VERSION ""

NS_ :

BS_:

BU_: TCM iBooster HCU CIM SCM Right_Hand_Control Left_Hand_Control GPS VCM IC_2 XM GMRS Radio_CANtool Diagnostic_Tool_Digital_Wrench Information_System_Controller_1 STEERING_CONTROLLER VEHICLE_SECURITY RADIO_Hub ABS Battery_Management_Cntrl_2 Battery_Management_Cntrl_1 Auxiliary_Power_Unit_2 Auxiliary_Power_Unit_1 Electric_Propulsion_Cntrl_Unit_4 Electric_Propulsion_Cntrl_Unit_3 Electric_Propulsion_Cntrl_Unit_2 Electric_Propulsion_Cntrl_Unit_1 ECM IC

BO_ 2566910976 FlagItems_2_0: 8 ECM
 SG_ FI2_ThrttlBdyInitLrnValSave : 52|2@1+ (1,0) [0|3] "" Vector__XXX
 SG_ FI2_ThrttlBdyInitLearnSuccess : 54|2@1+ (1,0) [0|3] "" Vector__XXX
 SG_ FI2_ThrottleLimpHomeOpCondition : 46|2@1+ (1,0) [0|3] "" Vector__XXX
 SG_ FI2_SystemOnInput : 42|2@1+ (1,0) [0|3] "" Vector__XXX
 SG_ FI2_SftyFuelCutoffCndn : 56|2@1+ (1,0) [0|3] "" Vector__XXX
 SG_ FI2_RvrsblInjCutoffCndn : 58|2@1+ (1,0) [0|3] "" Vector__XXX
 SG_ FI2_PTOEngagementStatus : 38|2@1+ (1,0) [0|3] "" Vector__XXX
 SG_ FI2_ParkBrakeSwitchIn : 36|2@1+ (1,0) [0|3] "" Vector__XXX
 SG_ FI2_NeutralSwitchIn : 44|2@1+ (1,0) [0|3] "" Vector__XXX
 SG_ FI2_IrrvrsblInjCutoffCndn : 60|2@1+ (1,0) [0|3] "" Vector__XXX
 SG_ FI2_ETCFncnMonitor : 62|2@1+ (1,0) [0|3] "" Vector__XXX
 SG_ FI2_ADCOutput : 0|2@1+ (1,0) [0|3] "" Vector__XXX
 SG_ FI2_RearDiffLockOutput : 2|2@1+ (1,0) [0|3] "" Vector__XXX
 SG_ FI2_AWDOutput : 4|2@1+ (1,0) [0|3] "" Vector__XXX
 SG_ FI2_BrakeSwitchInput : 8|2@1+ (1,0) [0|3] "" Vector__XXX
 SG_ FI2_ADCSwitchInput : 10|2@1+ (1,0) [0|3] "" Vector__XXX
 SG_ FI2_TurfModeInput : 12|2@1+ (1,0) [0|3] "" Vector__XXX
 SG_ FI2_AWDSwitchInput : 14|2@1+ (1,0) [0|3] "" Vector__XXX
 SG_ FI2_ReverseSwitchInput : 16|2@1+ (1,0) [0|3] "" Vector__XXX
 SG_ FI2_ReverseLimitSwitchInput : 18|2@1+ (1,0) [0|3] "" Vector__XXX
 SG_ FI2_ForwardLimitSwitchInput : 20|2@1+ (1,0) [0|3] "" Vector__XXX
 SG_ FI2_EngineDirection : 22|2@1+ (1,0) [0|3] "" Vector__XXX
 SG_ FI2_RevSpeedLimitOverrideInput : 24|2@1+ (1,0) [0|3] "" Vector__XXX
 SG_ FI2_ReverseOverspeedSignal : 26|2@1+ (1,0) [0|3] "" Vector__XXX
 SG_ FI2_RightTurnSignalInput : 32|2@1+ (1,0) [0|3] "" Vector__XXX
 SG_ FI2_LeftTurnSignalInput : 34|2@1+ (1,0) [0|3] "" Vector__XXX
 SG_ FI2_KickstandSwitchInput : 40|2@1+ (1,0) [0|3] "" Vector__XXX
 SG_ FI2_ReflashEnableInputSignal : 48|2@1+ (1,0) [0|3] "" Vector__XXX
 SG_ FI2_TPSLearnInputSignal : 50|2@1+ (1,0) [0|3] "" Vector__XXX
 SG_ FI2_LowRangeSwitchInput : 30|2@1+ (1,0) [0|3] "" Vector__XXX
 SG_ FI2_ReverseMotorDriveInput : 28|2@1+ (1,0) [0|3] "" Vector__XXX

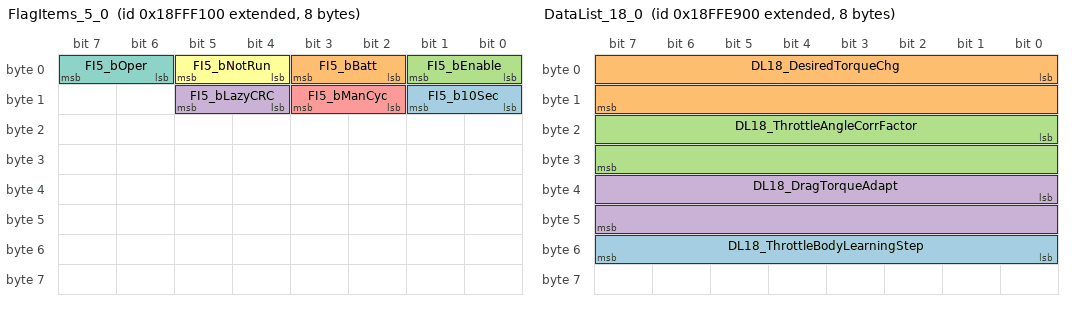
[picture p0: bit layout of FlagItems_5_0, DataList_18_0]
BO_ 2566910208 FlagItems_5_0: 8 ECM
 SG_ FI5_b10Sec : 8|2@1+ (1,0) [0|3] "Binary" Vector__XXX
 SG_ FI5_bBatt : 2|2@1+ (1,0) [0|3] "Binary" Vector__XXX
 SG_ FI5_bEnable : 0|2@1+ (1,0) [0|3] "Binary" Vector__XXX
 SG_ FI5_bLazyCRC : 12|2@1+ (1,0) [0|3] "Binary" Vector__XXX
 SG_ FI5_bManCyc : 10|2@1+ (1,0) [0|3] "Binary" Vector__XXX
 SG_ FI5_bNotRun : 4|2@1+ (1,0) [0|3] "Binary" Vector__XXX
 SG_ FI5_bOper : 6|2@1+ (1,0) [0|3] "Binary" Vector__XXX

BO_ 2566908160 DataList_18_0: 8 ECM
 SG_ DL18_ThrottleBodyLearningStep : 48|8@1+ (1,0) [0|11] "Steps" Vector__XXX
 SG_ DL18_DesiredTorqueChg : 0|16@1+ (0.0030518,-100) [-100|99.999713] "%" Vector__XXX
 SG_ DL18_ThrottleAngleCorrFactor : 16|16@1+ (6.1036E-005,0) [0|3.99999426] "" Vector__XXX
 SG_ DL18_DragTorqueAdapt : 32|16@1+ (0.0030518,-100) [-100|99.999713] "%" Vector__XXX

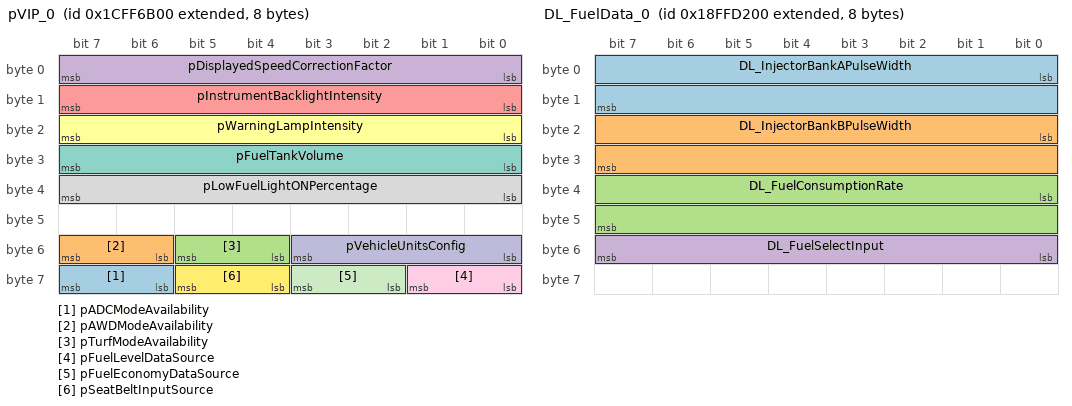
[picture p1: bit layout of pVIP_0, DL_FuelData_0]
BO_ 2633984768 pVIP_0: 8 ECM
 SG_ pADCModeAvailability : 62|2@1+ (1,0) [0|3] "" Vector__XXX
 SG_ pAWDModeAvailability : 54|2@1+ (1,0) [0|3] "" Vector__XXX
 SG_ pTurfModeAvailability : 52|2@1+ (1,0) [0|3] "" Vector__XXX
 SG_ pDisplayedSpeedCorrectionFactor : 0|8@1+ (0.8,-100) [-100|100] "%" Vector__XXX
 SG_ pInstrumentBacklightIntensity : 8|8@1+ (0.4,0) [0|100] "%" Vector__XXX
 SG_ pWarningLampIntensity : 16|8@1+ (0.4,0) [0|100] "%" Vector__XXX
 SG_ pFuelTankVolume : 24|8@1+ (0.5,0) [0|125] "Liters" Vector__XXX
 SG_ pLowFuelLightONPercentage : 32|8@1+ (0.4,0) [0|100] "Percent" Vector__XXX
 SG_ pFuelLevelDataSource : 56|2@1+ (1,0) [0|3] "" Vector__XXX
 SG_ pVehicleUnitsConfig : 48|4@1+ (1,0) [0|15] "" Vector__XXX
 SG_ pFuelEconomyDataSource : 58|2@1+ (1,0) [0|3] "" Vector__XXX
 SG_ pSeatBeltInputSource : 60|2@1+ (1,0) [0|3] "" Vector__XXX

BO_ 2566902272 DL_FuelData_0: 8 ECM
 SG_ DL_InjectorBankAPulseWidth : 0|16@1+ (0.007813,0) [0|511.99] "ms" Vector__XXX
 SG_ DL_InjectorBankBPulseWidth : 16|16@1+ (0.007813,0) [0|511.99] "ms" Vector__XXX
 SG_ DL_FuelConsumptionRate : 32|16@1+ (0.0039,0) [0|255.5865] "GPH" Vector__XXX
 SG_ DL_FuelSelectInput : 48|8@1+ (0.01953,0) [0|4.98015] "V" Vector__XXX

BO_ 2566910720 FlagItems_3_0: 8 ECM
 SG_ FI3_OilPressSwIn : 62|2@1+ (1,0) [0|3] "" Vector__XXX
 SG_ FI3_BrkSw2In : 60|2@1+ (1,0) [0|3] "" Vector__XXX
 SG_ FI3_CruiseCtrlResumeOut : 54|2@1+ (1,0) [0|3] "" Vector__XXX
 SG_ FI3_CruiseCtrlResumeIn : 56|2@1+ (1,0) [0|3] "" Vector__XXX
 SG_ FI3_CruiseCtrlCancelIn : 58|2@1+ (1,0) [0|3] "" Vector__XXX
 SG_ FI3_TetherSwStatus : 38|2@1+ (1,0) [0|3] "" Vector__XXX
 SG_ FI3_DriveMode1Input : 0|2@1+ (1,0) [0|3] "" Vector__XXX
 SG_ FI3_DriveMode2Input : 2|2@1+ (1,0) [0|3] "" Vector__XXX
 SG_ FI3_DriveMode3Input : 4|2@1+ (1,0) [0|3] "" Vector__XXX
 SG_ FI3_DriverMode4Input : 6|2@1+ (1,0) [0|3] "" Vector__XXX
 SG_ FI3_DriverMode1Output : 8|2@1+ (1,0) [0|3] "" Vector__XXX
 SG_ FI3_DriverMode2Output : 10|2@1+ (1,0) [0|3] "" Vector__XXX
 SG_ FI3_DriverMode3Output : 12|2@1+ (1,0) [0|3] "" Vector__XXX
 SG_ FI3_DriverMode4Ouput : 14|2@1+ (1,0) [0|3] "" Vector__XXX
 SG_ FI3_PTOModeInput : 16|2@1+ (1,0) [0|3] "" Vector__XXX
 SG_ FI3_PTOModeOutput : 18|2@1+ (1,0) [0|3] "" Vector__XXX
 SG_ FI3_DriversNetEngagement : 20|2@1+ (1,0) [0|3] "" Vector__XXX
 SG_ FI3_DriversSeatbeltEngagement : 22|2@1+ (1,0) [0|3] "" Vector__XXX
 SG_ FI3_TiltLockInput : 24|2@1+ (1,0) [0|3] "" Vector__XXX
 SG_ FI3_WorkGroupLockInput : 26|2@1+ (1,0) [0|3] "" Vector__XXX
 SG_ FI3_OperatorPresenceInput : 28|2@1+ (1,0) [0|3] "" Vector__XXX
 SG_ FI3_WorkGroupLockOutput : 34|2@1+ (1,0) [0|3] "" Vector__XXX
 SG_ FI3_OperatorPresenceOutput : 36|2@1+ (1,0) [0|3] "" Vector__XXX
 SG_ FI3_FootOnCruiseInput : 40|2@1+ (1,0) [0|3] "" Vector__XXX
 SG_ FI3_CruiseInput : 42|2@1+ (1,0) [0|3] "" Vector__XXX
 SG_ FI3_TredalInput : 44|2@1+ (1,0) [0|3] "" Vector__XXX
 SG_ FI3_CruiseSpeedInput : 46|2@1+ (1,0) [0|3] "" Vector__XXX
 SG_ FI3_FootOnCruiseOutput : 48|2@1+ (1,0) [0|3] "" Vector__XXX
 SG_ FI3_CruiseOutput : 50|2@1+ (1,0) [0|3] "" Vector__XXX
 SG_ FI3_CruiseControltoSetSpeed : 52|2@1+ (1,0) [0|0] "" Vector__XXX
 SG_ FI3_WorkModeInput : 30|2@1+ (1,0) [0|3] "" Vector__XXX
 SG_ FI3_TiltLockOutput : 32|2@1+ (1,0) [0|3] "" Vector__XXX

BO_ 2566910464 FlagItems_4_0: 8 ECM
 SG_ FI4_SeatbeltSw : 60|2@1+ (1,0) [0|3] "" Vector__XXX
 SG_ FI4_pSideStandSw : 52|2@1+ (1,0) [0|3] "" Vector__XXX
 SG_ FI4_DrvlnMomentaryRight : 58|2@1+ (1,0) [0|3] "" Vector__XXX
 SG_ FI4_DrvlnMomentaryLeft : 56|2@1+ (1,0) [0|3] "" Vector__XXX
 SG_ FI4_BrakeLightOutput : 30|2@1+ (1,0) [0|3] "" Vector__XXX
 SG_ FI4_FogLightInput : 4|2@1+ (1,0) [0|3] "" Vector__XXX
 SG_ FI4_HazardLightOutput : 26|2@1+ (1,0) [0|3] "" Vector__XXX
 SG_ FI4_HazardSWInput : 0|2@1+ (1,0) [0|3] "" Vector__XXX
 SG_ FI4_HeatGripDecSW : 46|2@1+ (1,0) [0|3] "" Vector__XXX
 SG_ FI4_HeatGripIncSW : 44|2@1+ (1,0) [0|3] "" Vector__XXX
 SG_ FI4_HighBeamOutput : 8|2@1+ (1,0) [0|3] "" Vector__XXX
 SG_ FI4_HornInput : 6|2@1+ (1,0) [0|3] "" Vector__XXX
 SG_ FI4_HornOutput : 24|2@1+ (1,0) [0|3] "" Vector__XXX
 SG_ FI4_LeftFogLightOutput : 12|2@1+ (1,0) [0|3] "" Vector__XXX
 SG_ FI4_LFTurnSignalOutput : 32|2@1+ (1,0) [0|3] "" Vector__XXX
 SG_ FI4_LockInput : 18|2@1+ (1,0) [0|3] "" Vector__XXX
 SG_ FI4_LowBeamOutput : 10|2@1+ (1,0) [0|3] "" Vector__XXX
 SG_ FI4_LowHighBeamInput : 2|2@1+ (1,0) [0|3] "" Vector__XXX
 SG_ FI4_LRTurnSignalOutput : 36|2@1+ (1,0) [0|3] "" Vector__XXX
 SG_ FI4_pOperatorButton1 : 48|2@1+ (1,0) [0|3] "" Vector__XXX
 SG_ FI4_RFTurnSignalOutput : 34|2@1+ (1,0) [0|3] "" Vector__XXX
 SG_ FI4_RightFogLightOutput : 14|2@1+ (1,0) [0|3] "" Vector__XXX
 SG_ FI4_RRTurnSignalOutput : 38|2@1+ (1,0) [0|3] "" Vector__XXX
 SG_ FI4_SecondaryAirValveCmd : 42|2@1+ (1,0) [0|3] "" Vector__XXX
 SG_ FI4_SecondaryAirValveOut : 40|2@1+ (1,0) [0|3] "" Vector__XXX
 SG_ FI4_TailLightOutput : 28|2@1+ (1,0) [0|3] "" Vector__XXX
 SG_ FI4_UnlockInput : 16|2@1+ (1,0) [0|3] "" Vector__XXX
 SG_ FI4_WindshieldSWDownInput : 22|2@1+ (1,0) [0|3] "" Vector__XXX
 SG_ FI4_WindshieldSWUpInput : 20|2@1+ (1,0) [0|3] "" Vector__XXX
 SG_ FI4_pOperatorButton2 : 50|2@1+ (1,0) [0|3] "" Vector__XXX

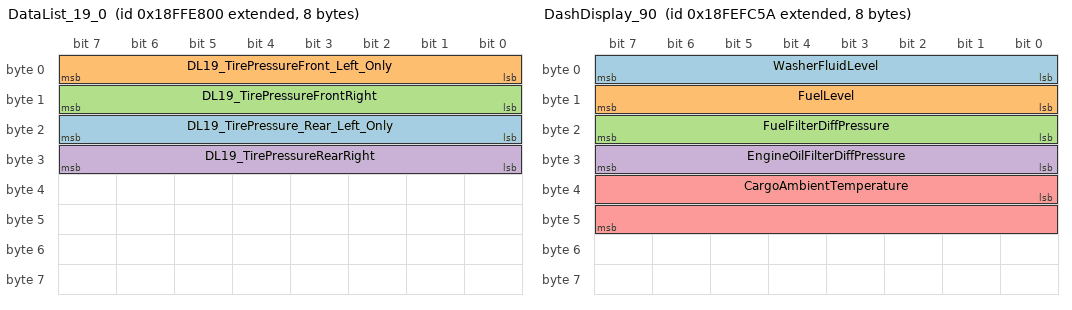
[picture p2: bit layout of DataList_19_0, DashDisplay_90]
BO_ 2566907904 DataList_19_0: 8 ECM
 SG_ DL19_TirePressure_Rear_Left_Only : 16|8@1+ (4,0) [0|1020] "kPa" Vector__XXX
 SG_ DL19_TirePressureFront_Left_Only : 0|8@1+ (4,0) [0|1020] "kPa" Vector__XXX
 SG_ DL19_TirePressureFrontRight : 8|8@1+ (4,0) [0|1020] "kPa" Vector__XXX
 SG_ DL19_TirePressureRearRight : 24|8@1+ (4,0) [0|1020] "kPa" Vector__XXX

BO_ 2566907648 DataList_20_0: 8 ECM
 SG_ DL20_KeyFobBatteryVoltage : 0|8@1+ (0.1,0) [0|25.5] "Volts" Vector__XXX
 SG_ DL20_LeanAngle : 8|8@1+ (1,-125) [-125|130] "Degrees" Vector__XXX

BO_ 2566847578 DashDisplay_90: 8 HCU
 SG_ WasherFluidLevel : 0|8@1+ (0.4,0) [0|100] "%" Vector__XXX
 SG_ FuelLevel : 8|8@1+ (0.4,0) [0|100] "%" Vector__XXX
 SG_ FuelFilterDiffPressure : 16|8@1+ (2,0) [0|500] "kPa" Vector__XXX
 SG_ EngineOilFilterDiffPressure : 24|8@1+ (0.5,0) [0|125] "kPa" Vector__XXX
 SG_ CargoAmbientTemperature : 32|16@1+ (0.03125,-273) [-273|1735] "°C" Vector__XXX

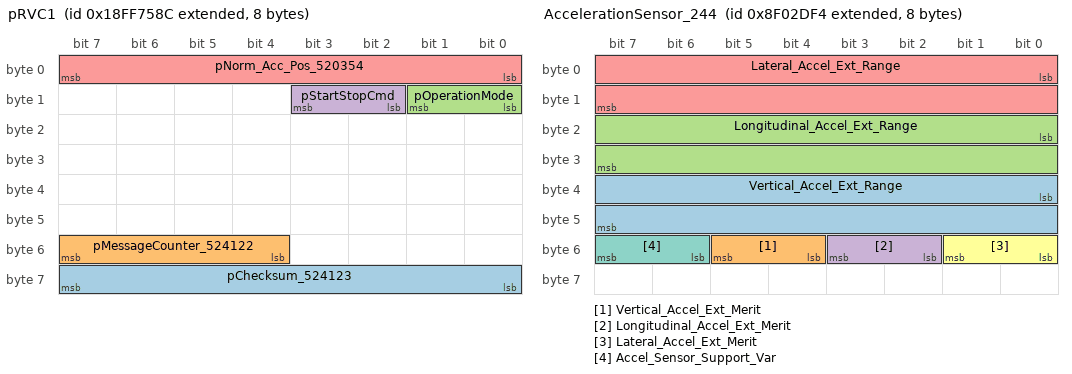
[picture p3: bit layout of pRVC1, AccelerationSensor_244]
BO_ 2566878604 pRVC1: 8 CIM
 SG_ pChecksum_524123 : 56|8@1+ (1,0) [0|255] "" Vector__XXX
 SG_ pMessageCounter_524122 : 52|4@1+ (1,0) [0|15] "" Vector__XXX
 SG_ pOperationMode : 8|2@1+ (1,0) [0|0] "" Vector__XXX
 SG_ pStartStopCmd : 10|2@1+ (1,0) [0|3] "" Vector__XXX
 SG_ pNorm_Acc_Pos_520354 : 0|8@1+ (0.4,0) [0|102] "Percent" Vector__XXX

BO_ 2566878464 pEngineControlRequests: 8 ECM
 SG_ pStartStopCmd : 10|2@1+ (1,0) [0|3] "" Vector__XXX
 SG_ pPedalPositionCommand : 0|8@1+ (0.4,0) [0|102] "%" Vector__XXX
 SG_ pOperationMode : 8|2@1+ (1,0) [0|0] "" Vector__XXX

BO_ 2566876928 pEngineRequests1: 8 ECM
 SG_ pSecondaryAirValveControl : 0|2@1+ (1,0) [0|3] "" Vector__XXX

BO_ 2566853886 pWattMessage: 8 HCU
 SG_ pRangeToEmptyEV : 16|16@1+ (0.1,0) [0|6425.5] "km" Vector__XXX
 SG_ pEfficiencyEV : 0|16@1+ (0.1,0) [0|6425.5] "Wh/km" Vector__XXX

BO_ 2566876416 pDriveModeETC: 8 ECM
 SG_ pDriveModeCommanded : 16|8@1+ (1,0) [0|255] "" Vector__XXX
 SG_ pFootOnCruiseControlEnabled : 8|2@1+ (1,0) [0|3] "" Vector__XXX
 SG_ pDriveModeRequested : 0|8@1+ (1,0) [0|255] "" Vector__XXX

BO_ 2566825472 IntakeManifoldInformation1: 8 ECM
 SG_ EngineTurbo1BoostPressure : 0|16@1+ (0.125,0) [0|8031.875] "kPa" Vector__XXX

BO_ 2566804212 VehicleElectricalPower3_244: 8 Battery_Management_Cntrl_2
 SG_ NetBattCurrentHiRange : 16|16@1+ (0.05,0) [0|3276.75] "A" Vector__XXX

BO_ 2566804211 VehicleElectricalPower3_243: 8 Battery_Management_Cntrl_1
 SG_ NetBattCurrentHiRange : 16|16@1+ (0.05,0) [0|3276.75] "A" Vector__XXX

BO_ 2297441780 AccelerationSensor_244: 8 Battery_Management_Cntrl_2
 SG_ Vertical_Accel_Ext_Range : 32|16@1+ (0.01,-320) [-320|322.55] "m/s2" Vector__XXX
 SG_ Vertical_Accel_Ext_Merit : 52|2@1+ (1,0) [0|3] "" Vector__XXX
 SG_ Longitudinal_Accel_Ext_Range : 16|16@1+ (0.01,-320) [-320|322.55] "m/s2" Vector__XXX
 SG_ Longitudinal_Accel_Ext_Merit : 50|2@1+ (1,0) [0|3] "" Vector__XXX
 SG_ Lateral_Accel_Ext_Range : 0|16@1+ (0.01,-320) [-320|322.55] "m/s2" Vector__XXX
 SG_ Lateral_Accel_Ext_Merit : 48|2@1+ (1,0) [0|3] "" Vector__XXX
 SG_ Accel_Sensor_Support_Var : 54|2@1+ (1,0) [0|3] "" Vector__XXX

BO_ 2566846452 WATT_Veh_Electrical_Pwr_244: 8 Battery_Management_Cntrl_2
 SG_ Net_Battery_Current : 0|8@1+ (1,-125) [-125|125] "A" Vector__XXX
 SG_ BatteryPotential : 16|16@1+ (0.05,0) [0|3212.75] "V" Vector__XXX

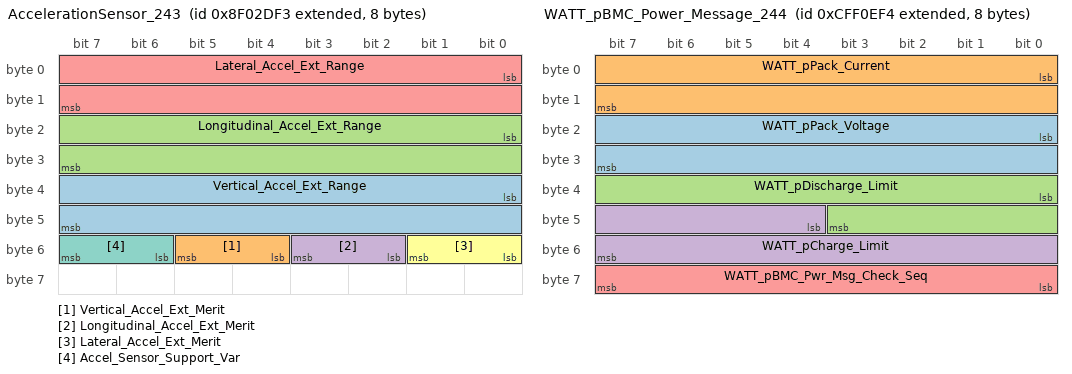
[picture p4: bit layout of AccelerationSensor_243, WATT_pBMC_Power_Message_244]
BO_ 2297441779 AccelerationSensor_243: 8 Battery_Management_Cntrl_1
 SG_ Vertical_Accel_Ext_Range : 32|16@1+ (0.01,-320) [-320|322.55] "m/s2" Vector__XXX
 SG_ Vertical_Accel_Ext_Merit : 52|2@1+ (1,0) [0|3] "" Vector__XXX
 SG_ Longitudinal_Accel_Ext_Range : 16|16@1+ (0.01,-320) [-320|322.55] "m/s2" Vector__XXX
 SG_ Longitudinal_Accel_Ext_Merit : 50|2@1+ (1,0) [0|3] "" Vector__XXX
 SG_ Lateral_Accel_Ext_Range : 0|16@1+ (0.01,-320) [-320|322.55] "m/s2" Vector__XXX
 SG_ Lateral_Accel_Ext_Merit : 48|2@1+ (1,0) [0|3] "" Vector__XXX
 SG_ Accel_Sensor_Support_Var : 54|2@1+ (1,0) [0|3] "" Vector__XXX

BO_ 2566846451 WATT_Veh_Electrical_Pwr_243: 8 Battery_Management_Cntrl_1
 SG_ Net_Battery_Current : 0|8@1+ (1,-125) [-125|125] "A" Vector__XXX
 SG_ BatteryPotential : 16|16@1+ (0.05,0) [0|3212.75] "V" Vector__XXX

BO_ 2365525748 WATT_pBMC_Power_Message_244: 8 Battery_Management_Cntrl_2
 SG_ WATT_pPack_Voltage : 16|16@1+ (0.05,0) [0|3212.75] "V" Vector__XXX
 SG_ WATT_pPack_Current : 0|16@1+ (0.05,-1600) [-1600|1612.75] "A" Vector__XXX
 SG_ WATT_pDischarge_Limit : 32|12@1+ (0.5,0) [0|2007.5] "A" Vector__XXX
 SG_ WATT_pCharge_Limit : 44|12@1+ (0.5,0) [0|2007.5] "A" Vector__XXX
 SG_ WATT_pBMC_Pwr_Msg_Check_Seq : 56|8@1+ (1,0) [0|255] "" Vector__XXX

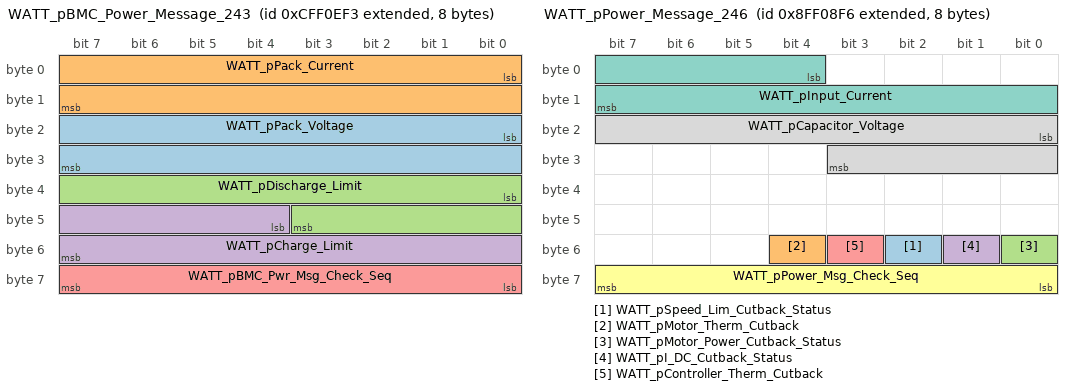
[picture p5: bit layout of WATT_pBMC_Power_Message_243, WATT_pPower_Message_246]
BO_ 2365525747 WATT_pBMC_Power_Message_243: 8 Battery_Management_Cntrl_1
 SG_ WATT_pPack_Voltage : 16|16@1+ (0.05,0) [0|3212.75] "V" Vector__XXX
 SG_ WATT_pPack_Current : 0|16@1+ (0.05,-1600) [-1600|1612.75] "A" Vector__XXX
 SG_ WATT_pDischarge_Limit : 32|12@1+ (0.5,0) [0|2007.5] "A" Vector__XXX
 SG_ WATT_pCharge_Limit : 44|12@1+ (0.5,0) [0|2007.5] "A" Vector__XXX
 SG_ WATT_pBMC_Pwr_Msg_Check_Seq : 56|8@1+ (1,0) [0|255] "" Vector__XXX

BO_ 2298415350 WATT_pPower_Message_246: 8 Auxiliary_Power_Unit_2
 SG_ WATT_pSpeed_Lim_Cutback_Status : 50|1@1+ (1,0) [0|1] "" Vector__XXX
 SG_ WATT_pMotor_Therm_Cutback : 52|1@1+ (1,0) [0|1] "" Vector__XXX
 SG_ WATT_pMotor_Power_Cutback_Status : 48|1@1+ (1,0) [0|1] "" Vector__XXX
 SG_ WATT_pI_DC_Cutback_Status : 49|1@1+ (1,0) [0|1] "" Vector__XXX
 SG_ WATT_pController_Therm_Cutback : 51|1@1+ (1,0) [0|1] "" Vector__XXX
 SG_ WATT_pPower_Msg_Check_Seq : 56|8@1+ (1,0) [0|255] "" Vector__XXX
 SG_ WATT_pInput_Current : 4|12@1+ (1,0) [0|4095] "" Vector__XXX
 SG_ WATT_pCapacitor_Voltage : 16|12@1+ (1,0) [0|4095] "" Vector__XXX

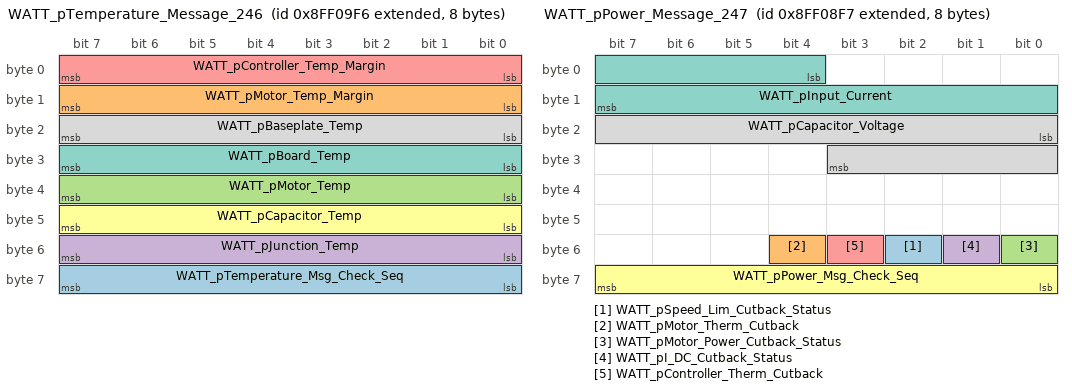
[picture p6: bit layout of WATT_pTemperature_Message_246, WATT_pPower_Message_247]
BO_ 2298415606 WATT_pTemperature_Message_246: 8 Auxiliary_Power_Unit_2
 SG_ WATT_pTemperature_Msg_Check_Seq : 56|8@1+ (1,0) [0|255] "" Vector__XXX
 SG_ WATT_pMotor_Temp_Margin : 8|8@1+ (1,0) [0|250] "C" Vector__XXX
 SG_ WATT_pMotor_Temp : 32|8@1+ (1,-40) [-40|210] "C" Vector__XXX
 SG_ WATT_pJunction_Temp : 48|8@1+ (1,-40) [-40|210] "C" Vector__XXX
 SG_ WATT_pController_Temp_Margin : 0|8@1+ (1,0) [0|250] "C" Vector__XXX
 SG_ WATT_pCapacitor_Temp : 40|8@1+ (1,-40) [-40|210] "C" Vector__XXX
 SG_ WATT_pBoard_Temp : 24|8@1+ (1,-40) [-40|210] "C" Vector__XXX
 SG_ WATT_pBaseplate_Temp : 16|8@1+ (1,-40) [-40|210] "C" Vector__XXX

BO_ 2298415351 WATT_pPower_Message_247: 8 Auxiliary_Power_Unit_1
 SG_ WATT_pSpeed_Lim_Cutback_Status : 50|1@1+ (1,0) [0|1] "" Vector__XXX
 SG_ WATT_pMotor_Therm_Cutback : 52|1@1+ (1,0) [0|1] "" Vector__XXX
 SG_ WATT_pMotor_Power_Cutback_Status : 48|1@1+ (1,0) [0|1] "" Vector__XXX
 SG_ WATT_pI_DC_Cutback_Status : 49|1@1+ (1,0) [0|1] "" Vector__XXX
 SG_ WATT_pController_Therm_Cutback : 51|1@1+ (1,0) [0|1] "" Vector__XXX
 SG_ WATT_pPower_Msg_Check_Seq : 56|8@1+ (1,0) [0|255] "" Vector__XXX
 SG_ WATT_pInput_Current : 4|12@1+ (1,0) [0|4095] "" Vector__XXX
 SG_ WATT_pCapacitor_Voltage : 16|12@1+ (1,0) [0|4095] "" Vector__XXX

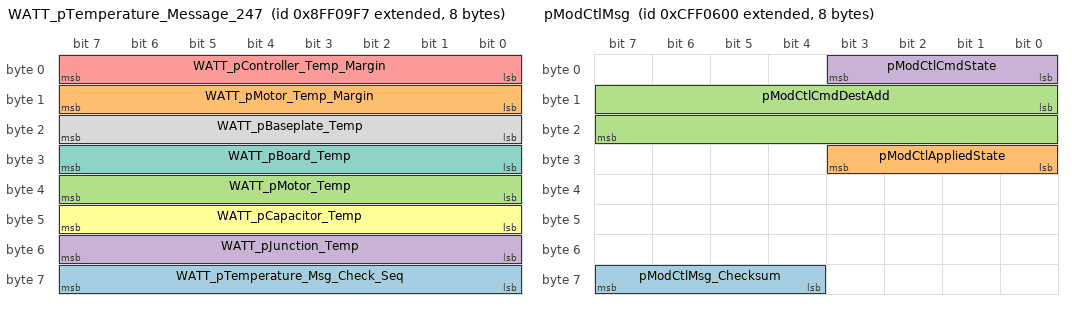
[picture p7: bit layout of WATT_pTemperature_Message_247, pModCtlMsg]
BO_ 2298415607 WATT_pTemperature_Message_247: 8 Auxiliary_Power_Unit_1
 SG_ WATT_pTemperature_Msg_Check_Seq : 56|8@1+ (1,0) [0|255] "" Vector__XXX
 SG_ WATT_pMotor_Temp_Margin : 8|8@1+ (1,0) [0|250] "C" Vector__XXX
 SG_ WATT_pMotor_Temp : 32|8@1+ (1,-40) [-40|210] "C" Vector__XXX
 SG_ WATT_pJunction_Temp : 48|8@1+ (1,-40) [-40|210] "C" Vector__XXX
 SG_ WATT_pController_Temp_Margin : 0|8@1+ (1,0) [0|250] "C" Vector__XXX
 SG_ WATT_pCapacitor_Temp : 40|8@1+ (1,-40) [-40|210] "C" Vector__XXX
 SG_ WATT_pBoard_Temp : 24|8@1+ (1,-40) [-40|210] "C" Vector__XXX
 SG_ WATT_pBaseplate_Temp : 16|8@1+ (1,-40) [-40|210] "C" Vector__XXX

BO_ 2365523456 pModCtlMsg: 8 ECM
 SG_ pModCtlMsg_Checksum : 60|4@1+ (1,0) [0|0] "" Vector__XXX
 SG_ pModCtlAppliedState : 24|4@1+ (1,0) [0|0] "" Vector__XXX
 SG_ pModCtlCmdDestAdd : 8|16@1+ (1,0) [0|65535] "Address" Vector__XXX
 SG_ pModCtlCmdState : 0|4@1+ (1,0) [0|15] "" Vector__XXX

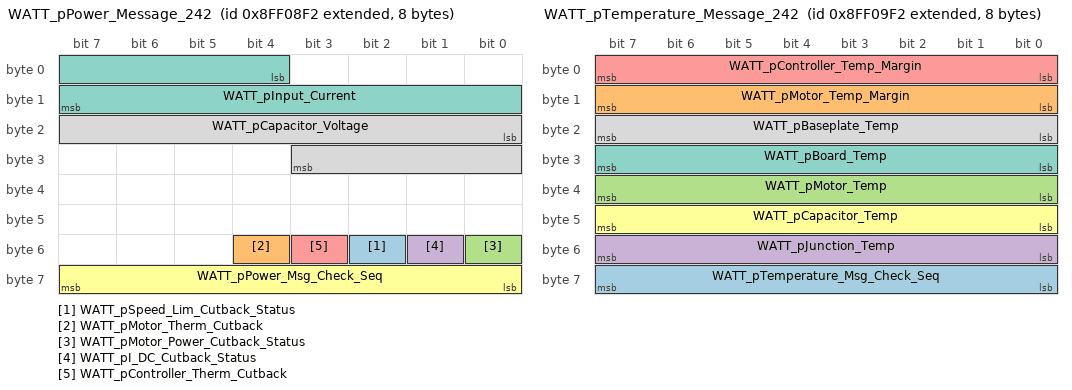
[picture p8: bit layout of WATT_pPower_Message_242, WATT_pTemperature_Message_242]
BO_ 2298415346 WATT_pPower_Message_242: 8 Electric_Propulsion_Cntrl_Unit_4
 SG_ WATT_pSpeed_Lim_Cutback_Status : 50|1@1+ (1,0) [0|1] "" Vector__XXX
 SG_ WATT_pMotor_Therm_Cutback : 52|1@1+ (1,0) [0|1] "" Vector__XXX
 SG_ WATT_pMotor_Power_Cutback_Status : 48|1@1+ (1,0) [0|1] "" Vector__XXX
 SG_ WATT_pI_DC_Cutback_Status : 49|1@1+ (1,0) [0|1] "" Vector__XXX
 SG_ WATT_pController_Therm_Cutback : 51|1@1+ (1,0) [0|1] "" Vector__XXX
 SG_ WATT_pPower_Msg_Check_Seq : 56|8@1+ (1,0) [0|255] "" Vector__XXX
 SG_ WATT_pInput_Current : 4|12@1+ (1,0) [0|4095] "" Vector__XXX
 SG_ WATT_pCapacitor_Voltage : 16|12@1+ (1,0) [0|4095] "" Vector__XXX

BO_ 2298415602 WATT_pTemperature_Message_242: 8 Electric_Propulsion_Cntrl_Unit_4
 SG_ WATT_pTemperature_Msg_Check_Seq : 56|8@1+ (1,0) [0|255] "" Vector__XXX
 SG_ WATT_pMotor_Temp_Margin : 8|8@1+ (1,0) [0|250] "C" Vector__XXX
 SG_ WATT_pMotor_Temp : 32|8@1+ (1,-40) [-40|210] "C" Vector__XXX
 SG_ WATT_pJunction_Temp : 48|8@1+ (1,-40) [-40|210] "C" Vector__XXX
 SG_ WATT_pController_Temp_Margin : 0|8@1+ (1,0) [0|250] "C" Vector__XXX
 SG_ WATT_pCapacitor_Temp : 40|8@1+ (1,-40) [-40|210] "C" Vector__XXX
 SG_ WATT_pBoard_Temp : 24|8@1+ (1,-40) [-40|210] "C" Vector__XXX
 SG_ WATT_pBaseplate_Temp : 16|8@1+ (1,-40) [-40|210] "C" Vector__XXX

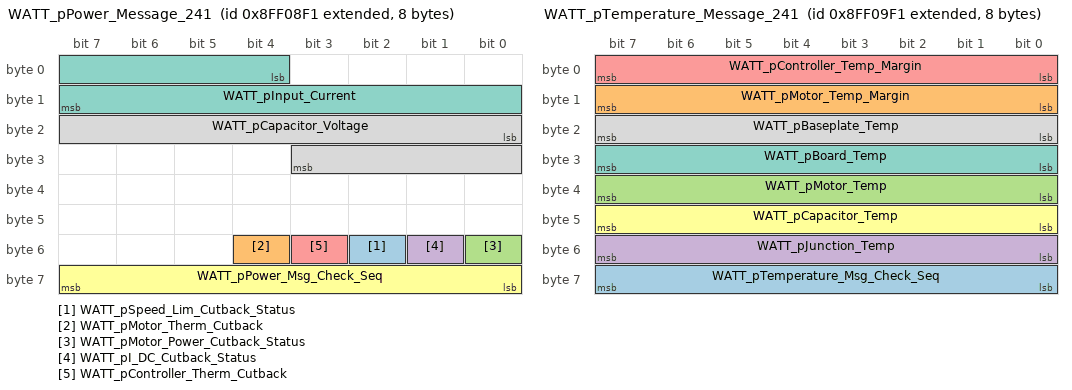
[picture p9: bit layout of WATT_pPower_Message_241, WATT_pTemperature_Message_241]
BO_ 2298415345 WATT_pPower_Message_241: 8 Electric_Propulsion_Cntrl_Unit_3
 SG_ WATT_pSpeed_Lim_Cutback_Status : 50|1@1+ (1,0) [0|1] "" Vector__XXX
 SG_ WATT_pMotor_Therm_Cutback : 52|1@1+ (1,0) [0|1] "" Vector__XXX
 SG_ WATT_pMotor_Power_Cutback_Status : 48|1@1+ (1,0) [0|1] "" Vector__XXX
 SG_ WATT_pI_DC_Cutback_Status : 49|1@1+ (1,0) [0|1] "" Vector__XXX
 SG_ WATT_pController_Therm_Cutback : 51|1@1+ (1,0) [0|1] "" Vector__XXX
 SG_ WATT_pPower_Msg_Check_Seq : 56|8@1+ (1,0) [0|255] "" Vector__XXX
 SG_ WATT_pInput_Current : 4|12@1+ (1,0) [0|4095] "" Vector__XXX
 SG_ WATT_pCapacitor_Voltage : 16|12@1+ (1,0) [0|4095] "" Vector__XXX

BO_ 2298415601 WATT_pTemperature_Message_241: 8 Electric_Propulsion_Cntrl_Unit_3
 SG_ WATT_pTemperature_Msg_Check_Seq : 56|8@1+ (1,0) [0|255] "" Vector__XXX
 SG_ WATT_pMotor_Temp_Margin : 8|8@1+ (1,0) [0|250] "C" Vector__XXX
 SG_ WATT_pMotor_Temp : 32|8@1+ (1,-40) [-40|210] "C" Vector__XXX
 SG_ WATT_pJunction_Temp : 48|8@1+ (1,-40) [-40|210] "C" Vector__XXX
 SG_ WATT_pController_Temp_Margin : 0|8@1+ (1,0) [0|250] "C" Vector__XXX
 SG_ WATT_pCapacitor_Temp : 40|8@1+ (1,-40) [-40|210] "C" Vector__XXX
 SG_ WATT_pBoard_Temp : 24|8@1+ (1,-40) [-40|210] "C" Vector__XXX
 SG_ WATT_pBaseplate_Temp : 16|8@1+ (1,-40) [-40|210] "C" Vector__XXX

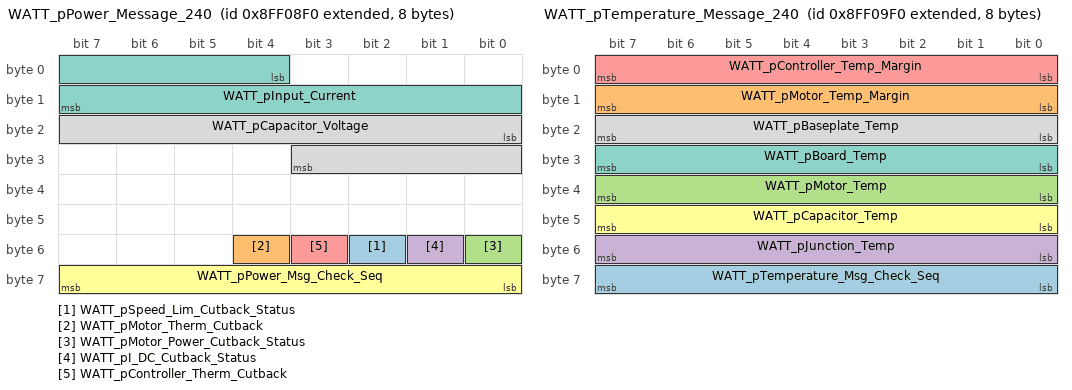
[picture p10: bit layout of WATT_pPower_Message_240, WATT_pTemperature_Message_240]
BO_ 2298415344 WATT_pPower_Message_240: 8 Electric_Propulsion_Cntrl_Unit_2
 SG_ WATT_pSpeed_Lim_Cutback_Status : 50|1@1+ (1,0) [0|1] "" Vector__XXX
 SG_ WATT_pMotor_Therm_Cutback : 52|1@1+ (1,0) [0|1] "" Vector__XXX
 SG_ WATT_pMotor_Power_Cutback_Status : 48|1@1+ (1,0) [0|1] "" Vector__XXX
 SG_ WATT_pI_DC_Cutback_Status : 49|1@1+ (1,0) [0|1] "" Vector__XXX
 SG_ WATT_pController_Therm_Cutback : 51|1@1+ (1,0) [0|1] "" Vector__XXX
 SG_ WATT_pPower_Msg_Check_Seq : 56|8@1+ (1,0) [0|255] "" Vector__XXX
 SG_ WATT_pInput_Current : 4|12@1+ (1,0) [0|4095] "" Vector__XXX
 SG_ WATT_pCapacitor_Voltage : 16|12@1+ (1,0) [0|4095] "" Vector__XXX

BO_ 2298415600 WATT_pTemperature_Message_240: 8 Electric_Propulsion_Cntrl_Unit_2
 SG_ WATT_pTemperature_Msg_Check_Seq : 56|8@1+ (1,0) [0|255] "" Vector__XXX
 SG_ WATT_pMotor_Temp_Margin : 8|8@1+ (1,0) [0|250] "C" Vector__XXX
 SG_ WATT_pMotor_Temp : 32|8@1+ (1,-40) [-40|210] "C" Vector__XXX
 SG_ WATT_pJunction_Temp : 48|8@1+ (1,-40) [-40|210] "C" Vector__XXX
 SG_ WATT_pController_Temp_Margin : 0|8@1+ (1,0) [0|250] "C" Vector__XXX
 SG_ WATT_pCapacitor_Temp : 40|8@1+ (1,-40) [-40|210] "C" Vector__XXX
 SG_ WATT_pBoard_Temp : 24|8@1+ (1,-40) [-40|210] "C" Vector__XXX
 SG_ WATT_pBaseplate_Temp : 16|8@1+ (1,-40) [-40|210] "C" Vector__XXX

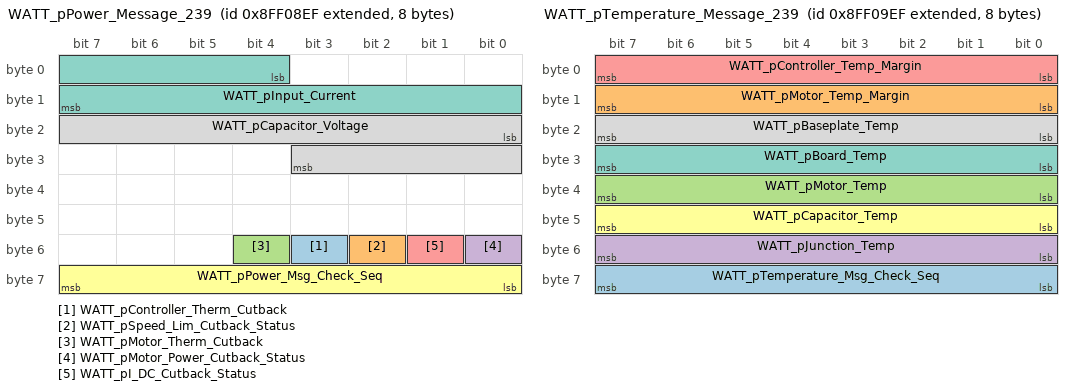
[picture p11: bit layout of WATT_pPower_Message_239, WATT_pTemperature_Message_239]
BO_ 2298415343 WATT_pPower_Message_239: 8 Electric_Propulsion_Cntrl_Unit_1
 SG_ WATT_pController_Therm_Cutback : 51|1@1+ (1,0) [0|1] "" Vector__XXX
 SG_ WATT_pSpeed_Lim_Cutback_Status : 50|1@1+ (1,0) [0|1] "" Vector__XXX
 SG_ WATT_pMotor_Therm_Cutback : 52|1@1+ (1,0) [0|1] "" Vector__XXX
 SG_ WATT_pMotor_Power_Cutback_Status : 48|1@1+ (1,0) [0|1] "" Vector__XXX
 SG_ WATT_pI_DC_Cutback_Status : 49|1@1+ (1,0) [0|1] "" Vector__XXX
 SG_ WATT_pPower_Msg_Check_Seq : 56|8@1+ (1,0) [0|255] "" Vector__XXX
 SG_ WATT_pInput_Current : 4|12@1+ (1,0) [0|4095] "" Vector__XXX
 SG_ WATT_pCapacitor_Voltage : 16|12@1+ (1,0) [0|4095] "" Vector__XXX

BO_ 2298415599 WATT_pTemperature_Message_239: 8 Electric_Propulsion_Cntrl_Unit_1
 SG_ WATT_pTemperature_Msg_Check_Seq : 56|8@1+ (1,0) [0|255] "" Vector__XXX
 SG_ WATT_pMotor_Temp_Margin : 8|8@1+ (1,0) [0|250] "C" Vector__XXX
 SG_ WATT_pMotor_Temp : 32|8@1+ (1,-40) [-40|210] "C" Vector__XXX
 SG_ WATT_pJunction_Temp : 48|8@1+ (1,-40) [-40|210] "C" Vector__XXX
 SG_ WATT_pController_Temp_Margin : 0|8@1+ (1,0) [0|250] "C" Vector__XXX
 SG_ WATT_pCapacitor_Temp : 40|8@1+ (1,-40) [-40|210] "C" Vector__XXX
 SG_ WATT_pBoard_Temp : 24|8@1+ (1,-40) [-40|210] "C" Vector__XXX
 SG_ WATT_pBaseplate_Temp : 16|8@1+ (1,-40) [-40|210] "C" Vector__XXX

BO_ 2566845696 AmbientConditions_0: 8 ECM
 SG_ DL_BarometricPressure : 0|16@1+ (0.007813,0) [0|511.99] "kPa"  IC
 SG_ CabInteriorTemperature : 8|16@1+ (0.03125,-273) [-273|1735] "°C"  IC
 SG_ AmbientAirTemperature : 24|16@1+ (0.03125,-273) [-273|1735] "°C"  IC
 SG_ EngineAirInletTemperature : 40|8@1+ (1,-40) [-40|210] "°C"  IC
 SG_ RoadSurfaceTemperature : 48|16@1+ (0.03125,-273) [-273|1734.96875] "°C"  IC

BO_ 2566844672 CruiseControlVehSpeed_0: 8 ECM
 SG_ TwoSpeedAxleSwitch : 0|2@1+ (1,0) [0|3] ""  IC
 SG_ ParkingBrakeSwitch : 2|2@1+ (1,0) [0|3] ""  IC
 SG_ Wheel_BasedVehicleSpeed : 8|16@1+ (0.00390625,0) [0|251] "km/h"  IC
 SG_ CruiseCtrlActive : 24|2@1+ (1,0) [0|3] ""  IC
 SG_ CruiseCtrlEnableSwitch : 26|2@1+ (1,0) [0|3] ""  IC
 SG_ BrakeSwitch : 28|2@1+ (1,0) [0|3] ""  IC
 SG_ ClutchSwitch : 30|2@1+ (1,0) [0|3] ""  IC
 SG_ CruiseCtrlSetSwitch : 32|2@1+ (1,0) [0|3] ""  IC
 SG_ CruiseCtrlCoastSwitch : 34|2@1+ (1,0) [0|3] ""  IC
 SG_ CruiseCtrlResumeSwitch : 36|2@1+ (1,0) [0|3] ""  IC
 SG_ CruiseCtrlAccelerateSwitch : 38|2@1+ (1,0) [0|3] ""  IC
 SG_ CruiseCtrlSetSpeed : 40|8@1+ (1,0) [0|250] "km/h"  IC
 SG_ pOdometerDriveBit : 6|2@1+ (1,0) [0|3] ""  IC
 SG_ CruiseCtrlPauseSw : 4|2@1+ (1,0) [0|3] ""  IC
 SG_ pCCMessageCounter : 52|4@1+ (1,0) [0|15] ""  IC
 SG_ pCCChecksum : 56|8@1+ (1,0) [0|255] ""  IC
 SG_ pCruiseEnableStatus : 48|4@1+ (1,0) [0|15] ""  IC

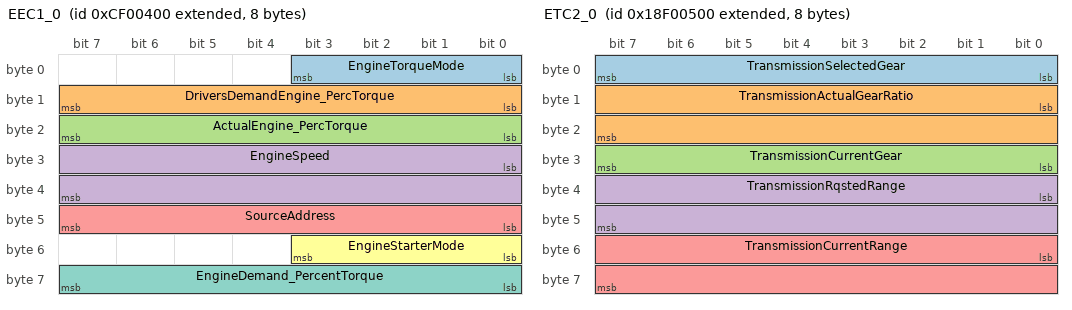
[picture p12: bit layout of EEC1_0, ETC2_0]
BO_ 2364539904 EEC1_0: 8 ECM
 SG_ EngineTorqueMode : 0|4@1+ (1,0) [0|13] ""  IC
 SG_ DriversDemandEngine_PercTorque : 8|8@1+ (1,-125) [-125|125] "%"  IC
 SG_ ActualEngine_PercTorque : 16|8@1+ (1,-125) [-125|125] "%"  IC
 SG_ EngineSpeed : 24|16@1+ (0.125,0) [0|8031.88] "rpm"  IC
 SG_ SourceAddress : 40|8@1+ (1,0) [0|253] ""  IC
 SG_ EngineStarterMode : 48|4@1+ (1,0) [0|15] ""  IC
 SG_ EngineDemand_PercentTorque : 56|8@1+ (1,-125) [-125|130] "%"  IC

BO_ 2565866752 ETC2_0: 8 ECM
 SG_ TransmissionSelectedGear : 0|8@1+ (1,-125) [-125|125] ""  IC
 SG_ TransmissionActualGearRatio : 8|16@1+ (0.001,0) [0|64.255] ""  IC
 SG_ TransmissionCurrentGear : 24|8@1+ (1,-125) [-125|125] ""  IC
 SG_ TransmissionRqstedRange : 32|16@1+ (1,0) [0|65535] ""  IC
 SG_ TransmissionCurrentRange : 48|16@1+ (1,0) [0|65535] ""  IC

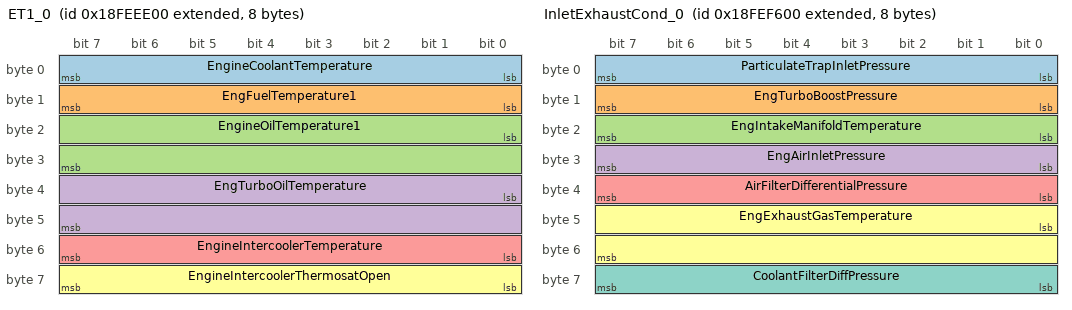
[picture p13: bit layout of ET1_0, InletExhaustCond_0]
BO_ 2566843904 ET1_0: 8 ECM
 SG_ EngineCoolantTemperature : 0|8@1+ (1,-40) [-40|210] "°C"  IC
 SG_ EngFuelTemperature1 : 8|8@1+ (1,-40) [-40|210] "°C"  IC
 SG_ EngineOilTemperature1 : 16|16@1+ (0.03125,-273) [-273|1734.96875] "°C"  IC
 SG_ EngTurboOilTemperature : 32|16@1+ (0.03125,-273) [-273|1734.96875] "°C"  IC
 SG_ EngineIntercoolerTemperature : 48|8@1+ (1,-40) [-40|210] "°C"  IC
 SG_ EngineIntercoolerThermosatOpen : 56|8@1+ (0.4,0) [0|100] "%"  IC

BO_ 2566844928 FuelEconomy_0: 8 ECM
 SG_ EngineFuelRate : 0|16@1+ (0.05,0) [0|3212.75] "L/h"  IC
 SG_ InstantaneousFuelEconomy : 16|16@1+ (0.00195312,0) [0|125.5] "km"  IC
 SG_ AverageFuelEconomy : 32|16@1+ (0.00195312,0) [0|125.5] "km"  IC
 SG_ EngineThrottlePosition : 48|8@1+ (0.4,0) [0|100] "%"  IC

BO_ 2566845952 InletExhaustCond_0: 8 ECM
 SG_ ParticulateTrapInletPressure : 0|8@1+ (0.5,0) [0|125] "kPa"  IC
 SG_ EngTurboBoostPressure : 8|8@1+ (2,0) [0|500] "kPa"  IC
 SG_ EngIntakeManifoldTemperature : 16|8@1+ (1,-40) [-40|210] "°C"  IC
 SG_ EngAirInletPressure : 24|8@1+ (2,0) [0|500] "kPa"  IC
 SG_ AirFilterDifferentialPressure : 32|8@1+ (0.05,0) [0|12.5] "kPa"  IC
 SG_ EngExhaustGasTemperature : 40|16@1+ (0.03125,-273) [-273|1734.96875] "°C"  IC
 SG_ CoolantFilterDiffPressure : 56|8@1+ (0.5,0) [0|125] "kPa"  IC

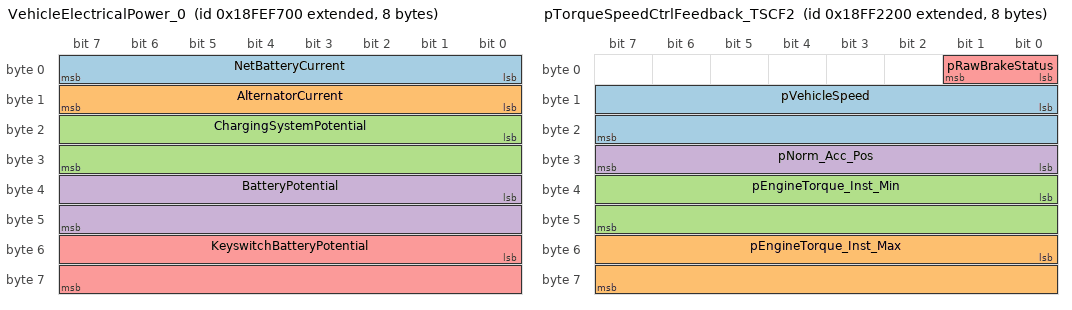
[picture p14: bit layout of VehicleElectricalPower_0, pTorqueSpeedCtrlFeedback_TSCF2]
BO_ 2566846208 VehicleElectricalPower_0: 8 ECM
 SG_ NetBatteryCurrent : 0|8@1+ (1,-125) [-125|125] "A"  IC
 SG_ AlternatorCurrent : 8|8@1+ (1,0) [0|250] "A"  IC
 SG_ ChargingSystemPotential : 16|16@1+ (0.05,0) [0|3212.75] "V"  IC
 SG_ BatteryPotential : 32|16@1+ (0.05,0) [0|3212.75] "V"  IC
 SG_ KeyswitchBatteryPotential : 48|16@1+ (0.05,0) [0|3212.75] "V"  IC

BO_ 2566844806 CruiseControlVehSpeed: 8 Right_Hand_Control
 SG_ pCruiseCntrlCounter : 50|4@1+ (1,0) [0|15] "" Vector__XXX
 SG_ TwoSpeedAxleSwitch : 0|2@1+ (1,0) [0|3] "" Vector__XXX
 SG_ ParkingBrakeSwitch : 2|2@1+ (1,0) [0|3] "" Vector__XXX
 SG_ Wheel_BasedVehicleSpeed : 8|16@1+ (0.00390625,0) [0|251] "km/h" Vector__XXX
 SG_ CruiseCtrlActive : 24|2@1+ (1,0) [0|3] "" Vector__XXX
 SG_ CruiseCtrlEnableSwitch : 26|2@1+ (1,0) [0|3] "" Vector__XXX
 SG_ BrakeSwitch : 28|2@1+ (1,0) [0|3] "" Vector__XXX
 SG_ ClutchSwitch : 30|2@1+ (1,0) [0|3] "" Vector__XXX
 SG_ CruiseCtrlSetSwitch : 32|2@1+ (1,0) [0|3] "" Vector__XXX
 SG_ CruiseCtrlCoastSwitch : 34|2@1+ (1,0) [0|3] "" Vector__XXX
 SG_ CruiseCtrlResumeSwitch : 36|2@1+ (1,0) [0|3] "" Vector__XXX
 SG_ CruiseCtrlAccelerateSwitch : 38|2@1+ (1,0) [0|3] "" Vector__XXX
 SG_ CruiseCtrlSetSpeed : 40|8@1+ (1,0) [0|250] "km/h" Vector__XXX
 SG_ pOdometerDriveBit : 6|2@1+ (1,0) [0|3] "" Vector__XXX
 SG_ CruiseCtrlPauseSw : 4|2@1+ (1,0) [0|3] "" Vector__XXX
 SG_ pCCChecksum : 56|8@1+ (1,0) [0|255] "" Vector__XXX
 SG_ pCruiseEnableStatus : 48|4@1+ (1,0) [0|15] "" Vector__XXX

BO_ 2565537345 RequestPGN: 3 Information_System_Controller_1
 SG_ RqstedPGN : 0|24@1+ (1,0) [0|16777200] "" Vector__XXX

BO_ 2566857216 pTorqueSpeedCtrlFeedback_TSCF2: 8 ECM
 SG_ pVehicleSpeed : 8|16@1+ (0.00390625,0) [0|250.996] "km/h" Vector__XXX
 SG_ pEngineTorque_Inst_Max : 48|16@1- (0.03125,0) [-400|1607.96875] "Nm" Vector__XXX
 SG_ pEngineTorque_Inst_Min : 32|16@1- (0.03125,0) [-400|1607.96875] "Nm" Vector__XXX
 SG_ pNorm_Acc_Pos : 24|8@1+ (0.4,0) [0|100] "Percent" Vector__XXX
 SG_ pRawBrakeStatus : 0|2@1+ (1,0) [0|3] "state" Vector__XXX

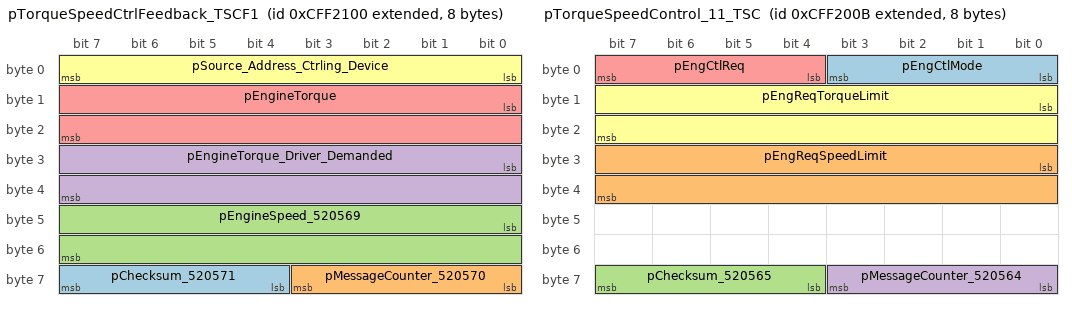
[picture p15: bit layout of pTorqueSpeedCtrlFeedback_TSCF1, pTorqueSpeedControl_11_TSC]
BO_ 2365530368 pTorqueSpeedCtrlFeedback_TSCF1: 8 ECM
 SG_ pChecksum_520571 : 60|4@1+ (1,0) [0|15] "" Vector__XXX
 SG_ pMessageCounter_520570 : 56|4@1+ (1,0) [0|15] "" Vector__XXX
 SG_ pEngineSpeed_520569 : 40|16@1+ (1,0) [0|64255] "rpm" Vector__XXX
 SG_ pEngineTorque_Driver_Demanded : 24|16@1- (0.03125,0) [-400|1607.96875] "Nm" Vector__XXX
 SG_ pEngineTorque : 8|16@1- (0.03125,0) [-400|1607.96875] "Nm" Vector__XXX
 SG_ pSource_Address_Ctrling_Device : 0|8@1+ (1,0) [0|255] "Source Address" Vector__XXX

BO_ 2365530123 pTorqueSpeedControl_11_TSC: 8 ABS
 SG_ pEngCtlMode : 0|4@1+ (1,0) [0|15] "" Vector__XXX
 SG_ pEngReqSpeedLimit : 24|16@1+ (1,0) [0|64255] "rpm" Vector__XXX
 SG_ pChecksum_520565 : 60|4@1+ (1,0) [0|15] "" Vector__XXX
 SG_ pMessageCounter_520564 : 56|4@1+ (1,0) [0|15] "" Vector__XXX
 SG_ pEngCtlReq : 4|4@1+ (1,0) [0|15] "" Vector__XXX
 SG_ pEngReqTorqueLimit : 8|16@1- (0.03125,0) [-400|1607.96875] "Nm" Vector__XXX

BO_ 2566834822 DM1: 22 Right_Hand_Control
 SG_ DTC5 : 144|32@1+ (1,0) [0|4294967295] "" Vector__XXX
 SG_ DTC4 : 112|32@1+ (1,0) [0|4294967295] "" Vector__XXX
 SG_ DTC3 : 80|32@1+ (1,0) [0|4294967295] "" Vector__XXX
 SG_ DTC2 : 48|32@1+ (1,0) [0|4294967295] "" Vector__XXX
 SG_ DTC1 : 16|32@1+ (1,0) [0|4294967295] "" Vector__XXX
 SG_ DM_FlashRedStopLamp : 12|2@1+ (1,0) [0|3] "" Vector__XXX
 SG_ DM_FlashProtectLamp : 8|2@1+ (1,0) [0|3] "" Vector__XXX
 SG_ DM_FlashMalfuncIndicatorLamp : 14|2@1+ (1,0) [0|3] "" Vector__XXX
 SG_ DM_FlashAmberWarningLamp : 10|2@1+ (1,0) [0|3] "" Vector__XXX
 SG_ DM_ProtectLampStatus : 0|2@1+ (1,0) [0|3] "" Vector__XXX
 SG_ DM_RedStopLampState : 4|2@1+ (1,0) [0|3] "" Vector__XXX
 SG_ DM_AmberWrningLmpStatus : 2|2@1+ (1,0) [0|3] "" Vector__XXX
 SG_ DM_MalfuncnIndicatorLampStatus : 6|2@1+ (1,0) [0|3] "" Vector__XXX

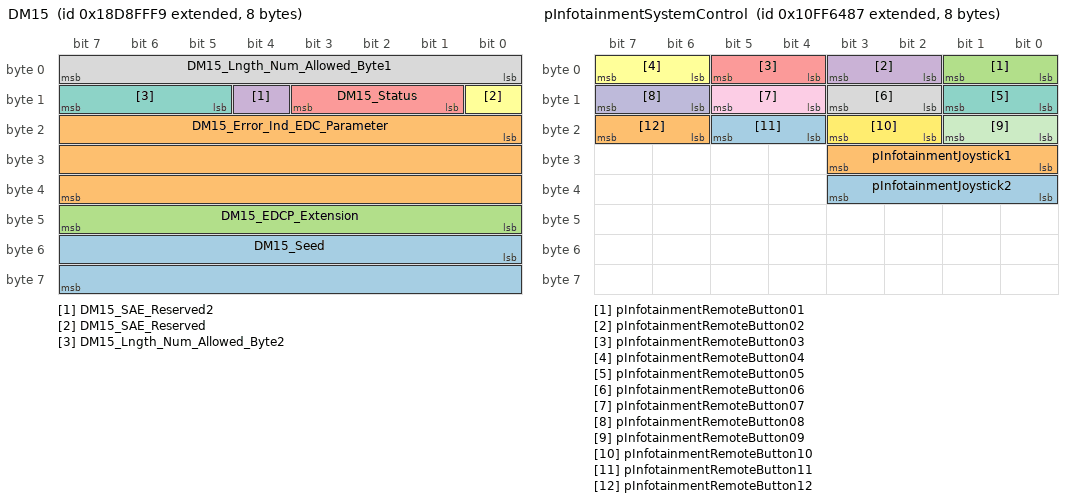
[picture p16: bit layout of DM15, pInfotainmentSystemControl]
BO_ 2564358137 DM15: 8 Diagnostic_Tool_Digital_Wrench
 SG_ DM15_Seed : 48|16@1+ (1,0) [0|65535] "" Vector__XXX
 SG_ DM15_Error_Ind_EDC_Parameter : 16|24@1+ (1,0) [0|16777215] "" Vector__XXX
 SG_ DM15_EDCP_Extension : 40|8@1+ (1,0) [0|255] "" Vector__XXX
 SG_ DM15_SAE_Reserved2 : 12|1@1+ (1,0) [1|1] "" Vector__XXX
 SG_ DM15_Status : 9|3@1+ (1,0) [0|7] "" Vector__XXX
 SG_ DM15_SAE_Reserved : 8|1@1+ (1,0) [1|1] "" Vector__XXX
 SG_ DM15_Lngth_Num_Allowed_Byte2 : 13|3@1+ (1,0) [0|7] "" Vector__XXX
 SG_ DM15_Lngth_Num_Allowed_Byte1 : 0|8@1+ (1,0) [0|255] "" Vector__XXX

BO_ 2432656519 pInfotainmentSystemControl: 8 Left_Hand_Control
 SG_ pInfotainmentJoystick2 : 32|4@1+ (1,0) [0|15] "" Vector__XXX
 SG_ pInfotainmentJoystick1 : 24|4@1+ (1,0) [0|15] "" Vector__XXX
 SG_ pInfotainmentRemoteButton01 : 0|2@1+ (1,0) [0|3] "" Vector__XXX
 SG_ pInfotainmentRemoteButton02 : 2|2@1+ (1,0) [0|3] "" Vector__XXX
 SG_ pInfotainmentRemoteButton03 : 4|2@1+ (1,0) [0|3] "" Vector__XXX
 SG_ pInfotainmentRemoteButton04 : 6|2@1+ (1,0) [0|3] "" Vector__XXX
 SG_ pInfotainmentRemoteButton05 : 8|2@1+ (1,0) [0|3] "" Vector__XXX
 SG_ pInfotainmentRemoteButton06 : 10|2@1+ (1,0) [0|3] "" Vector__XXX
 SG_ pInfotainmentRemoteButton07 : 12|2@1+ (1,0) [0|3] "" Vector__XXX
 SG_ pInfotainmentRemoteButton08 : 14|2@1+ (1,0) [0|3] "" Vector__XXX
 SG_ pInfotainmentRemoteButton09 : 16|2@1+ (1,0) [0|3] "" Vector__XXX
 SG_ pInfotainmentRemoteButton10 : 18|2@1+ (1,0) [0|3] "" Vector__XXX
 SG_ pInfotainmentRemoteButton11 : 20|2@1+ (1,0) [0|3] "" Vector__XXX
 SG_ pInfotainmentRemoteButton12 : 22|2@1+ (1,0) [0|3] "" Vector__XXX

BO_ 2432656775 pOperatorSwitchStatus_135: 8 Left_Hand_Control
 SG_ pOperatorButton29 : 58|2@1+ (1,0) [0|3] "" Vector__XXX
 SG_ pOperatorButton1 : 0|2@1+ (1,0) [0|3] "" Vector__XXX
 SG_ pOperatorButton2 : 2|2@1+ (1,0) [0|3] "" Vector__XXX
 SG_ pOperatorButton3 : 4|2@1+ (1,0) [0|3] "" Vector__XXX
 SG_ pOperatorButton4 : 6|2@1+ (1,0) [0|3] "" Vector__XXX
 SG_ pOperatorButton5 : 8|2@1+ (1,0) [0|3] "" Vector__XXX
 SG_ pOperatorButton6 : 10|2@1+ (1,0) [0|3] "" Vector__XXX
 SG_ pOperatorButton7 : 12|2@1+ (1,0) [0|3] "" Vector__XXX
 SG_ pOperatorButton8 : 14|2@1+ (1,0) [0|3] "" Vector__XXX
 SG_ pOperatorButton9 : 16|2@1+ (1,0) [0|3] "" Vector__XXX
 SG_ pOperatorButton10 : 18|2@1+ (1,0) [0|3] "" Vector__XXX
 SG_ pOperatorButton11 : 20|2@1+ (1,0) [0|3] "" Vector__XXX
 SG_ pOperatorButton12 : 22|2@1+ (1,0) [0|3] "" Vector__XXX
 SG_ pOperatorButton13 : 24|2@1+ (1,0) [0|3] "" Vector__XXX
 SG_ pOperatorButton14 : 26|2@1+ (1,0) [0|3] "" Vector__XXX
 SG_ pOperatorButton15 : 28|2@1+ (1,0) [0|3] "" Vector__XXX
 SG_ pOperatorButton16 : 30|2@1+ (1,0) [0|3] "" Vector__XXX
 SG_ pOperatorButton17 : 32|2@1+ (1,0) [0|3] "" Vector__XXX
 SG_ pOperatorButton18 : 34|2@1+ (1,0) [0|3] "" Vector__XXX
 SG_ pOperatorButton19 : 36|2@1+ (1,0) [0|3] "" Vector__XXX
 SG_ pOperatorButton20 : 38|2@1+ (1,0) [0|3] "" Vector__XXX
 SG_ pOperatorButton21 : 40|2@1+ (1,0) [0|3] "" Vector__XXX
 SG_ pOperatorButton22 : 42|2@1+ (1,0) [0|3] "" Vector__XXX
 SG_ pOperatorButton23 : 44|2@1+ (1,0) [0|3] "" Vector__XXX
 SG_ pOperatorButton24 : 46|2@1+ (1,0) [0|3] "" Vector__XXX
 SG_ pOperatorButton25 : 48|2@1+ (1,0) [0|3] "" Vector__XXX
 SG_ pOperatorButton26 : 50|2@1+ (1,0) [0|3] "" Vector__XXX
 SG_ pOperatorButton27 : 52|2@1+ (1,0) [0|3] "" Vector__XXX
 SG_ pOperatorButton28 : 54|2@1+ (1,0) [0|3] "" Vector__XXX
 SG_ pSideStandStatus : 56|2@1+ (1,0) [0|3] "" Vector__XXX

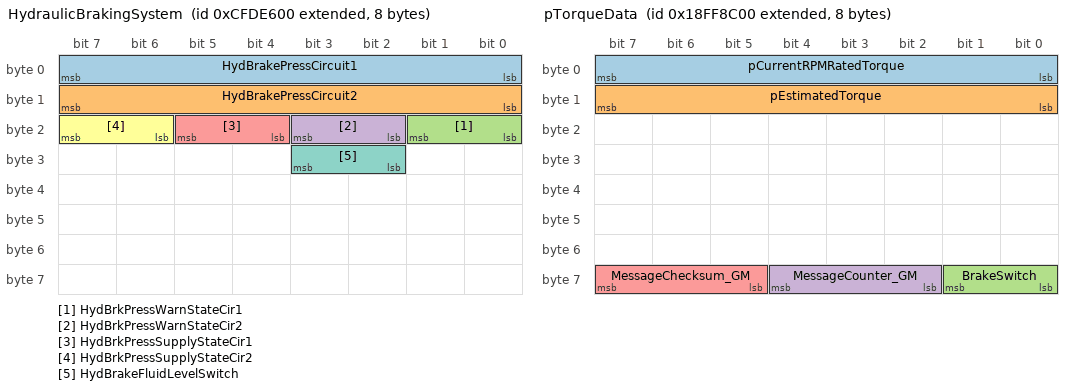
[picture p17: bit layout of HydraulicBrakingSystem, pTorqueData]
BO_ 2365449728 HydraulicBrakingSystem: 8 ECM
 SG_ HydBrakePressCircuit1 : 0|8@1+ (100,0) [0|25000] "kPa" Vector__XXX
 SG_ HydBrakePressCircuit2 : 8|8@1+ (100,0) [0|25000] "kPa" Vector__XXX
 SG_ HydBrkPressWarnStateCir1 : 16|2@1+ (1,0) [0|3] "" Vector__XXX
 SG_ HydBrkPressWarnStateCir2 : 18|2@1+ (1,0) [0|3] "" Vector__XXX
 SG_ HydBrkPressSupplyStateCir1 : 20|2@1+ (1,0) [0|3] "" Vector__XXX
 SG_ HydBrkPressSupplyStateCir2 : 22|2@1+ (1,0) [0|3] "" Vector__XXX
 SG_ HydBrakeFluidLevelSwitch : 26|2@1+ (1,0) [0|3] "" Vector__XXX

BO_ 2566884352 pTorqueData: 8 ECM
 SG_ pCurrentRPMRatedTorque : 0|8@1+ (0.03125,-1024) [-1024|1024] "Nm" Vector__XXX
 SG_ pEstimatedTorque : 8|8@1+ (0.03125,-1024) [-1024|1024] "Nm" Vector__XXX
 SG_ BrakeSwitch : 56|2@1+ (1,0) [0|3] "" Vector__XXX
 SG_ MessageCounter_GM : 58|3@1+ (1,0) [0|7] "" Vector__XXX
 SG_ MessageChecksum_GM : 61|3@1+ (1,0) [0|7] "" Vector__XXX

BO_ 2566842396 VehicleDirectionSpeed: 8 GPS
 SG_ CompassBearing : 0|16@1+ (0.0078125,0) [0|501.99] "Degree" Vector__XXX

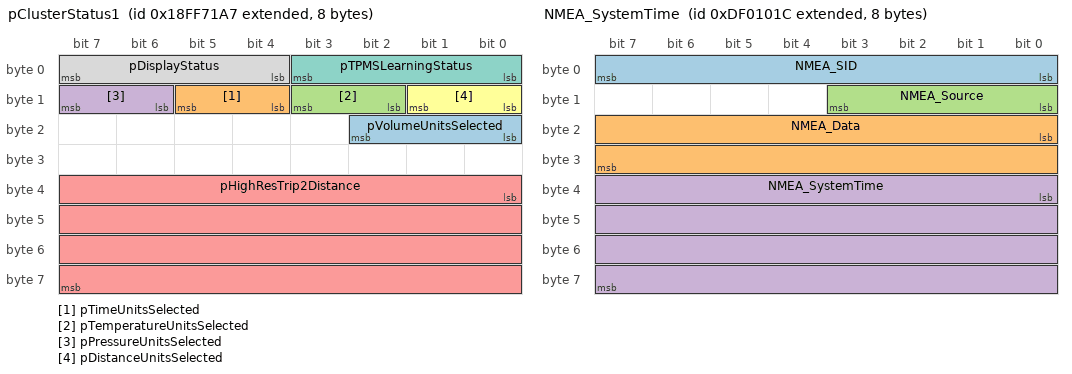
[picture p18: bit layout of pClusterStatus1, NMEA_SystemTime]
BO_ 2566877607 pClusterStatus1: 8 IC_2
 SG_ pVolumeUnitsSelected : 16|3@1+ (1,0) [0|7] "" Vector__XXX
 SG_ pTimeUnitsSelected : 12|2@1+ (1,0) [0|3] "" Vector__XXX
 SG_ pTemperatureUnitsSelected : 10|2@1+ (1,0) [0|3] "" Vector__XXX
 SG_ pPressureUnitsSelected : 14|2@1+ (1,0) [0|3] "" Vector__XXX
 SG_ pHighResTrip2Distance : 32|32@1+ (0.005,0) [0|21055406] "km" Vector__XXX
 SG_ pDistanceUnitsSelected : 8|2@1+ (1,0) [0|3] "" Vector__XXX
 SG_ pTPMSLearningStatus : 0|4@1+ (1,0) [0|15] "" Vector__XXX
 SG_ pDisplayStatus : 4|4@1+ (1,0) [0|15] "" Vector__XXX

BO_ 2381320220 NMEA_SystemTime: 8 GPS
 SG_ NMEA_SID : 0|8@1+ (1,0) [0|255] "Int" Vector__XXX
 SG_ NMEA_Data : 16|16@1+ (1,0) [0|65535] "Days" Vector__XXX
 SG_ NMEA_Source : 8|4@1+ (1,0) [0|15] "" Vector__XXX
 SG_ NMEA_SystemTime : 32|32@1+ (0.0001,0) [0|429496.7295] "Seconds" Vector__XXX

BO_ 2314731804 NMEA_PositionRapidUpdate: 8 GPS
 SG_ NMEA_Latitude : 0|32@1- (1E-007,0) [-214.7483648|214.7483647] "Deg" Vector__XXX
 SG_ NMEA_Longitude : 32|32@1- (1E-007,0) [-214.7483648|214.7483647] "Deg" Vector__XXX

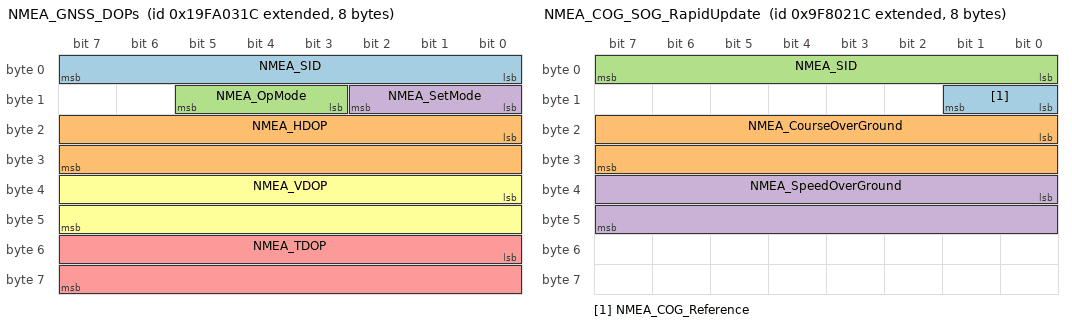
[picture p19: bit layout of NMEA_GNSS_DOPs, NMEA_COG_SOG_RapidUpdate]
BO_ 2583298844 NMEA_GNSS_DOPs: 8 GPS
 SG_ NMEA_SID : 0|8@1+ (1,0) [0|255] "Int" Vector__XXX
 SG_ NMEA_HDOP : 16|16@1+ (0.01,0) [0|655.35] "" Vector__XXX
 SG_ NMEA_OpMode : 11|3@1+ (1,0) [0|7] "" Vector__XXX
 SG_ NMEA_SetMode : 8|3@1+ (1,0) [0|7] "" Vector__XXX
 SG_ NMEA_TDOP : 48|16@1+ (0.01,0) [0|655.35] "" Vector__XXX
 SG_ NMEA_VDOP : 32|16@1+ (0.01,0) [0|655.35] "" Vector__XXX

BO_ 2314732060 NMEA_COG_SOG_RapidUpdate: 8 GPS
 SG_ NMEA_COG_Reference : 8|2@1+ (1,0) [0|3] "" Vector__XXX
 SG_ NMEA_CourseOverGround : 16|16@1+ (0.0001,0) [0|6.5535] "Rad" Vector__XXX
 SG_ NMEA_SID : 0|8@1+ (1,0) [0|255] "Int" Vector__XXX
 SG_ NMEA_SpeedOverGround : 32|16@1+ (0.01,0) [0|655.35] "m/s" Vector__XXX

CM_ SG_ 2566910976 FI2_ReverseMotorDriveInput "Status of the reverse motor switch input; input is high (open circuit) when the selector lever is in the reverse position and low (closed to ground) when the lever is in the forward position.";
CM_ BO_ 2566908160 "ECU Data List 18";
CM_ SG_ 2566908160 DL18_DesiredTorqueChg "The position of the valve used to regulatethe supply of a fluid, usually air or fuel/air mixture, to an engine.";
CM_ SG_ 2566908160 DL18_ThrottleAngleCorrFactor "The position of the valve used to regulatethe supply of a fluid, usually air or fuel/air mixture, to an engine.";
CM_ SG_ 2566908160 DL18_DragTorqueAdapt "The position of the valve used to regulatethe supply of a fluid, usually air or fuel/air mixture, to an engine.";
CM_ BO_ 2633984768 "Requested message which contains calibratible parameters specific to a vehicle.";
CM_ SG_ 2633984768 pADCModeAvailability "Used to let devices know if the vehicle is equipped with ADC";
CM_ SG_ 2633984768 pAWDModeAvailability "Used to let devices know if the vehicle is equipped with AWD";
CM_ SG_ 2633984768 pTurfModeAvailability "Used to let devices know if the vehicle is equipped with Turf Mode";
CM_ SG_ 2633984768 pDisplayedSpeedCorrectionFactor "Amount of adjustment to be applied by the speedometer to actual vehicle speed transmitted on the bus when displaying vehicle speed to the operator in order to correct for system variation.";
CM_ SG_ 2633984768 pInstrumentBacklightIntensity "Intensity (brightness) of instrumentation backlighting, 0% is no backlight and 100% is the maximum brightness the gauge is capable of.";
CM_ SG_ 2633984768 pWarningLampIntensity "Intensity (brightness) of warning lamp(s) which have the ability to be adjusted, 0% is warning lamp disabled and 100% is the maximum brightness the  warning lamp(s) are capable of.";
CM_ SG_ 2633984768 pFuelTankVolume "Total volume of fuel tank installed in vehicle";
CM_ SG_ 2633984768 pLowFuelLightONPercentage "Fuel percentage at which to turn the Low Fuel Light ON";
CM_ SG_ 2633984768 pFuelLevelDataSource "Fuel consumption data determination. Determines where the fuel sender resistive input is read";
CM_ SG_ 2633984768 pVehicleUnitsConfig "US12: MPH, Fahrenheit, US Gallon, 12-Hour Clock, PSI
INT12: km/h, Celsius, Liter, 12-hour Clock, kPa
UK12: MPH, Celsius, Imperial Gallon, 12-Hour Clock, PSI
*24-24-Hour Clock";
CM_ SG_ 2633984768 pFuelEconomyDataSource "Fuel Economy data determination. Determines where fuel economy (Range, Instantaneous and Average fuel economy) is calculated";
CM_ SG_ 2633984768 pSeatBeltInputSource "Determines what component reads the seat belt switch input.";
CM_ SG_ 2566847578 WasherFluidLevel "Not approved for use at Polaris at this time.";
CM_ SG_ 2566847578 FuelLevel "Ratio of volume of fuel to the total volume of fuel storage container.";
CM_ SG_ 2566847578 FuelFilterDiffPressure "Not approved for use at Polaris at this time.";
CM_ SG_ 2566847578 EngineOilFilterDiffPressure "Not approved for use at Polaris at this time.";
CM_ SG_ 2566847578 CargoAmbientTemperature "Not approved for use at Polaris at this time.";
CM_ SG_ 2566878604 pChecksum_524123 "Used to verify the signal path from the transmitting device to the receiving device. The message checksum is calculated using the first 7 data bytes, the message counter and the bytes of the message identifier.";
CM_ SG_ 2566878604 pMessageCounter_524122 "The message counter is used to detect situations where the transmitting ECU malfunction repeats the same frame all the time";
CM_ SG_ 2566878604 pOperationMode "Status of Manned or Remote Vehicle Operation Mode";
CM_ SG_ 2566878604 pStartStopCmd "Commanded Status of the Start Button";
CM_ SG_ 2566878604 pNorm_Acc_Pos_520354 "Indication of the current accelerator pedal position normalized to 0 to 100 %.  Commanded accelerator position as a percent of maximum accelerator position. ";
CM_ SG_ 2566878464 pStartStopCmd "Commanded Status of the Start Button";
CM_ SG_ 2566878464 pPedalPositionCommand "Pedal Position Requested in Percent of Pedal Travel Available";
CM_ SG_ 2566878464 pOperationMode "Status of Manned or Remote Vehicle Operation Mode";
CM_ BO_ 2566876928 "Information Requested from Engine";
CM_ SG_ 2566876928 pSecondaryAirValveControl "Secondary Air Valve Control Request Status";
CM_ BO_ 2566853886 "Contains information used on the Watt platform for electrical characteristics of the vehicle.";
CM_ SG_ 2566853886 pRangeToEmptyEV "Calculated range on remaining electrical power";
CM_ SG_ 2566853886 pEfficiencyEV "Calculated efficiency of an electric powertrain vehicle.";
CM_ BO_ 2566876416 "Drive Mode Information";
CM_ SG_ 2566876416 pDriveModeCommanded "ASCII Representation of Drive Mode Commanded.";
CM_ SG_ 2566876416 pFootOnCruiseControlEnabled "Indicates whether or not the Foot on Cruise has been enabled.";
CM_ SG_ 2566876416 pDriveModeRequested "ASCII Representation of Drive Mode Requested.";
CM_ BO_ 2566825472 "Intake Manifold Information";
CM_ SG_ 2566825472 EngineTurbo1BoostPressure "Gage pressure of air measured downstream of the compressor discharge side of the turbocharger.";
CM_ BO_ 2566804212 "This contains high resolution/range parameters reported from the alternator or power generation components.";
CM_ SG_ 2566804212 NetBattCurrentHiRange "Net flow of electrical current into/out-of the battery or batteries.";
CM_ BO_ 2566804211 "This contains high resolution/range parameters reported from the alternator or power generation components.";
CM_ SG_ 2566804211 NetBattCurrentHiRange "Net flow of electrical current into/out-of the battery or batteries.";
CM_ BO_ 2297441780 "The acceleration sensor message shall provide a measurement of the vehicle’s acceleration in the lateral, longitudinal, and vertical axes.";
CM_ BO_ 2566846452 "Vehicle Electrical Power Information";
CM_ SG_ 2566846452 Net_Battery_Current "Net flow of electrical current into/out of the battery or batteries";
CM_ SG_ 2566846452 BatteryPotential "This parameter measures the first souce of battery potential as measured at the input of the ECM/actuator etc. coming from one or more batteries, irrespective of the distance between the component
and the battery.";
CM_ BO_ 2297441779 "The acceleration sensor message shall provide a measurement of the vehicle’s acceleration in the lateral, longitudinal, and vertical axes.";
CM_ BO_ 2566846451 "Vehicle Electrical Power Information";
CM_ SG_ 2566846451 Net_Battery_Current "Net flow of electrical current into/out of the battery or batteries";
CM_ SG_ 2566846451 BatteryPotential "This parameter measures the first souce of battery potential as measured at the input of the ECM/actuator etc. coming from one or more batteries, irrespective of the distance between the component
and the battery.";
CM_ BO_ 2365525748 "BMC Power Information";
CM_ SG_ 2365525748 WATT_pPack_Voltage "The voltage of the battery pack monitored by the Battery Management Controller (BMC).";
CM_ SG_ 2365525748 WATT_pPack_Current "The current of the battery pack monitored by the Battery Management Controller (BMC).";
CM_ SG_ 2365525748 WATT_pDischarge_Limit "The discharge limit of the battery pack monitored by the Battery Management Controller (BMC).";
CM_ SG_ 2365525748 WATT_pCharge_Limit "The Charge limit of the battery pack monitored by the Battery Management Controller (BMC).";
CM_ SG_ 2365525748 WATT_pBMC_Pwr_Msg_Check_Seq "Checksum ensures data is valid before use.";
CM_ BO_ 2365525747 "BMC Power Information";
CM_ SG_ 2365525747 WATT_pPack_Voltage "The voltage of the battery pack monitored by the Battery Management Controller (BMC).";
CM_ SG_ 2365525747 WATT_pPack_Current "The current of the battery pack monitored by the Battery Management Controller (BMC).";
CM_ SG_ 2365525747 WATT_pDischarge_Limit "The discharge limit of the battery pack monitored by the Battery Management Controller (BMC).";
CM_ SG_ 2365525747 WATT_pCharge_Limit "The Charge limit of the battery pack monitored by the Battery Management Controller (BMC).";
CM_ SG_ 2365525747 WATT_pBMC_Pwr_Msg_Check_Seq "Checksum ensures data is valid before use.";
CM_ BO_ 2298415350 "Power Information for the Vehicle Motor";
CM_ SG_ 2298415350 WATT_pSpeed_Lim_Cutback_Status "Status bit indicating the ramp down of motor control output and subsequent vehicle performance due to the motor speed exceeding the limits set for the motor.";
CM_ SG_ 2298415350 WATT_pMotor_Therm_Cutback "Status bit indicating the ramp down of motor control output and subsequent vehicle performance due to the temperature of the motor exceeding a predefined value.";
CM_ SG_ 2298415350 WATT_pMotor_Power_Cutback_Status "Status bit indicating the ramp down of motor control output and subsequent vehicle performance due to low power availability.";
CM_ SG_ 2298415350 WATT_pI_DC_Cutback_Status "Status bit indicating the ramp down of motor control output and subsequent vehicle performance due to low Input Current.";
CM_ SG_ 2298415350 WATT_pController_Therm_Cutback "Status bit indicating the ramp down of motor control output and subsequent vehicle performance due to the temperature of the motor controller exceeding a predefined value.";
CM_ SG_ 2298415350 WATT_pPower_Msg_Check_Seq "Checksum ensures data is valid before use.";
CM_ SG_ 2298415350 WATT_pInput_Current "Input DC Current of the Electric Propulsion Control Unit or Auxiliary Power Control Unit from which the message is sent.";
CM_ SG_ 2298415350 WATT_pCapacitor_Voltage "Capacitor Voltage of the Electric Propulsion Control Unit or Auxiliary Power Control Unit from which the message is sent.";
CM_ BO_ 2298415606 "Temperature Information of Electrical System Components";
CM_ SG_ 2298415606 WATT_pTemperature_Msg_Check_Seq "Checksum ensures data is valid before use.";
CM_ SG_ 2298415606 WATT_pMotor_Temp_Margin "The smallest difference between an internal motor component and its thermal limit for the Electric Propulsion Control Unit or Auxiliary Power Control Unit from which the message is sent";
CM_ SG_ 2298415606 WATT_pMotor_Temp "Actual motor temperature of the Electric Propulsion Unit or Auxiliary Power Unit from which the message is sent";
CM_ SG_ 2298415606 WATT_pJunction_Temp "Actual junction temperature of the Electric Propulsion Control Unit or Auxiliary Power Unit from which the message is sent";
CM_ SG_ 2298415606 WATT_pController_Temp_Margin "The smallest difference between an internal component and its thermal limit for the Electric Propulsion Control Unit or Auxiliary Power Control Unit from which the message is sent";
CM_ SG_ 2298415606 WATT_pCapacitor_Temp "Actual capacitor temperature of the Electric Propulsion Control Unit or Auxiliary Power Unit from which the message is sent";
CM_ SG_ 2298415606 WATT_pBoard_Temp "Board temperature of the Electric Propulsion Control Unit or Auxiliary Power Unit from which the message is sent";
CM_ SG_ 2298415606 WATT_pBaseplate_Temp "Actual baseplate temperature of the Electric Propulsion Control Unit or Auxiliary Power Unit from which the message is sent";
CM_ BO_ 2298415351 "Power Information for the Vehicle Motor";
CM_ SG_ 2298415351 WATT_pSpeed_Lim_Cutback_Status "Status bit indicating the ramp down of motor control output and subsequent vehicle performance due to the motor speed exceeding the limits set for the motor.";
CM_ SG_ 2298415351 WATT_pMotor_Therm_Cutback "Status bit indicating the ramp down of motor control output and subsequent vehicle performance due to the temperature of the motor exceeding a predefined value.";
CM_ SG_ 2298415351 WATT_pMotor_Power_Cutback_Status "Status bit indicating the ramp down of motor control output and subsequent vehicle performance due to low power availability.";
CM_ SG_ 2298415351 WATT_pI_DC_Cutback_Status "Status bit indicating the ramp down of motor control output and subsequent vehicle performance due to low Input Current.";
CM_ SG_ 2298415351 WATT_pController_Therm_Cutback "Status bit indicating the ramp down of motor control output and subsequent vehicle performance due to the temperature of the motor controller exceeding a predefined value.";
CM_ SG_ 2298415351 WATT_pPower_Msg_Check_Seq "Checksum ensures data is valid before use.";
CM_ SG_ 2298415351 WATT_pInput_Current "Input DC Current of the Electric Propulsion Control Unit or Auxiliary Power Control Unit from which the message is sent.";
CM_ SG_ 2298415351 WATT_pCapacitor_Voltage "Capacitor Voltage of the Electric Propulsion Control Unit or Auxiliary Power Control Unit from which the message is sent.";
CM_ BO_ 2298415607 "Temperature Information of Electrical System Components";
CM_ SG_ 2298415607 WATT_pTemperature_Msg_Check_Seq "Checksum ensures data is valid before use.";
CM_ SG_ 2298415607 WATT_pMotor_Temp_Margin "The smallest difference between an internal motor component and its thermal limit for the Electric Propulsion Control Unit or Auxiliary Power Control Unit from which the message is sent";
CM_ SG_ 2298415607 WATT_pMotor_Temp "Actual motor temperature of the Electric Propulsion Unit or Auxiliary Power Unit from which the message is sent";
CM_ SG_ 2298415607 WATT_pJunction_Temp "Actual junction temperature of the Electric Propulsion Control Unit or Auxiliary Power Unit from which the message is sent";
CM_ SG_ 2298415607 WATT_pController_Temp_Margin "The smallest difference between an internal component and its thermal limit for the Electric Propulsion Control Unit or Auxiliary Power Control Unit from which the message is sent";
CM_ SG_ 2298415607 WATT_pCapacitor_Temp "Actual capacitor temperature of the Electric Propulsion Control Unit or Auxiliary Power Unit from which the message is sent";
CM_ SG_ 2298415607 WATT_pBoard_Temp "Board temperature of the Electric Propulsion Control Unit or Auxiliary Power Unit from which the message is sent";
CM_ SG_ 2298415607 WATT_pBaseplate_Temp "Actual baseplate temperature of the Electric Propulsion Control Unit or Auxiliary Power Unit from which the message is sent";
CM_ SG_ 2365523456 pModCtlCmdState "The commanded control mode that the EPS unit will operate in";
CM_ BO_ 2298415346 "Power Information for the Vehicle Motor";
CM_ SG_ 2298415346 WATT_pSpeed_Lim_Cutback_Status "Status bit indicating the ramp down of motor control output and subsequent vehicle performance due to the motor speed exceeding the limits set for the motor.";
CM_ SG_ 2298415346 WATT_pMotor_Therm_Cutback "Status bit indicating the ramp down of motor control output and subsequent vehicle performance due to the temperature of the motor exceeding a predefined value.";
CM_ SG_ 2298415346 WATT_pMotor_Power_Cutback_Status "Status bit indicating the ramp down of motor control output and subsequent vehicle performance due to low power availability.";
CM_ SG_ 2298415346 WATT_pI_DC_Cutback_Status "Status bit indicating the ramp down of motor control output and subsequent vehicle performance due to low Input Current.";
CM_ SG_ 2298415346 WATT_pController_Therm_Cutback "Status bit indicating the ramp down of motor control output and subsequent vehicle performance due to the temperature of the motor controller exceeding a predefined value.";
CM_ SG_ 2298415346 WATT_pPower_Msg_Check_Seq "Checksum ensures data is valid before use.";
CM_ SG_ 2298415346 WATT_pInput_Current "Input DC Current of the Electric Propulsion Control Unit or Auxiliary Power Control Unit from which the message is sent.";
CM_ SG_ 2298415346 WATT_pCapacitor_Voltage "Capacitor Voltage of the Electric Propulsion Control Unit or Auxiliary Power Control Unit from which the message is sent.";
CM_ BO_ 2298415602 "Temperature Information of Electrical System Components";
CM_ SG_ 2298415602 WATT_pTemperature_Msg_Check_Seq "Checksum ensures data is valid before use.";
CM_ SG_ 2298415602 WATT_pMotor_Temp_Margin "The smallest difference between an internal motor component and its thermal limit for the Electric Propulsion Control Unit or Auxiliary Power Control Unit from which the message is sent";
CM_ SG_ 2298415602 WATT_pMotor_Temp "Actual motor temperature of the Electric Propulsion Unit or Auxiliary Power Unit from which the message is sent";
CM_ SG_ 2298415602 WATT_pJunction_Temp "Actual junction temperature of the Electric Propulsion Control Unit or Auxiliary Power Unit from which the message is sent";
CM_ SG_ 2298415602 WATT_pController_Temp_Margin "The smallest difference between an internal component and its thermal limit for the Electric Propulsion Control Unit or Auxiliary Power Control Unit from which the message is sent";
CM_ SG_ 2298415602 WATT_pCapacitor_Temp "Actual capacitor temperature of the Electric Propulsion Control Unit or Auxiliary Power Unit from which the message is sent";
CM_ SG_ 2298415602 WATT_pBoard_Temp "Board temperature of the Electric Propulsion Control Unit or Auxiliary Power Unit from which the message is sent";
CM_ SG_ 2298415602 WATT_pBaseplate_Temp "Actual baseplate temperature of the Electric Propulsion Control Unit or Auxiliary Power Unit from which the message is sent";
CM_ BO_ 2298415345 "Power Information for the Vehicle Motor";
CM_ SG_ 2298415345 WATT_pSpeed_Lim_Cutback_Status "Status bit indicating the ramp down of motor control output and subsequent vehicle performance due to the motor speed exceeding the limits set for the motor.";
CM_ SG_ 2298415345 WATT_pMotor_Therm_Cutback "Status bit indicating the ramp down of motor control output and subsequent vehicle performance due to the temperature of the motor exceeding a predefined value.";
CM_ SG_ 2298415345 WATT_pMotor_Power_Cutback_Status "Status bit indicating the ramp down of motor control output and subsequent vehicle performance due to low power availability.";
CM_ SG_ 2298415345 WATT_pI_DC_Cutback_Status "Status bit indicating the ramp down of motor control output and subsequent vehicle performance due to low Input Current.";
CM_ SG_ 2298415345 WATT_pController_Therm_Cutback "Status bit indicating the ramp down of motor control output and subsequent vehicle performance due to the temperature of the motor controller exceeding a predefined value.";
CM_ SG_ 2298415345 WATT_pPower_Msg_Check_Seq "Checksum ensures data is valid before use.";
CM_ SG_ 2298415345 WATT_pInput_Current "Input DC Current of the Electric Propulsion Control Unit or Auxiliary Power Control Unit from which the message is sent.";
CM_ SG_ 2298415345 WATT_pCapacitor_Voltage "Capacitor Voltage of the Electric Propulsion Control Unit or Auxiliary Power Control Unit from which the message is sent.";
CM_ BO_ 2298415601 "Temperature Information of Electrical System Components";
CM_ SG_ 2298415601 WATT_pTemperature_Msg_Check_Seq "Checksum ensures data is valid before use.";
CM_ SG_ 2298415601 WATT_pMotor_Temp_Margin "The smallest difference between an internal motor component and its thermal limit for the Electric Propulsion Control Unit or Auxiliary Power Control Unit from which the message is sent";
CM_ SG_ 2298415601 WATT_pMotor_Temp "Actual motor temperature of the Electric Propulsion Unit or Auxiliary Power Unit from which the message is sent";
CM_ SG_ 2298415601 WATT_pJunction_Temp "Actual junction temperature of the Electric Propulsion Control Unit or Auxiliary Power Unit from which the message is sent";
CM_ SG_ 2298415601 WATT_pController_Temp_Margin "The smallest difference between an internal component and its thermal limit for the Electric Propulsion Control Unit or Auxiliary Power Control Unit from which the message is sent";
CM_ SG_ 2298415601 WATT_pCapacitor_Temp "Actual capacitor temperature of the Electric Propulsion Control Unit or Auxiliary Power Unit from which the message is sent";
CM_ SG_ 2298415601 WATT_pBoard_Temp "Board temperature of the Electric Propulsion Control Unit or Auxiliary Power Unit from which the message is sent";
CM_ SG_ 2298415601 WATT_pBaseplate_Temp "Actual baseplate temperature of the Electric Propulsion Control Unit or Auxiliary Power Unit from which the message is sent";
CM_ BO_ 2298415344 "Power Information for the Vehicle Motor";
CM_ SG_ 2298415344 WATT_pSpeed_Lim_Cutback_Status "Status bit indicating the ramp down of motor control output and subsequent vehicle performance due to the motor speed exceeding the limits set for the motor.";
CM_ SG_ 2298415344 WATT_pMotor_Therm_Cutback "Status bit indicating the ramp down of motor control output and subsequent vehicle performance due to the temperature of the motor exceeding a predefined value.";
CM_ SG_ 2298415344 WATT_pMotor_Power_Cutback_Status "Status bit indicating the ramp down of motor control output and subsequent vehicle performance due to low power availability.";
CM_ SG_ 2298415344 WATT_pI_DC_Cutback_Status "Status bit indicating the ramp down of motor control output and subsequent vehicle performance due to low Input Current.";
CM_ SG_ 2298415344 WATT_pController_Therm_Cutback "Status bit indicating the ramp down of motor control output and subsequent vehicle performance due to the temperature of the motor controller exceeding a predefined value.";
CM_ SG_ 2298415344 WATT_pPower_Msg_Check_Seq "Checksum ensures data is valid before use.";
CM_ SG_ 2298415344 WATT_pInput_Current "Input DC Current of the Electric Propulsion Control Unit or Auxiliary Power Control Unit from which the message is sent.";
CM_ SG_ 2298415344 WATT_pCapacitor_Voltage "Capacitor Voltage of the Electric Propulsion Control Unit or Auxiliary Power Control Unit from which the message is sent.";
CM_ BO_ 2298415600 "Temperature Information of Electrical System Components";
CM_ SG_ 2298415600 WATT_pTemperature_Msg_Check_Seq "Checksum ensures data is valid before use.";
CM_ SG_ 2298415600 WATT_pMotor_Temp_Margin "The smallest difference between an internal motor component and its thermal limit for the Electric Propulsion Control Unit or Auxiliary Power Control Unit from which the message is sent";
CM_ SG_ 2298415600 WATT_pMotor_Temp "Actual motor temperature of the Electric Propulsion Unit or Auxiliary Power Unit from which the message is sent";
CM_ SG_ 2298415600 WATT_pJunction_Temp "Actual junction temperature of the Electric Propulsion Control Unit or Auxiliary Power Unit from which the message is sent";
CM_ SG_ 2298415600 WATT_pController_Temp_Margin "The smallest difference between an internal component and its thermal limit for the Electric Propulsion Control Unit or Auxiliary Power Control Unit from which the message is sent";
CM_ SG_ 2298415600 WATT_pCapacitor_Temp "Actual capacitor temperature of the Electric Propulsion Control Unit or Auxiliary Power Unit from which the message is sent";
CM_ SG_ 2298415600 WATT_pBoard_Temp "Board temperature of the Electric Propulsion Control Unit or Auxiliary Power Unit from which the message is sent";
CM_ SG_ 2298415600 WATT_pBaseplate_Temp "Actual baseplate temperature of the Electric Propulsion Control Unit or Auxiliary Power Unit from which the message is sent";
CM_ BO_ 2298415343 "Power Information for the Vehicle Motor";
CM_ SG_ 2298415343 WATT_pController_Therm_Cutback "Status bit indicating the ramp down of motor control output and subsequent vehicle performance due to the temperature of the motor controller exceeding a predefined value.";
CM_ SG_ 2298415343 WATT_pSpeed_Lim_Cutback_Status "Status bit indicating the ramp down of motor control output and subsequent vehicle performance due to the motor speed exceeding the limits set for the motor.";
CM_ SG_ 2298415343 WATT_pMotor_Therm_Cutback "Status bit indicating the ramp down of motor control output and subsequent vehicle performance due to the temperature of the motor exceeding a predefined value.";
CM_ SG_ 2298415343 WATT_pMotor_Power_Cutback_Status "Status bit indicating the ramp down of motor control output and subsequent vehicle performance due to low power availability.";
CM_ SG_ 2298415343 WATT_pI_DC_Cutback_Status "Status bit indicating the ramp down of motor control output and subsequent vehicle performance due to low Input Current.";
CM_ SG_ 2298415343 WATT_pPower_Msg_Check_Seq "Checksum ensures data is valid before use.";
CM_ SG_ 2298415343 WATT_pInput_Current "Input DC Current of the Electric Propulsion Control Unit or Auxiliary Power Control Unit from which the message is sent.";
CM_ SG_ 2298415343 WATT_pCapacitor_Voltage "Capacitor Voltage of the Electric Propulsion Control Unit or Auxiliary Power Control Unit from which the message is sent.";
CM_ BO_ 2298415599 "Temperature Information of Electrical System Components";
CM_ SG_ 2298415599 WATT_pTemperature_Msg_Check_Seq "Checksum ensures data is valid before use.";
CM_ SG_ 2298415599 WATT_pMotor_Temp_Margin "The smallest difference between an internal motor component and its thermal limit for the Electric Propulsion Control Unit or Auxiliary Power Control Unit from which the message is sent";
CM_ SG_ 2298415599 WATT_pMotor_Temp "Actual motor temperature of the Electric Propulsion Unit or Auxiliary Power Unit from which the message is sent";
CM_ SG_ 2298415599 WATT_pJunction_Temp "Actual junction temperature of the Electric Propulsion Control Unit or Auxiliary Power Unit from which the message is sent";
CM_ SG_ 2298415599 WATT_pController_Temp_Margin "The smallest difference between an internal component and its thermal limit for the Electric Propulsion Control Unit or Auxiliary Power Control Unit from which the message is sent";
CM_ SG_ 2298415599 WATT_pCapacitor_Temp "Actual capacitor temperature of the Electric Propulsion Control Unit or Auxiliary Power Unit from which the message is sent";
CM_ SG_ 2298415599 WATT_pBoard_Temp "Board temperature of the Electric Propulsion Control Unit or Auxiliary Power Unit from which the message is sent";
CM_ SG_ 2298415599 WATT_pBaseplate_Temp "Actual baseplate temperature of the Electric Propulsion Control Unit or Auxiliary Power Unit from which the message is sent";
CM_ BO_ 2566845696 "Ambient Conditions Outside the vehicle";
CM_ SG_ 2566845696 CabInteriorTemperature "Not approved for use at Polaris at this time.";
CM_ SG_ 2566845696 AmbientAirTemperature "Temperature of air surrounding vehicle.";
CM_ SG_ 2566845696 EngineAirInletTemperature "Temperature of air entering vehicle air induction system.";
CM_ SG_ 2566845696 RoadSurfaceTemperature "Indicated temperature of road surface over which the vehicle is operating.";
CM_ BO_ 2566844672 "Cruise Control Status and Vehicle Speed Information";
CM_ SG_ 2566844672 TwoSpeedAxleSwitch "Switch signal which indicates the current axle range.";
CM_ SG_ 2566844672 ParkingBrakeSwitch "Switch signal which indicates when the parking brake is set. In general the switch actuated by the operator's park brake control,
whether a pedal, lever, or other control mechanism.";
CM_ SG_ 2566844672 Wheel_BasedVehicleSpeed "Speed of the vehicle as calculated from wheel or tailshaft speed.";
CM_ SG_ 2566844672 CruiseCtrlActive "Cruise control is switched on.  It is not ensured that the engine is controlled by cruise control, as in the case of a large driver's demand the engine is controlled by the driver while
cruise control is active.";
CM_ SG_ 2566844672 CruiseCtrlEnableSwitch "Switch signal which indicates that it is possible to manage the cruise control function";
CM_ SG_ 2566844672 BrakeSwitch "Switch signal which indicates that the driver operated brake foot pedal is being pressed";
CM_ SG_ 2566844672 ClutchSwitch "Switch signal which indicates that the clutch pedal is being pressed.  It is necessary for a safe drivetrain behavior that the clutch switch is set before the clutch is opened (cruise control function).";
CM_ SG_ 2566844672 CruiseCtrlSetSwitch "Switch signal of the cruise control activator which indicates that the activator is in the position 'set'.";
CM_ SG_ 2566844672 CruiseCtrlCoastSwitch "Switch signal of the cruise control activator which indicates that the activator is in the position 'coast'";
CM_ SG_ 2566844672 CruiseCtrlResumeSwitch "Switch signal of the cruise control activator which indicates that the activator is in the position 'resume'";
CM_ SG_ 2566844672 CruiseCtrlAccelerateSwitch "Switch signal of the cruise control activator which indicates that the activator is in the position 'accelerate'";
CM_ SG_ 2566844672 CruiseCtrlSetSpeed "Value of set (chosen) velocity of velocity control system.";
CM_ SG_ 2566844672 pOdometerDriveBit "Alternate state (A->B, B->A) each time the vehicle has moved a defined distance (currently 40m).";
CM_ SG_ 2566844672 CruiseCtrlPauseSw "Switch signal which indicates the positon of the Cruise Control Pause Switch used on Remote Cruise Control applications. The Cruise Control Pause Switch signal temporarily
disables the Cruise Control function.";
CM_ SG_ 2566844672 pCCMessageCounter "Rolling Counter (ensures updated message is used)";
CM_ SG_ 2566844672 pCCChecksum "XOR of bytes 0-6 (ensures data is valid before use)";
CM_ SG_ 2566844672 pCruiseEnableStatus "The Cruise Control System has been enabled by the operator.  (Amber Light)";
CM_ BO_ 2364539904 "Electronic engine controller #1";
CM_ SG_ 2364539904 EngineTorqueMode "Signal which indicates which engine torque mode is currently generating, limiting or controlling the torque.";
CM_ SG_ 2364539904 DriversDemandEngine_PercTorque "The requested torque output of the engine by the driver.";
CM_ SG_ 2364539904 ActualEngine_PercTorque "The calculated output torque of the engine";
CM_ SG_ 2364539904 EngineSpeed "Actual engine speed.";
CM_ SG_ 2364539904 SourceAddress "Source address of controlling device for brake control.";
CM_ SG_ 2364539904 EngineStarterMode "There are several phases in a starting action and different reasons why a start cannot take place.";
CM_ SG_ 2364539904 EngineDemand_PercentTorque "The requested torque output of the engine by all dynamic internal inputs, including smoke control, noise control and low and high speed governing.";
CM_ BO_ 2565866752 "Electronic Transmission Controller 2";
CM_ SG_ 2565866752 TransmissionSelectedGear "The gear that the transmission will attempt to achieve during the current shift if a shift is in progress,
or the next shift if one is pending";
CM_ SG_ 2565866752 TransmissionActualGearRatio "Actual ratio of input shaft speed to output shaft speed";
CM_ SG_ 2565866752 TransmissionCurrentGear "The gear currently engaged in the transmission or the last gear engaged while the transmission is in
the process of shifting to the new or selected gear";
CM_ SG_ 2565866752 TransmissionRqstedRange "Range selected by the operator.";
CM_ SG_ 2565866752 TransmissionCurrentRange "Range currently being commanded by the transmission control system.";
CM_ BO_ 2566843904 "Engine Temperature 1";
CM_ SG_ 2566843904 EngineCoolantTemperature "Temperature of the liquid in the engine cooling system.";
CM_ SG_ 2566843904 EngFuelTemperature1 "Temperature of fuel (or gass) passing through the first fuel control system. Se SPN 3468 for the second control system.";
CM_ SG_ 2566843904 EngineOilTemperature1 "Temperature of the engine lubricant.";
CM_ SG_ 2566843904 EngTurboOilTemperature "Temperature of the turbocharger lubricant.";
CM_ SG_ 2566843904 EngineIntercoolerTemperature "Not approved for use at Polaris at this time.";
CM_ SG_ 2566843904 EngineIntercoolerThermosatOpen "Not approved for use at Polaris at this time.

(The current position of the thermostat used to regulate the temperature of the engine intercooler.)";
CM_ BO_ 2566844928 "Engine Fuel Economy Data";
CM_ SG_ 2566844928 EngineFuelRate "Amount of fuel consumed by engine per unit of time";
CM_ SG_ 2566844928 InstantaneousFuelEconomy "Current fuel economy at current vehicle velocity.";
CM_ SG_ 2566844928 AverageFuelEconomy "Average of instantaneous fuel economy for that segment of vehicle operation of interest.";
CM_ SG_ 2566844928 EngineThrottlePosition "The position of the valve used to regulatethe supply of a fluid, usually air or fuel/air mixture, to an engine.";
CM_ BO_ 2566845952 "Engine Intake and Exhaust Pressure and Temperature Information";
CM_ SG_ 2566845952 ParticulateTrapInletPressure "Not approved for use at Polaris at this time.";
CM_ SG_ 2566845952 EngTurboBoostPressure "The gauge pressure measurement of the air intake manifold.  If there are multiple air pressure sensors in the intake stream, this is the last one in flow direction before entering the combustion chamber.";
CM_ SG_ 2566845952 EngIntakeManifoldTemperature "Temperature of pre-combustion air found in intake manifold of engine air supply system.";
CM_ SG_ 2566845952 EngAirInletPressure "Absolue air pressure at inlet to intake manifold or air box.";
CM_ SG_ 2566845952 AirFilterDifferentialPressure "Not approved for use at Polaris at this time.";
CM_ SG_ 2566845952 EngExhaustGasTemperature "Temperature of combustion byproducts leaving the engine. See SPNs 2433 and 2434 for engines with more than one exhaust gas temperature measurement.";
CM_ SG_ 2566845952 CoolantFilterDiffPressure "Not approved for use at Polaris at this time.";
CM_ BO_ 2566846208 "Vehicle Electrical Power Information";
CM_ SG_ 2566846208 NetBatteryCurrent "Net flow of electrical current into/out of the battery or batteries.";
CM_ SG_ 2566846208 AlternatorCurrent "Measure of electrical current flow from the alternator. Alternator Current (High Range/Resolution) parameter SPN 1795 has a higher range and resolution of the same parameter.";
CM_ SG_ 2566846208 ChargingSystemPotential "Electrical potential measured at the charging system output. The charging system may be any device charging the batteries. This includes alternators, generators, solid state charger,
and other charging devices.";
CM_ SG_ 2566846208 BatteryPotential "This parameter measures the first souce of battery potential as measured at the input of the ECM/actuator etc. coming from one or more batteries, irrespective of the distance between the component
and the battery.";
CM_ SG_ 2566846208 KeyswitchBatteryPotential "Battery potential measured at the input of the electronic control unit supplied through a keyswitch or similar switching device.";
CM_ BO_ 2566844806 "Cruise Control Status and Vehicle Speed Information";
CM_ SG_ 2566844806 pCruiseCntrlCounter "Rolling Counter (ensures updated message is used).";
CM_ SG_ 2566844806 TwoSpeedAxleSwitch "Switch signal which indicates the current axle range.";
CM_ SG_ 2566844806 ParkingBrakeSwitch "Switch signal which indicates when the parking brake is set. In general the switch actuated by the operator's park brake control,
whether a pedal, lever, or other control mechanism.";
CM_ SG_ 2566844806 Wheel_BasedVehicleSpeed "Speed of the vehicle as calculated from wheel or tailshaft speed.";
CM_ SG_ 2566844806 CruiseCtrlActive "Cruise control is switched on.  It is not ensured that the engine is controlled by cruise control, as in the case of a large driver's demand the engine is controlled by the driver while
cruise control is active.";
CM_ SG_ 2566844806 CruiseCtrlEnableSwitch "Switch signal which indicates that it is possible to manage the cruise control function";
CM_ SG_ 2566844806 BrakeSwitch "Switch signal which indicates that the driver operated brake foot pedal is being pressed";
CM_ SG_ 2566844806 ClutchSwitch "Switch signal which indicates that the clutch pedal is being pressed.  It is necessary for a safe drivetrain behavior that the clutch switch is set before the clutch is opened (cruise control function).";
CM_ SG_ 2566844806 CruiseCtrlSetSwitch "Switch signal of the cruise control activator which indicates that the activator is in the position 'set'.";
CM_ SG_ 2566844806 CruiseCtrlCoastSwitch "Switch signal of the cruise control activator which indicates that the activator is in the position 'coast'";
CM_ SG_ 2566844806 CruiseCtrlResumeSwitch "Switch signal of the cruise control activator which indicates that the activator is in the position 'resume'";
CM_ SG_ 2566844806 CruiseCtrlAccelerateSwitch "Switch signal of the cruise control activator which indicates that the activator is in the position 'accelerate'";
CM_ SG_ 2566844806 CruiseCtrlSetSpeed "Value of set (chosen) velocity of velocity control system.";
CM_ SG_ 2566844806 pOdometerDriveBit "Alternate state (A->B, B->A) each time the vehicle has moved a defined distance (currently 40m).";
CM_ SG_ 2566844806 CruiseCtrlPauseSw "Switch signal which indicates the positon of the Cruise Control Pause Switch used on Remote Cruise Control applications. The Cruise Control Pause Switch signal temporarily
disables the Cruise Control function.";
CM_ SG_ 2566844806 pCCChecksum "XOR of bytes 0-6 (ensures data is valid before use)";
CM_ SG_ 2566844806 pCruiseEnableStatus "The Cruise Control System has been enabled by the operator.  (Amber Light)";
CM_ BO_ 2565537345 "Used to comfirm that a message has been received by a module.";
CM_ BO_ 2566857216 "Feedback from the engine or motor controller to be used in conjunction with making torque/speed requests.  To be used with PGN 65312 and PGN 65313.";
CM_ SG_ 2566857216 pVehicleSpeed "Indication of the current vehicle speed.";
CM_ SG_ 2566857216 pEngineTorque_Inst_Max "Maximum instantaneous torque available from the engine.";
CM_ SG_ 2566857216 pEngineTorque_Inst_Min "Minimum instantaneous torque available from the engine.";
CM_ SG_ 2566857216 pNorm_Acc_Pos "Indication of the current accelerator pedal position normalized to 0 to 100 %.";
CM_ BO_ 2365530368 "Feedback from the engine or motor controller to be used in conjunction with making torque/speed requests.  To be used with PGN 65312 and PGN 65314.";
CM_ SG_ 2365530368 pChecksum_520571 "Used to verify the signal path from the transmitting device to the receiving device. The message checksum is calculated using the first 7 data bytes, the message counter and the bytes of the message identifier.";
CM_ SG_ 2365530368 pMessageCounter_520570 "Message counter that increments by one for each transmission from 0 to 15 and then rolls over.
The message counter is used to detect situations where the transmitting ECU malfunction repeats the same frame all the time";
CM_ SG_ 2365530368 pEngineSpeed_520569 "Indication of the current engine or motor speed.";
CM_ SG_ 2365530368 pEngineTorque_Driver_Demanded "Indication of the driver demanded engine or motor output torque.";
CM_ SG_ 2365530368 pEngineTorque "Indication of the actual engine or motor output torque.  Estimated torque is acceptable if actual is not available.";
CM_ SG_ 2365530368 pSource_Address_Ctrling_Device "Indication of the source address of the device from which the torque/speed request is being honored.  If an internal torque request is being honored, the controller will transmit its own source address.";
CM_ BO_ 2365530123 "Used to request/limit torque and speed of an engine or motor.  To be used with PGN 65313 and PGN 65314.";
CM_ SG_ 2365530123 pEngCtlMode "Defines which sort of command is used.  Used to tell the engine or motor controller the type of torque/speed request or limit to use.";
CM_ SG_ 2365530123 pEngReqSpeedLimit "used when the pEngine Control Mode is in a speed request or limit mode. This value shall be ignored by the controller when pEngine Control Mode is set to No Control Request, Engine Torque Request, Engine Torque Limit, or any undefined values.";
CM_ SG_ 2365530123 pChecksum_520565 "Used to verify the signal path from the transmitting device to the receiving device. The message checksum is calculated using the first 7 data bytes, the message counter and the bytes of the message identifier.";
CM_ SG_ 2365530123 pMessageCounter_520564 "Message counter that increments by one for each transmission from 0 to 15 and then rolls over.";
CM_ SG_ 2365530123 pEngCtlReq "Used to tell the engine or motor controller what function is the requestor of the torque/speed request or limit.
This mode tells the engine control system the governor characteristics that are desired during speed control.";
CM_ SG_ 2365530123 pEngReqTorqueLimit "Used when the pEngine Control Mode is in a torque request or limit mode. This value shall be ignored by the controller when pEngine Control Mode is set to No Control Request, Engine Speed Request, Engine Speed Limit or any undefined values.
";
CM_ BO_ 2566834822 "Active diagnostic trouble codes";
CM_ SG_ 2566834822 DTC5 "Diagnostic Trouble Code";
CM_ SG_ 2566834822 DTC4 "Diagnostic Trouble Code";
CM_ SG_ 2566834822 DTC3 "Diagnostic Trouble Code";
CM_ SG_ 2566834822 DTC2 "Diagnostic Trouble Code";
CM_ SG_ 2566834822 DTC1 "Diagnostic Trouble Code";
CM_ SG_ 2566834822 DM_FlashRedStopLamp "Flash status of the Red Stop Lamp";
CM_ SG_ 2566834822 DM_FlashProtectLamp "Flash status of the Stop Protect Lamp";
CM_ SG_ 2566834822 DM_FlashMalfuncIndicatorLamp "Flash status of the Malfunction Indicator Lamp";
CM_ SG_ 2566834822 DM_FlashAmberWarningLamp "Flash status of the Amber Warning Lamp";
CM_ SG_ 2566834822 DM_ProtectLampStatus "This lamp is used to relay trouble code informatio that is reporting a problem with a vehicle system that is most
probably not electronic subsystem related.";
CM_ SG_ 2566834822 DM_RedStopLampState "This lamp is uesed to relay trouble code information that is of a severe enought condition that it warrants stopping the vehicle.";
CM_ SG_ 2566834822 DM_AmberWrningLmpStatus "This lamp is used to relay trouble code information that is reporting a problem with the vehicle system but the vehicle need
not be immediately stopped.";
CM_ SG_ 2566834822 DM_MalfuncnIndicatorLampStatus "A lamp used to relay only emissions-related trouble code information.";
CM_ BO_ 2564358137 "Memory Access Response / Output State Control";
CM_ BO_ 2432656519 "Infotaiment Button Status";
CM_ SG_ 2432656519 pInfotainmentJoystick2 "Switch signal which requests that all engine fueling and spark stop.";
CM_ SG_ 2432656519 pInfotainmentJoystick1 "Switch signal which requests that all engine fueling and spark stop.";
CM_ SG_ 2432656519 pInfotainmentRemoteButton01 "Volume Down";
CM_ SG_ 2432656519 pInfotainmentRemoteButton02 "Volume Up";
CM_ SG_ 2432656519 pInfotainmentRemoteButton03 "Tune Down";
CM_ SG_ 2432656519 pInfotainmentRemoteButton04 "Tune Up";
CM_ SG_ 2432656519 pInfotainmentRemoteButton05 "Source";
CM_ SG_ 2432656519 pInfotainmentRemoteButton06 "Mute";
CM_ SG_ 2432656519 pInfotainmentRemoteButton07 "ICOM";
CM_ SG_ 2432656519 pInfotainmentRemoteButton08 "COM";
CM_ SG_ 2432656519 pInfotainmentRemoteButton09 "Squelch (SQ) Down";
CM_ SG_ 2432656519 pInfotainmentRemoteButton10 "Squelch (SQ) Up";
CM_ SG_ 2432656519 pInfotainmentRemoteButton11 "Push To Talk (PTT)";
CM_ SG_ 2432656519 pInfotainmentRemoteButton12 "Preset";
CM_ BO_ 2432656775 "Indicates the status of multiple operator controlled switches.";
CM_ SG_ 2432656775 pOperatorButton29 "Drive Mode - 1()";
CM_ SG_ 2432656775 pOperatorButton1 "Instrument Cluster Control - 1";
CM_ SG_ 2432656775 pOperatorButton2 "Instrument Cluster Control  - 2";
CM_ SG_ 2432656775 pOperatorButton3 "Headlamp - 1 (Low)";
CM_ SG_ 2432656775 pOperatorButton4 "Headlamp - 2 (High)";
CM_ SG_ 2432656775 pOperatorButton5 "Headlamp - 3 (Driving)";
CM_ SG_ 2432656775 pOperatorButton6 "Turn - 1 (Left)";
CM_ SG_ 2432656775 pOperatorButton7 "Turn - 2 (Right)";
CM_ SG_ 2432656775 pOperatorButton8 "Turn - 3 (Cancel)";
CM_ SG_ 2432656775 pOperatorButton9 "Hazard";
CM_ SG_ 2432656775 pOperatorButton10 "Cruise - 1 (On)";
CM_ SG_ 2432656775 pOperatorButton11 "Cruise - 2 (Set)";
CM_ SG_ 2432656775 pOperatorButton12 "Cruise - 3 (Accel)";
CM_ SG_ 2432656775 pOperatorButton13 "Horn";
CM_ SG_ 2432656775 pOperatorButton14 "Start";
CM_ SG_ 2432656775 pOperatorButton15 "Warmer - 1";
CM_ SG_ 2432656775 pOperatorButton16 "Warmer - 2";
CM_ SG_ 2432656775 pOperatorButton17 "Warmer - 3";
CM_ SG_ 2432656775 pOperatorButton18 "Warmer - 4";
CM_ SG_ 2432656775 pOperatorButton19 "Windshield Wiper";
CM_ SG_ 2432656775 pOperatorButton20 "Engine On";
CM_ SG_ 2432656775 pOperatorButton21 "Reverse";
CM_ SG_ 2432656775 pOperatorButton22 "Homelink 1";
CM_ SG_ 2432656775 pOperatorButton23 "Homelink 2";
CM_ SG_ 2432656775 pOperatorButton24 "Throttle Safety Switch - 1";
CM_ SG_ 2432656775 pOperatorButton25 "Windshield - 1 (Up)";
CM_ SG_ 2432656775 pOperatorButton26 "Windshield - 2 (Down)";
CM_ SG_ 2432656775 pOperatorButton27 "Hand Brake Switch";
CM_ SG_ 2432656775 pOperatorButton28 "Clutch Switch";
CM_ SG_ 2432656775 pSideStandStatus "Status of the side stand switch of a motorcycle";
CM_ BO_ 2365449728 "Used for information on a hydraulic brake system.";
CM_ SG_ 2365449728 HydBrakePressCircuit1 "Gague hydraulic pressure in circuit 1 of the hydraulic brake system. For single circuit systems use this SPN. For independant front/rear hydraulic circuits, use this SPN for front brake circuit pressure.";
CM_ SG_ 2365449728 HydBrakePressCircuit2 "Gague hydraulic pressure in circuit 2 of the hydraulic brake system. For independant front/rear hydraulic circuits, use this SPN for rear brake circuit pressure.";
CM_ SG_ 2365449728 HydBrkPressWarnStateCir1 "Signal which indicates whether the hydraulic brake pressure of circuit 1 is below the warning level.";
CM_ SG_ 2365449728 HydBrkPressWarnStateCir2 "Signal which indicates whether the hydraulic brake pressure of circuit 2 is below the warning level.";
CM_ SG_ 2365449728 HydBrkPressSupplyStateCir1 "Signal which indicates whether the hydraulic brake pressure supply of circuit 1 is reliable; that is, able to support continued braking.";
CM_ SG_ 2365449728 HydBrkPressSupplyStateCir2 "Signal which indicates whether the hydraulic brake pressure supply of circuit 2 is reliable; that is, able to support continued braking.";
CM_ SG_ 2365449728 HydBrakeFluidLevelSwitch "Signal which indicates whether the hydraulic fluid level in the reservoir(s) is sufficient.";
CM_ BO_ 2566884352 "Torque Data of Engine";
CM_ SG_ 2566884352 pCurrentRPMRatedTorque "Contains the rated torque for the current RPM (un-throttled and optimal spark).";
CM_ SG_ 2566884352 pEstimatedTorque "Estimated torque value based on current engine conditions.";
CM_ SG_ 2566884352 BrakeSwitch "Switch signal which indicates that the driver operated brake foot pedal is being pressed";
CM_ SG_ 2566884352 MessageChecksum_GM "The message checksum is used to verify the signal path from the transmitting device to the receiving device.";
CM_ BO_ 2566842396 "Vehicle dynamics information";
CM_ SG_ 2566842396 CompassBearing "Present compass bearing of vehicle.";
CM_ BO_ 2566877607 "Instrument Cluster Information";
CM_ SG_ 2566877607 pVolumeUnitsSelected "Active display volume units beased on user selection or auto-configuration.";
CM_ SG_ 2566877607 pTimeUnitsSelected "Active display time units beased on user selection or auto-configuration.";
CM_ SG_ 2566877607 pTemperatureUnitsSelected "Active display temperature units beased on user selection or auto-configuration.";
CM_ SG_ 2566877607 pPressureUnitsSelected "Active display pressure units beased on user selection or auto-configuration.";
CM_ SG_ 2566877607 pHighResTrip2Distance "Secondary distance travled during all or part of a journey.";
CM_ SG_ 2566877607 pDistanceUnitsSelected "Active display distance units beased on user selection or auto-configuration.";
CM_ SG_ 2566877607 pTPMSLearningStatus "Status of the Tire Pressure Monitor System learning process.";
CM_ SG_ 2566877607 pDisplayStatus "Status of the radio display to the radio stating what the display is showing";
CM_ SG_ 2381320220 NMEA_SID "Switch signal which indicates whether the accelerator pedal low idle switch is opened or closed.";
CM_ SG_ 2583298844 NMEA_SID "Switch signal which indicates whether the accelerator pedal low idle switch is opened or closed.";
CM_ SG_ 2314732060 NMEA_SID "Switch signal which indicates whether the accelerator pedal low idle switch is opened or closed.";
BA_DEF_ SG_  "GenSigSendType" ENUM  "Cyclic","OnWrite","OnWriteWithRepetition","OnChange","OnChangeWithRepetition","IfActive","IfActiveWithRepetition","NoSigSendType";
BA_DEF_ SG_  "GenSigStartValue" INT 0 10000;
BA_DEF_ SG_  "GenSigEVName" STRING ;
BA_DEF_ SG_  "SPN" INT 0 524287;
BA_DEF_ SG_  "SigType" ENUM  "Default","Range","RangeSigned","ASCII","Discrete","Control","ReferencePGN","DTC","StringDelimiter","StringLength","StringLengthControl","MessageCounter","MessageChecksum";
BA_DEF_ SG_  "GenSigILSupport" ENUM  "No","Yes";
BA_DEF_ BO_  "GenMsgCycleTimeFast" INT 0 3600000;
BA_DEF_ BO_  "GenMsgILSupport" ENUM  "No","Yes";
BA_DEF_ BO_  "J1939PGNameSecSrc0Dest3" STRING ;
BA_DEF_ BO_  "J1939PGRelationDest3Src0" INT 0 254;
BA_DEF_ BO_  "J1939PGtoECUSrc0Dest3" INT 0 254;
BA_DEF_ BO_  "J1939PGtoWSMSrc0Dest3" INT 0 254;
BA_DEF_ BO_  "J1939PGRelationSrc0Dest3" INT 0 254;
BA_DEF_ BO_  "J1939PGRepTypeSrc0Dest3" INT 0 4;
BA_DEF_ BO_  "J1939PGRepCycleSrc0Dest3" INT -1 65535;
BA_DEF_ BO_  "J1939PGPrioSrc0Dest3" INT 0 7;
BA_DEF_ BO_  "J1939PGRepetitionType" ENUM  "always","when active","on request";
BA_DEF_ BO_  "J1939PGRepetitionCycle" INT 0 65535;
BA_DEF_ BO_  "J1939PGPrio" INT 0 7;
BA_DEF_ BO_  "VFrameFormat" ENUM  "StandardCAN","ExtendedCAN","reserved","J1939PG";
BA_DEF_ BO_  "GenMsgCycleTime" INT 0 3600000;
BA_DEF_ BO_  "GenMsgRequestable" INT 0 1;
BA_DEF_ BO_  "GenMsgSendType" ENUM  "cyclic","spontaneous","cyclicIfActive","spontaneousWithDelay","cyclicAndSpontaneous","cyclicAndSpontaneousWithDelay","spontaneousWithRepetition","cyclicIfActiveAndSpontaneousWD";
BA_DEF_DEF_  "GenSigSendType" "NoSigSendType";
BA_DEF_DEF_  "GenSigStartValue" 0;
BA_DEF_DEF_  "GenSigEVName" "Env@Nodename_@Signame";
BA_DEF_DEF_  "SPN" 0;
BA_DEF_DEF_  "SigType" "Default";
BA_DEF_DEF_  "GenSigILSupport" "Yes";
BA_DEF_DEF_  "GenMsgCycleTimeFast" 0;
BA_DEF_DEF_  "GenMsgILSupport" "Yes";
BA_DEF_DEF_  "J1939PGNameSecSrc0Dest3" "(null)";
BA_DEF_DEF_  "J1939PGRelationDest3Src0" 254;
BA_DEF_DEF_  "J1939PGtoECUSrc0Dest3" -1;
BA_DEF_DEF_  "J1939PGtoWSMSrc0Dest3" -1;
BA_DEF_DEF_  "J1939PGRelationSrc0Dest3" 254;
BA_DEF_DEF_  "J1939PGRepTypeSrc0Dest3" 3;
BA_DEF_DEF_  "J1939PGRepCycleSrc0Dest3" -1;
BA_DEF_DEF_  "J1939PGPrioSrc0Dest3" 6;
BA_DEF_DEF_  "J1939PGRepetitionType" "always";
BA_DEF_DEF_  "J1939PGRepetitionCycle" 100;
BA_DEF_DEF_  "J1939PGPrio" 6;
BA_DEF_DEF_  "VFrameFormat" "J1939PG";
BA_DEF_DEF_  "GenMsgCycleTime" 0;
BA_DEF_DEF_  "GenMsgRequestable" 1;
BA_DEF_DEF_  "GenMsgSendType" "cyclic";
BA_ "GenMsgCycleTime" BO_ 2566902272 100;
BA_ "GenMsgCycleTime" BO_ 2566847578 1000;
BA_ "GenMsgCycleTimeFast" BO_ 2566878604 10;
BA_ "GenMsgCycleTime" BO_ 2566878604 200;
BA_ "GenMsgSendType" BO_ 2566878604 4;
BA_ "GenMsgCycleTime" BO_ 2566878464 10;
BA_ "GenMsgCycleTime" BO_ 2566876928 1000;
BA_ "GenMsgCycleTime" BO_ 2566853886 100;
BA_ "GenMsgCycleTime" BO_ 2566876416 100;
BA_ "GenMsgCycleTime" BO_ 2566825472 500;
BA_ "GenMsgCycleTime" BO_ 2297441780 10;
BA_ "GenMsgCycleTime" BO_ 2566846452 1000;
BA_ "J1939PGRepetitionCycle" BO_ 2297441779 10;
BA_ "GenMsgCycleTime" BO_ 2297441779 10;
BA_ "GenMsgCycleTime" BO_ 2566846451 1000;
BA_ "GenMsgCycleTime" BO_ 2365525748 10;
BA_ "GenMsgCycleTime" BO_ 2365525747 10;
BA_ "GenMsgCycleTime" BO_ 2298415350 100;
BA_ "GenMsgCycleTime" BO_ 2298415606 100;
BA_ "GenMsgCycleTime" BO_ 2298415351 100;
BA_ "GenMsgCycleTime" BO_ 2298415607 100;
BA_ "GenMsgCycleTimeFast" BO_ 2365523456 50;
BA_ "GenMsgCycleTime" BO_ 2365523456 5000;
BA_ "GenMsgSendType" BO_ 2365523456 4;
BA_ "GenMsgCycleTime" BO_ 2298415346 100;
BA_ "GenMsgCycleTime" BO_ 2298415602 100;
BA_ "GenMsgCycleTime" BO_ 2298415345 100;
BA_ "GenMsgCycleTime" BO_ 2298415601 100;
BA_ "GenMsgCycleTime" BO_ 2298415344 100;
BA_ "GenMsgCycleTime" BO_ 2298415600 100;
BA_ "GenMsgCycleTime" BO_ 2298415343 100;
BA_ "GenMsgCycleTime" BO_ 2298415599 100;
BA_ "GenMsgCycleTime" BO_ 2566845696 1000;
BA_ "GenMsgCycleTime" BO_ 2566844672 100;
BA_ "GenMsgCycleTime" BO_ 2364539904 100;
BA_ "GenMsgCycleTime" BO_ 2565866752 100;
BA_ "GenMsgCycleTime" BO_ 2566843904 1000;
BA_ "GenMsgCycleTime" BO_ 2566844928 100;
BA_ "GenMsgCycleTime" BO_ 2566845952 500;
BA_ "GenMsgCycleTime" BO_ 2566846208 1000;
BA_ "GenMsgCycleTime" BO_ 2566844806 100;
BA_ "GenMsgSendType" BO_ 2566844806 4.90833586961908E-316;
BA_ "GenMsgCycleTime" BO_ 2565537345 100;
BA_ "GenMsgSendType" BO_ 2565537345 4.90720860944153E-316;
BA_ "GenMsgCycleTime" BO_ 2566857216 10;
BA_ "GenMsgCycleTime" BO_ 2365530368 10;
BA_ "GenMsgCycleTime" BO_ 2365530123 10;
BA_ "GenMsgCycleTime" BO_ 2566834822 100;
BA_ "GenMsgSendType" BO_ 2566834822 4.90264818590416E-316;
BA_ "GenMsgCycleTime" BO_ 2564358137 100;
BA_ "GenMsgCycleTime" BO_ 2432656519 200;
BA_ "GenMsgSendType" BO_ 2432656519 1.79355710753289E-316;
BA_ "GenMsgCycleTime" BO_ 2432656775 100;
BA_ "GenMsgSendType" BO_ 2432656775 1.7919428962548E-316;
BA_ "GenMsgCycleTime" BO_ 2365449728 100;
BA_ "GenMsgSendType" BO_ 2365449728 1.79186147423637E-316;
BA_ "GenMsgCycleTime" BO_ 2566884352 20;
BA_ "GenMsgSendType" BO_ 2566884352 1.78475167196645E-316;
BA_ "GenMsgCycleTime" BO_ 2566842396 100;
BA_ "GenMsgSendType" BO_ 2566842396 1.78376354067477E-316;
BA_ "GenMsgCycleTime" BO_ 2566877607 1000;
BA_ "GenMsgSendType" BO_ 2566877607 1.80827947327393E-316;
BA_ "GenMsgCycleTime" BO_ 2381320220 100;
BA_ "GenMsgSendType" BO_ 2381320220 1.8082383670122E-316;
BA_ "GenMsgCycleTime" BO_ 2314731804 100;
BA_ "GenMsgSendType" BO_ 2314731804 1.80822967145683E-316;
BA_ "GenMsgCycleTime" BO_ 2583298844 100;
BA_ "GenMsgSendType" BO_ 2583298844 1.80822571893166E-316;
BA_ "GenMsgCycleTime" BO_ 2314732060 100;
BA_ "GenMsgSendType" BO_ 2314732060 1.80820911832596E-316;
BA_ "SigType" SG_ 2566910976 FI2_ADCOutput 1.7E-308;
BA_ "SigType" SG_ 2566910976 FI2_RearDiffLockOutput 1.7E-308;
BA_ "SigType" SG_ 2566910976 FI2_AWDOutput 1.7E-308;
BA_ "SigType" SG_ 2566910976 FI2_BrakeSwitchInput 1.7E-308;
BA_ "SigType" SG_ 2566910976 FI2_ADCSwitchInput 1.7E-308;
BA_ "SigType" SG_ 2566910976 FI2_TurfModeInput 1.7E-308;
BA_ "SigType" SG_ 2566910976 FI2_AWDSwitchInput 1.7E-308;
BA_ "SigType" SG_ 2566910976 FI2_ReverseSwitchInput 1.7E-308;
BA_ "SigType" SG_ 2566910976 FI2_ReverseLimitSwitchInput 1.7E-308;
BA_ "SigType" SG_ 2566910976 FI2_ForwardLimitSwitchInput 1.7E-308;
BA_ "SigType" SG_ 2566910976 FI2_EngineDirection 1.7E-308;
BA_ "SigType" SG_ 2566910976 FI2_RevSpeedLimitOverrideInput 1.7E-308;
BA_ "SigType" SG_ 2566910976 FI2_ReverseOverspeedSignal 1.7E-308;
BA_ "SigType" SG_ 2566910976 FI2_RightTurnSignalInput 1.7E-308;
BA_ "SigType" SG_ 2566910976 FI2_LeftTurnSignalInput 1.7E-308;
BA_ "SigType" SG_ 2566910976 FI2_KickstandSwitchInput 1.7E-308;
BA_ "SigType" SG_ 2566910976 FI2_ReflashEnableInputSignal 1.7E-308;
BA_ "SigType" SG_ 2566910976 FI2_TPSLearnInputSignal 1.7E-308;
BA_ "SigType" SG_ 2566910976 FI2_LowRangeSwitchInput 1.7E-308;
BA_ "SigType" SG_ 2566910976 FI2_ReverseMotorDriveInput 1.7E-308;
BA_ "SigType" SG_ 2566910208 FI5_b10Sec 1.7E-308;
BA_ "SigType" SG_ 2566910208 FI5_bBatt 1.7E-308;
BA_ "SigType" SG_ 2566910208 FI5_bEnable 1.7E-308;
BA_ "SigType" SG_ 2566910208 FI5_bLazyCRC 1.7E-308;
BA_ "SigType" SG_ 2566910208 FI5_bManCyc 1.7E-308;
BA_ "SigType" SG_ 2566910208 FI5_bNotRun 1.7E-308;
BA_ "SigType" SG_ 2566910208 FI5_bOper 1.7E-308;
BA_ "SigType" SG_ 2566908160 DL18_DesiredTorqueChg 1.7E-308;
BA_ "SigType" SG_ 2566908160 DL18_ThrottleAngleCorrFactor 1.7E-308;
BA_ "SigType" SG_ 2566908160 DL18_DragTorqueAdapt 1.7E-308;
BA_ "SPN" SG_ 2633984768 pADCModeAvailability 524143;
BA_ "SPN" SG_ 2633984768 pAWDModeAvailability 524142;
BA_ "SPN" SG_ 2633984768 pTurfModeAvailability 524140;
BA_ "SPN" SG_ 2633984768 pDisplayedSpeedCorrectionFactor 524014;
BA_ "SigType" SG_ 2633984768 pDisplayedSpeedCorrectionFactor 1.7E-308;
BA_ "SPN" SG_ 2633984768 pInstrumentBacklightIntensity 524015;
BA_ "SigType" SG_ 2633984768 pInstrumentBacklightIntensity 1.7E-308;
BA_ "SPN" SG_ 2633984768 pWarningLampIntensity 524016;
BA_ "SigType" SG_ 2633984768 pWarningLampIntensity 1.7E-308;
BA_ "SPN" SG_ 2633984768 pFuelTankVolume 524089;
BA_ "SigType" SG_ 2633984768 pFuelTankVolume 1.7E-308;
BA_ "SPN" SG_ 2633984768 pLowFuelLightONPercentage 524090;
BA_ "SigType" SG_ 2633984768 pLowFuelLightONPercentage 1.7E-308;
BA_ "SPN" SG_ 2633984768 pFuelLevelDataSource 524091;
BA_ "SigType" SG_ 2633984768 pFuelLevelDataSource 1.7E-308;
BA_ "SPN" SG_ 2633984768 pVehicleUnitsConfig 524093;
BA_ "SigType" SG_ 2633984768 pVehicleUnitsConfig 1.7E-308;
BA_ "SPN" SG_ 2633984768 pFuelEconomyDataSource 524094;
BA_ "SigType" SG_ 2633984768 pFuelEconomyDataSource 1.7E-308;
BA_ "SPN" SG_ 2633984768 pSeatBeltInputSource 524095;
BA_ "SigType" SG_ 2633984768 pSeatBeltInputSource 1.7E-308;
BA_ "SigType" SG_ 2566902272 DL_InjectorBankAPulseWidth 1.7E-308;
BA_ "SigType" SG_ 2566902272 DL_InjectorBankBPulseWidth 1.7E-308;
BA_ "SigType" SG_ 2566902272 DL_FuelConsumptionRate 1.7E-308;
BA_ "SigType" SG_ 2566902272 DL_FuelSelectInput 1.7E-308;
BA_ "SigType" SG_ 2566910720 FI3_DriveMode1Input 1.7E-308;
BA_ "SigType" SG_ 2566910720 FI3_DriveMode2Input 1.7E-308;
BA_ "SigType" SG_ 2566910720 FI3_DriveMode3Input 1.7E-308;
BA_ "SigType" SG_ 2566910720 FI3_DriverMode4Input 1.7E-308;
BA_ "SigType" SG_ 2566910720 FI3_DriverMode1Output 1.7E-308;
BA_ "SigType" SG_ 2566910720 FI3_DriverMode2Output 1.7E-308;
BA_ "SigType" SG_ 2566910720 FI3_DriverMode3Output 1.7E-308;
BA_ "SigType" SG_ 2566910720 FI3_DriverMode4Ouput 1.7E-308;
BA_ "SigType" SG_ 2566910720 FI3_PTOModeInput 1.7E-308;
BA_ "SigType" SG_ 2566910720 FI3_PTOModeOutput 1.7E-308;
BA_ "SigType" SG_ 2566910720 FI3_DriversNetEngagement 1.7E-308;
BA_ "SigType" SG_ 2566910720 FI3_DriversSeatbeltEngagement 1.7E-308;
BA_ "SigType" SG_ 2566910720 FI3_TiltLockInput 1.7E-308;
BA_ "SigType" SG_ 2566910720 FI3_WorkGroupLockInput 1.7E-308;
BA_ "SigType" SG_ 2566910720 FI3_OperatorPresenceInput 1.7E-308;
BA_ "SigType" SG_ 2566910720 FI3_WorkGroupLockOutput 1.7E-308;
BA_ "SigType" SG_ 2566910720 FI3_OperatorPresenceOutput 1.7E-308;
BA_ "SigType" SG_ 2566910720 FI3_FootOnCruiseInput 1.7E-308;
BA_ "SigType" SG_ 2566910720 FI3_CruiseInput 1.7E-308;
BA_ "SigType" SG_ 2566910720 FI3_TredalInput 1.7E-308;
BA_ "SigType" SG_ 2566910720 FI3_CruiseSpeedInput 1.7E-308;
BA_ "SigType" SG_ 2566910720 FI3_FootOnCruiseOutput 1.7E-308;
BA_ "SigType" SG_ 2566910720 FI3_CruiseOutput 1.7E-308;
BA_ "SigType" SG_ 2566910720 FI3_CruiseControltoSetSpeed 1.7E-308;
BA_ "SigType" SG_ 2566910720 FI3_WorkModeInput 1.7E-308;
BA_ "SigType" SG_ 2566910720 FI3_TiltLockOutput 1.7E-308;
BA_ "SigType" SG_ 2566910464 FI4_BrakeLightOutput 1.7E-308;
BA_ "SigType" SG_ 2566910464 FI4_FogLightInput 1.7E-308;
BA_ "SigType" SG_ 2566910464 FI4_HazardLightOutput 1.7E-308;
BA_ "SigType" SG_ 2566910464 FI4_HazardSWInput 1.7E-308;
BA_ "SigType" SG_ 2566910464 FI4_HeatGripDecSW 1.7E-308;
BA_ "SigType" SG_ 2566910464 FI4_HeatGripIncSW 1.7E-308;
BA_ "SigType" SG_ 2566910464 FI4_HighBeamOutput 1.7E-308;
BA_ "SigType" SG_ 2566910464 FI4_HornInput 1.7E-308;
BA_ "SigType" SG_ 2566910464 FI4_HornOutput 1.7E-308;
BA_ "SigType" SG_ 2566910464 FI4_LeftFogLightOutput 1.7E-308;
BA_ "SigType" SG_ 2566910464 FI4_LFTurnSignalOutput 1.7E-308;
BA_ "SigType" SG_ 2566910464 FI4_LockInput 1.7E-308;
BA_ "SigType" SG_ 2566910464 FI4_LowBeamOutput 1.7E-308;
BA_ "SigType" SG_ 2566910464 FI4_LowHighBeamInput 1.7E-308;
BA_ "SigType" SG_ 2566910464 FI4_LRTurnSignalOutput 1.7E-308;
BA_ "SigType" SG_ 2566910464 FI4_pOperatorButton1 1.7E-308;
BA_ "SigType" SG_ 2566910464 FI4_RFTurnSignalOutput 1.7E-308;
BA_ "SigType" SG_ 2566910464 FI4_RightFogLightOutput 1.7E-308;
BA_ "SigType" SG_ 2566910464 FI4_RRTurnSignalOutput 1.7E-308;
BA_ "SigType" SG_ 2566910464 FI4_SecondaryAirValveCmd 1.7E-308;
BA_ "SigType" SG_ 2566910464 FI4_SecondaryAirValveOut 1.7E-308;
BA_ "SigType" SG_ 2566910464 FI4_TailLightOutput 1.7E-308;
BA_ "SigType" SG_ 2566910464 FI4_UnlockInput 1.7E-308;
BA_ "SigType" SG_ 2566910464 FI4_WindshieldSWDownInput 1.7E-308;
BA_ "SigType" SG_ 2566910464 FI4_WindshieldSWUpInput 1.7E-308;
BA_ "SigType" SG_ 2566910464 FI4_pOperatorButton2 1.7E-308;
BA_ "SigType" SG_ 2566907904 DL19_TirePressure_Rear_Left_Only 1.7E-308;
BA_ "SigType" SG_ 2566907904 DL19_TirePressureFront_Left_Only 1.7E-308;
BA_ "SigType" SG_ 2566907904 DL19_TirePressureFrontRight 1.7E-308;
BA_ "SigType" SG_ 2566907904 DL19_TirePressureRearRight 1.7E-308;
BA_ "SigType" SG_ 2566907648 DL20_KeyFobBatteryVoltage 1.7E-308;
BA_ "SigType" SG_ 2566907648 DL20_LeanAngle 1.7E-308;
BA_ "SPN" SG_ 2566847578 WasherFluidLevel 80;
BA_ "SigType" SG_ 2566847578 WasherFluidLevel 1.7E-308;
BA_ "SPN" SG_ 2566847578 FuelLevel 96;
BA_ "SigType" SG_ 2566847578 FuelLevel 1.7E-308;
BA_ "SPN" SG_ 2566847578 FuelFilterDiffPressure 95;
BA_ "SigType" SG_ 2566847578 FuelFilterDiffPressure 1.7E-308;
BA_ "SPN" SG_ 2566847578 EngineOilFilterDiffPressure 99;
BA_ "SigType" SG_ 2566847578 EngineOilFilterDiffPressure 1.7E-308;
BA_ "SPN" SG_ 2566847578 CargoAmbientTemperature 169;
BA_ "SigType" SG_ 2566847578 CargoAmbientTemperature 1.7E-308;
BA_ "SPN" SG_ 2566878604 pChecksum_524123 524123;
BA_ "SPN" SG_ 2566878604 pMessageCounter_524122 524122;
BA_ "SPN" SG_ 2566878604 pOperationMode 524120;
BA_ "SPN" SG_ 2566878604 pStartStopCmd 520497;
BA_ "SPN" SG_ 2566878604 pNorm_Acc_Pos_520354 520354;
BA_ "SPN" SG_ 2566878464 pStartStopCmd 520497;
BA_ "SPN" SG_ 2566878464 pPedalPositionCommand 524121;
BA_ "SPN" SG_ 2566878464 pOperationMode 524120;
BA_ "SPN" SG_ 2566876928 pSecondaryAirValveControl 524083;
BA_ "SPN" SG_ 2566853886 pRangeToEmptyEV 520529;
BA_ "SPN" SG_ 2566853886 pEfficiencyEV 520528;
BA_ "SPN" SG_ 2566876416 pDriveModeCommanded 524077;
BA_ "SPN" SG_ 2566876416 pFootOnCruiseControlEnabled 524073;
BA_ "SPN" SG_ 2566876416 pDriveModeRequested 524067;
BA_ "SPN" SG_ 2566825472 EngineTurbo1BoostPressure 1127;
BA_ "SPN" SG_ 2566804212 NetBattCurrentHiRange 2579;
BA_ "SPN" SG_ 2566804211 NetBattCurrentHiRange 2579;
BA_ "SPN" SG_ 2297441780 Vertical_Accel_Ext_Range 5349;
BA_ "SPN" SG_ 2297441780 Vertical_Accel_Ext_Merit 5352;
BA_ "SPN" SG_ 2297441780 Longitudinal_Accel_Ext_Range 5348;
BA_ "SPN" SG_ 2297441780 Longitudinal_Accel_Ext_Merit 5351;
BA_ "SPN" SG_ 2297441780 Lateral_Accel_Ext_Range 5347;
BA_ "SPN" SG_ 2297441780 Lateral_Accel_Ext_Merit 5350;
BA_ "SPN" SG_ 2297441780 Accel_Sensor_Support_Var 5353;
BA_ "SPN" SG_ 2566846452 Net_Battery_Current 114;
BA_ "SPN" SG_ 2566846452 BatteryPotential 168;
BA_ "SigType" SG_ 2566846452 BatteryPotential 1.7E-308;
BA_ "SPN" SG_ 2297441779 Vertical_Accel_Ext_Range 5349;
BA_ "SPN" SG_ 2297441779 Vertical_Accel_Ext_Merit 5352;
BA_ "SPN" SG_ 2297441779 Longitudinal_Accel_Ext_Range 5348;
BA_ "SPN" SG_ 2297441779 Longitudinal_Accel_Ext_Merit 5351;
BA_ "SPN" SG_ 2297441779 Lateral_Accel_Ext_Range 5347;
BA_ "SPN" SG_ 2297441779 Lateral_Accel_Ext_Merit 5350;
BA_ "SPN" SG_ 2297441779 Accel_Sensor_Support_Var 5353;
BA_ "SPN" SG_ 2566846451 Net_Battery_Current 114;
BA_ "SPN" SG_ 2566846451 BatteryPotential 168;
BA_ "SigType" SG_ 2566846451 BatteryPotential 1.7E-308;
BA_ "SPN" SG_ 2365525748 WATT_pPack_Voltage 524217;
BA_ "SPN" SG_ 2365525748 WATT_pPack_Current 524216;
BA_ "SPN" SG_ 2365525748 WATT_pDischarge_Limit 524218;
BA_ "SPN" SG_ 2365525748 WATT_pCharge_Limit 524219;
BA_ "SPN" SG_ 2365525748 WATT_pBMC_Pwr_Msg_Check_Seq 524252;
BA_ "SPN" SG_ 2365525747 WATT_pPack_Voltage 524217;
BA_ "SPN" SG_ 2365525747 WATT_pPack_Current 524216;
BA_ "SPN" SG_ 2365525747 WATT_pDischarge_Limit 524218;
BA_ "SPN" SG_ 2365525747 WATT_pCharge_Limit 524219;
BA_ "SPN" SG_ 2365525747 WATT_pBMC_Pwr_Msg_Check_Seq 524252;
BA_ "SPN" SG_ 2298415350 WATT_pSpeed_Lim_Cutback_Status 524258;
BA_ "SPN" SG_ 2298415350 WATT_pMotor_Therm_Cutback 524260;
BA_ "SPN" SG_ 2298415350 WATT_pMotor_Power_Cutback_Status 524240;
BA_ "SPN" SG_ 2298415350 WATT_pI_DC_Cutback_Status 524257;
BA_ "SPN" SG_ 2298415350 WATT_pController_Therm_Cutback 524259;
BA_ "SPN" SG_ 2298415350 WATT_pPower_Msg_Check_Seq 524250;
BA_ "SPN" SG_ 2298415350 WATT_pInput_Current 524195;
BA_ "SPN" SG_ 2298415350 WATT_pCapacitor_Voltage 524196;
BA_ "SPN" SG_ 2298415606 WATT_pTemperature_Msg_Check_Seq 524251;
BA_ "SPN" SG_ 2298415606 WATT_pMotor_Temp_Margin 524198;
BA_ "SPN" SG_ 2298415606 WATT_pMotor_Temp 524201;
BA_ "SPN" SG_ 2298415606 WATT_pJunction_Temp 524203;
BA_ "SPN" SG_ 2298415606 WATT_pController_Temp_Margin 524197;
BA_ "SPN" SG_ 2298415606 WATT_pCapacitor_Temp 524202;
BA_ "SPN" SG_ 2298415606 WATT_pBoard_Temp 524200;
BA_ "SPN" SG_ 2298415606 WATT_pBaseplate_Temp 524199;
BA_ "SPN" SG_ 2298415351 WATT_pSpeed_Lim_Cutback_Status 524258;
BA_ "SPN" SG_ 2298415351 WATT_pMotor_Therm_Cutback 524260;
BA_ "SPN" SG_ 2298415351 WATT_pMotor_Power_Cutback_Status 524240;
BA_ "SPN" SG_ 2298415351 WATT_pI_DC_Cutback_Status 524257;
BA_ "SPN" SG_ 2298415351 WATT_pController_Therm_Cutback 524259;
BA_ "SPN" SG_ 2298415351 WATT_pPower_Msg_Check_Seq 524250;
BA_ "SPN" SG_ 2298415351 WATT_pInput_Current 524195;
BA_ "SPN" SG_ 2298415351 WATT_pCapacitor_Voltage 524196;
BA_ "SPN" SG_ 2298415607 WATT_pTemperature_Msg_Check_Seq 524251;
BA_ "SPN" SG_ 2298415607 WATT_pMotor_Temp_Margin 524198;
BA_ "SPN" SG_ 2298415607 WATT_pMotor_Temp 524201;
BA_ "SPN" SG_ 2298415607 WATT_pJunction_Temp 524203;
BA_ "SPN" SG_ 2298415607 WATT_pController_Temp_Margin 524197;
BA_ "SPN" SG_ 2298415607 WATT_pCapacitor_Temp 524202;
BA_ "SPN" SG_ 2298415607 WATT_pBoard_Temp 524200;
BA_ "SPN" SG_ 2298415607 WATT_pBaseplate_Temp 524199;
BA_ "SPN" SG_ 2365523456 pModCtlMsg_Checksum 516097;
BA_ "SPN" SG_ 2365523456 pModCtlAppliedState 516096;
BA_ "SPN" SG_ 2365523456 pModCtlCmdDestAdd 524185;
BA_ "SPN" SG_ 2365523456 pModCtlCmdState 524248;
BA_ "SPN" SG_ 2298415346 WATT_pSpeed_Lim_Cutback_Status 524258;
BA_ "SPN" SG_ 2298415346 WATT_pMotor_Therm_Cutback 524260;
BA_ "SPN" SG_ 2298415346 WATT_pMotor_Power_Cutback_Status 524240;
BA_ "SPN" SG_ 2298415346 WATT_pI_DC_Cutback_Status 524257;
BA_ "SPN" SG_ 2298415346 WATT_pController_Therm_Cutback 524259;
BA_ "SPN" SG_ 2298415346 WATT_pPower_Msg_Check_Seq 524250;
BA_ "SPN" SG_ 2298415346 WATT_pInput_Current 524195;
BA_ "SPN" SG_ 2298415346 WATT_pCapacitor_Voltage 524196;
BA_ "SPN" SG_ 2298415602 WATT_pTemperature_Msg_Check_Seq 524251;
BA_ "SPN" SG_ 2298415602 WATT_pMotor_Temp_Margin 524198;
BA_ "SPN" SG_ 2298415602 WATT_pMotor_Temp 524201;
BA_ "SPN" SG_ 2298415602 WATT_pJunction_Temp 524203;
BA_ "SPN" SG_ 2298415602 WATT_pController_Temp_Margin 524197;
BA_ "SPN" SG_ 2298415602 WATT_pCapacitor_Temp 524202;
BA_ "SPN" SG_ 2298415602 WATT_pBoard_Temp 524200;
BA_ "SPN" SG_ 2298415602 WATT_pBaseplate_Temp 524199;
BA_ "SPN" SG_ 2298415345 WATT_pSpeed_Lim_Cutback_Status 524258;
BA_ "SPN" SG_ 2298415345 WATT_pMotor_Therm_Cutback 524260;
BA_ "SPN" SG_ 2298415345 WATT_pMotor_Power_Cutback_Status 524240;
BA_ "SPN" SG_ 2298415345 WATT_pI_DC_Cutback_Status 524257;
BA_ "SPN" SG_ 2298415345 WATT_pController_Therm_Cutback 524259;
BA_ "SPN" SG_ 2298415345 WATT_pPower_Msg_Check_Seq 524250;
BA_ "SPN" SG_ 2298415345 WATT_pInput_Current 524195;
BA_ "SPN" SG_ 2298415345 WATT_pCapacitor_Voltage 524196;
BA_ "SPN" SG_ 2298415601 WATT_pTemperature_Msg_Check_Seq 524251;
BA_ "SPN" SG_ 2298415601 WATT_pMotor_Temp_Margin 524198;
BA_ "SPN" SG_ 2298415601 WATT_pMotor_Temp 524201;
BA_ "SPN" SG_ 2298415601 WATT_pJunction_Temp 524203;
BA_ "SPN" SG_ 2298415601 WATT_pController_Temp_Margin 524197;
BA_ "SPN" SG_ 2298415601 WATT_pCapacitor_Temp 524202;
BA_ "SPN" SG_ 2298415601 WATT_pBoard_Temp 524200;
BA_ "SPN" SG_ 2298415601 WATT_pBaseplate_Temp 524199;
BA_ "SPN" SG_ 2298415344 WATT_pSpeed_Lim_Cutback_Status 524258;
BA_ "SPN" SG_ 2298415344 WATT_pMotor_Therm_Cutback 524260;
BA_ "SPN" SG_ 2298415344 WATT_pMotor_Power_Cutback_Status 524240;
BA_ "SPN" SG_ 2298415344 WATT_pI_DC_Cutback_Status 524257;
BA_ "SPN" SG_ 2298415344 WATT_pController_Therm_Cutback 524259;
BA_ "SPN" SG_ 2298415344 WATT_pPower_Msg_Check_Seq 524250;
BA_ "SPN" SG_ 2298415344 WATT_pInput_Current 524195;
BA_ "SPN" SG_ 2298415344 WATT_pCapacitor_Voltage 524196;
BA_ "SPN" SG_ 2298415600 WATT_pTemperature_Msg_Check_Seq 524251;
BA_ "SPN" SG_ 2298415600 WATT_pMotor_Temp_Margin 524198;
BA_ "SPN" SG_ 2298415600 WATT_pMotor_Temp 524201;
BA_ "SPN" SG_ 2298415600 WATT_pJunction_Temp 524203;
BA_ "SPN" SG_ 2298415600 WATT_pController_Temp_Margin 524197;
BA_ "SPN" SG_ 2298415600 WATT_pCapacitor_Temp 524202;
BA_ "SPN" SG_ 2298415600 WATT_pBoard_Temp 524200;
BA_ "SPN" SG_ 2298415600 WATT_pBaseplate_Temp 524199;
BA_ "SPN" SG_ 2298415343 WATT_pController_Therm_Cutback 524259;
BA_ "SPN" SG_ 2298415343 WATT_pSpeed_Lim_Cutback_Status 524258;
BA_ "SPN" SG_ 2298415343 WATT_pMotor_Therm_Cutback 524260;
BA_ "SPN" SG_ 2298415343 WATT_pMotor_Power_Cutback_Status 524240;
BA_ "SPN" SG_ 2298415343 WATT_pI_DC_Cutback_Status 524257;
BA_ "SPN" SG_ 2298415343 WATT_pPower_Msg_Check_Seq 524250;
BA_ "SPN" SG_ 2298415343 WATT_pInput_Current 524195;
BA_ "SPN" SG_ 2298415343 WATT_pCapacitor_Voltage 524196;
BA_ "SPN" SG_ 2298415599 WATT_pTemperature_Msg_Check_Seq 524251;
BA_ "SPN" SG_ 2298415599 WATT_pMotor_Temp_Margin 524198;
BA_ "SPN" SG_ 2298415599 WATT_pMotor_Temp 524201;
BA_ "SPN" SG_ 2298415599 WATT_pJunction_Temp 524203;
BA_ "SPN" SG_ 2298415599 WATT_pController_Temp_Margin 524197;
BA_ "SPN" SG_ 2298415599 WATT_pCapacitor_Temp 524202;
BA_ "SPN" SG_ 2298415599 WATT_pBoard_Temp 524200;
BA_ "SPN" SG_ 2298415599 WATT_pBaseplate_Temp 524199;
BA_ "SPN" SG_ 2566845696 DL_BarometricPressure 108;
BA_ "SigType" SG_ 2566845696 DL_BarometricPressure 1.7E-308;
BA_ "SPN" SG_ 2566845696 CabInteriorTemperature 170;
BA_ "SigType" SG_ 2566845696 CabInteriorTemperature 1.7E-308;
BA_ "SPN" SG_ 2566845696 AmbientAirTemperature 171;
BA_ "SigType" SG_ 2566845696 AmbientAirTemperature 1.7E-308;
BA_ "SPN" SG_ 2566845696 EngineAirInletTemperature 172;
BA_ "SigType" SG_ 2566845696 EngineAirInletTemperature 1.7E-308;
BA_ "SPN" SG_ 2566845696 RoadSurfaceTemperature 79;
BA_ "SigType" SG_ 2566845696 RoadSurfaceTemperature 1.7E-308;
BA_ "SPN" SG_ 2566844672 TwoSpeedAxleSwitch 69;
BA_ "SigType" SG_ 2566844672 TwoSpeedAxleSwitch 1.7E-308;
BA_ "SPN" SG_ 2566844672 ParkingBrakeSwitch 70;
BA_ "SigType" SG_ 2566844672 ParkingBrakeSwitch 1.7E-308;
BA_ "SPN" SG_ 2566844672 Wheel_BasedVehicleSpeed 84;
BA_ "SigType" SG_ 2566844672 Wheel_BasedVehicleSpeed 1.7E-308;
BA_ "SPN" SG_ 2566844672 CruiseCtrlActive 595;
BA_ "SigType" SG_ 2566844672 CruiseCtrlActive 1.7E-308;
BA_ "SPN" SG_ 2566844672 CruiseCtrlEnableSwitch 596;
BA_ "SigType" SG_ 2566844672 CruiseCtrlEnableSwitch 1.7E-308;
BA_ "SPN" SG_ 2566844672 BrakeSwitch 597;
BA_ "SigType" SG_ 2566844672 BrakeSwitch 1.7E-308;
BA_ "SPN" SG_ 2566844672 ClutchSwitch 598;
BA_ "SigType" SG_ 2566844672 ClutchSwitch 1.7E-308;
BA_ "SPN" SG_ 2566844672 CruiseCtrlSetSwitch 599;
BA_ "SigType" SG_ 2566844672 CruiseCtrlSetSwitch 1.7E-308;
BA_ "SPN" SG_ 2566844672 CruiseCtrlCoastSwitch 600;
BA_ "SigType" SG_ 2566844672 CruiseCtrlCoastSwitch 1.7E-308;
BA_ "SPN" SG_ 2566844672 CruiseCtrlResumeSwitch 601;
BA_ "SigType" SG_ 2566844672 CruiseCtrlResumeSwitch 1.7E-308;
BA_ "SPN" SG_ 2566844672 CruiseCtrlAccelerateSwitch 602;
BA_ "SigType" SG_ 2566844672 CruiseCtrlAccelerateSwitch 1.7E-308;
BA_ "SPN" SG_ 2566844672 CruiseCtrlSetSpeed 86;
BA_ "SigType" SG_ 2566844672 CruiseCtrlSetSpeed 1.7E-308;
BA_ "SPN" SG_ 2566844672 pOdometerDriveBit 523994;
BA_ "SigType" SG_ 2566844672 pOdometerDriveBit 1.7E-308;
BA_ "SPN" SG_ 2566844672 CruiseCtrlPauseSw 1633;
BA_ "SigType" SG_ 2566844672 CruiseCtrlPauseSw 1.7E-308;
BA_ "SPN" SG_ 2566844672 pCCMessageCounter 524080;
BA_ "SigType" SG_ 2566844672 pCCMessageCounter 1.7E-308;
BA_ "SPN" SG_ 2566844672 pCCChecksum 524079;
BA_ "SigType" SG_ 2566844672 pCCChecksum 1.7E-308;
BA_ "SPN" SG_ 2566844672 pCruiseEnableStatus 524108;
BA_ "SigType" SG_ 2566844672 pCruiseEnableStatus 1.7E-308;
BA_ "SigType" SG_ 2364539904 EngineTorqueMode 1.7E-308;
BA_ "SPN" SG_ 2364539904 DriversDemandEngine_PercTorque 512;
BA_ "SigType" SG_ 2364539904 DriversDemandEngine_PercTorque 1.7E-308;
BA_ "SPN" SG_ 2364539904 ActualEngine_PercTorque 513;
BA_ "SigType" SG_ 2364539904 ActualEngine_PercTorque 1.7E-308;
BA_ "SigType" SG_ 2364539904 EngineSpeed 1.7E-308;
BA_ "SPN" SG_ 2364539904 SourceAddress 1481;
BA_ "SigType" SG_ 2364539904 SourceAddress 1.7E-308;
BA_ "SPN" SG_ 2364539904 EngineStarterMode 1675;
BA_ "SigType" SG_ 2364539904 EngineStarterMode 1.7E-308;
BA_ "SPN" SG_ 2364539904 EngineDemand_PercentTorque 2432;
BA_ "SigType" SG_ 2364539904 EngineDemand_PercentTorque 1.7E-308;
BA_ "SPN" SG_ 2565866752 TransmissionSelectedGear 524;
BA_ "SigType" SG_ 2565866752 TransmissionSelectedGear 1.7E-308;
BA_ "SPN" SG_ 2565866752 TransmissionActualGearRatio 526;
BA_ "SigType" SG_ 2565866752 TransmissionActualGearRatio 1.7E-308;
BA_ "SPN" SG_ 2565866752 TransmissionCurrentGear 523;
BA_ "SigType" SG_ 2565866752 TransmissionCurrentGear 1.7E-308;
BA_ "SPN" SG_ 2565866752 TransmissionRqstedRange 162;
BA_ "SigType" SG_ 2565866752 TransmissionRqstedRange 1.7E-308;
BA_ "SPN" SG_ 2565866752 TransmissionCurrentRange 163;
BA_ "SigType" SG_ 2565866752 TransmissionCurrentRange 1.7E-308;
BA_ "SPN" SG_ 2566843904 EngineCoolantTemperature 110;
BA_ "SigType" SG_ 2566843904 EngineCoolantTemperature 1.7E-308;
BA_ "SPN" SG_ 2566843904 EngFuelTemperature1 174;
BA_ "SigType" SG_ 2566843904 EngFuelTemperature1 1.7E-308;
BA_ "SPN" SG_ 2566843904 EngineOilTemperature1 175;
BA_ "SigType" SG_ 2566843904 EngineOilTemperature1 1.7E-308;
BA_ "SPN" SG_ 2566843904 EngTurboOilTemperature 176;
BA_ "SigType" SG_ 2566843904 EngTurboOilTemperature 1.7E-308;
BA_ "SPN" SG_ 2566843904 EngineIntercoolerTemperature 52;
BA_ "SigType" SG_ 2566843904 EngineIntercoolerTemperature 1.7E-308;
BA_ "SPN" SG_ 2566843904 EngineIntercoolerThermosatOpen 1134;
BA_ "SigType" SG_ 2566843904 EngineIntercoolerThermosatOpen 1.7E-308;
BA_ "SPN" SG_ 2566844928 EngineFuelRate 183;
BA_ "SigType" SG_ 2566844928 EngineFuelRate 1.7E-308;
BA_ "SPN" SG_ 2566844928 InstantaneousFuelEconomy 184;
BA_ "SigType" SG_ 2566844928 InstantaneousFuelEconomy 1.7E-308;
BA_ "SPN" SG_ 2566844928 AverageFuelEconomy 185;
BA_ "SigType" SG_ 2566844928 AverageFuelEconomy 1.7E-308;
BA_ "SPN" SG_ 2566844928 EngineThrottlePosition 51;
BA_ "SigType" SG_ 2566844928 EngineThrottlePosition 1.7E-308;
BA_ "SPN" SG_ 2566845952 ParticulateTrapInletPressure 81;
BA_ "SigType" SG_ 2566845952 ParticulateTrapInletPressure 1.7E-308;
BA_ "SPN" SG_ 2566845952 EngTurboBoostPressure 102;
BA_ "SigType" SG_ 2566845952 EngTurboBoostPressure 1.7E-308;
BA_ "SPN" SG_ 2566845952 EngIntakeManifoldTemperature 105;
BA_ "SigType" SG_ 2566845952 EngIntakeManifoldTemperature 1.7E-308;
BA_ "SPN" SG_ 2566845952 EngAirInletPressure 106;
BA_ "SigType" SG_ 2566845952 EngAirInletPressure 1.7E-308;
BA_ "SPN" SG_ 2566845952 AirFilterDifferentialPressure 107;
BA_ "SigType" SG_ 2566845952 AirFilterDifferentialPressure 1.7E-308;
BA_ "SPN" SG_ 2566845952 EngExhaustGasTemperature 173;
BA_ "SigType" SG_ 2566845952 EngExhaustGasTemperature 1.7E-308;
BA_ "SPN" SG_ 2566845952 CoolantFilterDiffPressure 112;
BA_ "SigType" SG_ 2566845952 CoolantFilterDiffPressure 1.7E-308;
BA_ "SPN" SG_ 2566846208 NetBatteryCurrent 114;
BA_ "SigType" SG_ 2566846208 NetBatteryCurrent 1.7E-308;
BA_ "SPN" SG_ 2566846208 AlternatorCurrent 115;
BA_ "SigType" SG_ 2566846208 AlternatorCurrent 1.7E-308;
BA_ "SPN" SG_ 2566846208 ChargingSystemPotential 167;
BA_ "SigType" SG_ 2566846208 ChargingSystemPotential 1.7E-308;
BA_ "SPN" SG_ 2566846208 BatteryPotential 168;
BA_ "SigType" SG_ 2566846208 BatteryPotential 1.7E-308;
BA_ "SPN" SG_ 2566846208 KeyswitchBatteryPotential 158;
BA_ "SigType" SG_ 2566846208 KeyswitchBatteryPotential 1.7E-308;
BA_ "GenSigStartValue" SG_ 2566844806 pCruiseCntrlCounter 7;
BA_ "SPN" SG_ 2566844806 pCruiseCntrlCounter 524080;
BA_ "SPN" SG_ 2566844806 TwoSpeedAxleSwitch 69;
BA_ "SigType" SG_ 2566844806 TwoSpeedAxleSwitch 1.7E-308;
BA_ "SPN" SG_ 2566844806 ParkingBrakeSwitch 70;
BA_ "SigType" SG_ 2566844806 ParkingBrakeSwitch 1.7E-308;
BA_ "SPN" SG_ 2566844806 Wheel_BasedVehicleSpeed 84;
BA_ "SigType" SG_ 2566844806 Wheel_BasedVehicleSpeed 1.7E-308;
BA_ "SPN" SG_ 2566844806 CruiseCtrlActive 595;
BA_ "SigType" SG_ 2566844806 CruiseCtrlActive 1.7E-308;
BA_ "SPN" SG_ 2566844806 CruiseCtrlEnableSwitch 596;
BA_ "SigType" SG_ 2566844806 CruiseCtrlEnableSwitch 1.7E-308;
BA_ "SPN" SG_ 2566844806 BrakeSwitch 597;
BA_ "SigType" SG_ 2566844806 BrakeSwitch 1.7E-308;
BA_ "SPN" SG_ 2566844806 ClutchSwitch 598;
BA_ "SigType" SG_ 2566844806 ClutchSwitch 1.7E-308;
BA_ "SPN" SG_ 2566844806 CruiseCtrlSetSwitch 599;
BA_ "SigType" SG_ 2566844806 CruiseCtrlSetSwitch 1.7E-308;
BA_ "SPN" SG_ 2566844806 CruiseCtrlCoastSwitch 600;
BA_ "SigType" SG_ 2566844806 CruiseCtrlCoastSwitch 1.7E-308;
BA_ "SPN" SG_ 2566844806 CruiseCtrlResumeSwitch 601;
BA_ "SigType" SG_ 2566844806 CruiseCtrlResumeSwitch 1.7E-308;
BA_ "SPN" SG_ 2566844806 CruiseCtrlAccelerateSwitch 602;
BA_ "SigType" SG_ 2566844806 CruiseCtrlAccelerateSwitch 1.7E-308;
BA_ "SPN" SG_ 2566844806 CruiseCtrlSetSpeed 86;
BA_ "SigType" SG_ 2566844806 CruiseCtrlSetSpeed 1.7E-308;
BA_ "SPN" SG_ 2566844806 pOdometerDriveBit 523994;
BA_ "SigType" SG_ 2566844806 pOdometerDriveBit 1.7E-308;
BA_ "SPN" SG_ 2566844806 CruiseCtrlPauseSw 1633;
BA_ "SigType" SG_ 2566844806 CruiseCtrlPauseSw 1.7E-308;
BA_ "SPN" SG_ 2566844806 pCCChecksum 524079;
BA_ "SigType" SG_ 2566844806 pCCChecksum 1.7E-308;
BA_ "SPN" SG_ 2566844806 pCruiseEnableStatus 524108;
BA_ "SigType" SG_ 2566844806 pCruiseEnableStatus 1.7E-308;
BA_ "SPN" SG_ 2565537345 RqstedPGN 2540;
BA_ "SigType" SG_ 2565537345 RqstedPGN 1.7E-308;
BA_ "SPN" SG_ 2566857216 pVehicleSpeed 520573;
BA_ "SPN" SG_ 2566857216 pEngineTorque_Inst_Max 520576;
BA_ "SPN" SG_ 2566857216 pEngineTorque_Inst_Min 520575;
BA_ "SPN" SG_ 2566857216 pNorm_Acc_Pos 520574;
BA_ "SPN" SG_ 2566857216 pRawBrakeStatus 520572;
BA_ "SPN" SG_ 2365530368 pChecksum_520571 520571;
BA_ "SPN" SG_ 2365530368 pMessageCounter_520570 520570;
BA_ "SPN" SG_ 2365530368 pEngineSpeed_520569 520569;
BA_ "SPN" SG_ 2365530368 pEngineTorque_Driver_Demanded 520568;
BA_ "SPN" SG_ 2365530368 pEngineTorque 520567;
BA_ "SPN" SG_ 2365530368 pSource_Address_Ctrling_Device 520566;
BA_ "SPN" SG_ 2365530123 pEngCtlMode 520560;
BA_ "SigType" SG_ 2365530123 pEngCtlMode 1.7E-308;
BA_ "SPN" SG_ 2365530123 pEngReqSpeedLimit 520563;
BA_ "SigType" SG_ 2365530123 pEngReqSpeedLimit 1.7E-308;
BA_ "SPN" SG_ 2365530123 pChecksum_520565 520565;
BA_ "SPN" SG_ 2365530123 pMessageCounter_520564 524122;
BA_ "SPN" SG_ 2365530123 pEngCtlReq 520561;
BA_ "SigType" SG_ 2365530123 pEngCtlReq 1.7E-308;
BA_ "SPN" SG_ 2365530123 pEngReqTorqueLimit 520562;
BA_ "SigType" SG_ 2365530123 pEngReqTorqueLimit 1.7E-308;
BA_ "SigType" SG_ 2566834822 DTC5 7;
BA_ "SigType" SG_ 2566834822 DTC4 7;
BA_ "SigType" SG_ 2566834822 DTC3 7;
BA_ "SigType" SG_ 2566834822 DTC2 7;
BA_ "SigType" SG_ 2566834822 DTC1 7;
BA_ "SPN" SG_ 2566834822 DM_FlashRedStopLamp 3039;
BA_ "SPN" SG_ 2566834822 DM_FlashProtectLamp 3041;
BA_ "SPN" SG_ 2566834822 DM_FlashMalfuncIndicatorLamp 3038;
BA_ "SPN" SG_ 2566834822 DM_FlashAmberWarningLamp 3040;
BA_ "SPN" SG_ 2566834822 DM_ProtectLampStatus 987;
BA_ "SigType" SG_ 2566834822 DM_ProtectLampStatus 1.7E-308;
BA_ "SPN" SG_ 2566834822 DM_RedStopLampState 623;
BA_ "SigType" SG_ 2566834822 DM_RedStopLampState 1.7E-308;
BA_ "SPN" SG_ 2566834822 DM_AmberWrningLmpStatus 624;
BA_ "SigType" SG_ 2566834822 DM_AmberWrningLmpStatus 1.7E-308;
BA_ "SPN" SG_ 2566834822 DM_MalfuncnIndicatorLampStatus 1213;
BA_ "SigType" SG_ 2566834822 DM_MalfuncnIndicatorLampStatus 1.7E-308;
BA_ "GenSigStartValue" SG_ 2564358137 DM15_SAE_Reserved2 1;
BA_ "GenSigStartValue" SG_ 2564358137 DM15_SAE_Reserved 1;
BA_ "SPN" SG_ 2432656519 pInfotainmentJoystick2 520364;
BA_ "SPN" SG_ 2432656519 pInfotainmentJoystick1 520363;
BA_ "SPN" SG_ 2432656519 pInfotainmentRemoteButton01 524031;
BA_ "SigType" SG_ 2432656519 pInfotainmentRemoteButton01 1.7E-308;
BA_ "SPN" SG_ 2432656519 pInfotainmentRemoteButton02 524030;
BA_ "SigType" SG_ 2432656519 pInfotainmentRemoteButton02 1.7E-308;
BA_ "SPN" SG_ 2432656519 pInfotainmentRemoteButton03 524029;
BA_ "SigType" SG_ 2432656519 pInfotainmentRemoteButton03 1.7E-308;
BA_ "SPN" SG_ 2432656519 pInfotainmentRemoteButton04 524028;
BA_ "SigType" SG_ 2432656519 pInfotainmentRemoteButton04 1.7E-308;
BA_ "SPN" SG_ 2432656519 pInfotainmentRemoteButton05 524027;
BA_ "SigType" SG_ 2432656519 pInfotainmentRemoteButton05 1.7E-308;
BA_ "SPN" SG_ 2432656519 pInfotainmentRemoteButton06 524026;
BA_ "SigType" SG_ 2432656519 pInfotainmentRemoteButton06 1.7E-308;
BA_ "SPN" SG_ 2432656519 pInfotainmentRemoteButton07 524025;
BA_ "SigType" SG_ 2432656519 pInfotainmentRemoteButton07 1.7E-308;
BA_ "SPN" SG_ 2432656519 pInfotainmentRemoteButton08 524024;
BA_ "SigType" SG_ 2432656519 pInfotainmentRemoteButton08 1.7E-308;
BA_ "SPN" SG_ 2432656519 pInfotainmentRemoteButton09 524023;
BA_ "SigType" SG_ 2432656519 pInfotainmentRemoteButton09 1.7E-308;
BA_ "SPN" SG_ 2432656519 pInfotainmentRemoteButton10 524022;
BA_ "SigType" SG_ 2432656519 pInfotainmentRemoteButton10 1.7E-308;
BA_ "SPN" SG_ 2432656519 pInfotainmentRemoteButton11 524021;
BA_ "SigType" SG_ 2432656519 pInfotainmentRemoteButton11 1.7E-308;
BA_ "SPN" SG_ 2432656519 pInfotainmentRemoteButton12 524020;
BA_ "SigType" SG_ 2432656519 pInfotainmentRemoteButton12 1.7E-308;
BA_ "SPN" SG_ 2432656775 pOperatorButton29 524060;
BA_ "SPN" SG_ 2432656775 pOperatorButton1 524059;
BA_ "SigType" SG_ 2432656775 pOperatorButton1 1.7E-308;
BA_ "SPN" SG_ 2432656775 pOperatorButton2 524058;
BA_ "SigType" SG_ 2432656775 pOperatorButton2 1.7E-308;
BA_ "SPN" SG_ 2432656775 pOperatorButton3 524057;
BA_ "SigType" SG_ 2432656775 pOperatorButton3 1.7E-308;
BA_ "SPN" SG_ 2432656775 pOperatorButton4 524056;
BA_ "SigType" SG_ 2432656775 pOperatorButton4 1.7E-308;
BA_ "SPN" SG_ 2432656775 pOperatorButton5 524055;
BA_ "SigType" SG_ 2432656775 pOperatorButton5 1.7E-308;
BA_ "SPN" SG_ 2432656775 pOperatorButton6 524054;
BA_ "SigType" SG_ 2432656775 pOperatorButton6 1.7E-308;
BA_ "SPN" SG_ 2432656775 pOperatorButton7 524053;
BA_ "SigType" SG_ 2432656775 pOperatorButton7 1.7E-308;
BA_ "SPN" SG_ 2432656775 pOperatorButton8 524052;
BA_ "SigType" SG_ 2432656775 pOperatorButton8 1.7E-308;
BA_ "SPN" SG_ 2432656775 pOperatorButton9 524051;
BA_ "SigType" SG_ 2432656775 pOperatorButton9 1.7E-308;
BA_ "SPN" SG_ 2432656775 pOperatorButton10 524050;
BA_ "SigType" SG_ 2432656775 pOperatorButton10 1.7E-308;
BA_ "SPN" SG_ 2432656775 pOperatorButton11 524049;
BA_ "SigType" SG_ 2432656775 pOperatorButton11 1.7E-308;
BA_ "SPN" SG_ 2432656775 pOperatorButton12 524048;
BA_ "SigType" SG_ 2432656775 pOperatorButton12 1.7E-308;
BA_ "SPN" SG_ 2432656775 pOperatorButton13 524047;
BA_ "SigType" SG_ 2432656775 pOperatorButton13 1.7E-308;
BA_ "SPN" SG_ 2432656775 pOperatorButton14 524046;
BA_ "SigType" SG_ 2432656775 pOperatorButton14 1.7E-308;
BA_ "SPN" SG_ 2432656775 pOperatorButton15 524045;
BA_ "SigType" SG_ 2432656775 pOperatorButton15 1.7E-308;
BA_ "SPN" SG_ 2432656775 pOperatorButton16 524044;
BA_ "SigType" SG_ 2432656775 pOperatorButton16 1.7E-308;
BA_ "SPN" SG_ 2432656775 pOperatorButton17 524043;
BA_ "SigType" SG_ 2432656775 pOperatorButton17 1.7E-308;
BA_ "SPN" SG_ 2432656775 pOperatorButton18 524042;
BA_ "SigType" SG_ 2432656775 pOperatorButton18 1.7E-308;
BA_ "SPN" SG_ 2432656775 pOperatorButton19 524041;
BA_ "SigType" SG_ 2432656775 pOperatorButton19 1.7E-308;
BA_ "SPN" SG_ 2432656775 pOperatorButton20 524040;
BA_ "SigType" SG_ 2432656775 pOperatorButton20 1.7E-308;
BA_ "SPN" SG_ 2432656775 pOperatorButton21 524039;
BA_ "SigType" SG_ 2432656775 pOperatorButton21 1.7E-308;
BA_ "SPN" SG_ 2432656775 pOperatorButton22 524038;
BA_ "SigType" SG_ 2432656775 pOperatorButton22 1.7E-308;
BA_ "SPN" SG_ 2432656775 pOperatorButton23 524037;
BA_ "SigType" SG_ 2432656775 pOperatorButton23 1.7E-308;
BA_ "SPN" SG_ 2432656775 pOperatorButton24 524036;
BA_ "SigType" SG_ 2432656775 pOperatorButton24 1.7E-308;
BA_ "SPN" SG_ 2432656775 pOperatorButton25 524035;
BA_ "SigType" SG_ 2432656775 pOperatorButton25 1.7E-308;
BA_ "SPN" SG_ 2432656775 pOperatorButton26 524034;
BA_ "SigType" SG_ 2432656775 pOperatorButton26 1.7E-308;
BA_ "SPN" SG_ 2432656775 pOperatorButton27 520322;
BA_ "SigType" SG_ 2432656775 pOperatorButton27 1.7E-308;
BA_ "SPN" SG_ 2432656775 pOperatorButton28 524032;
BA_ "SigType" SG_ 2432656775 pOperatorButton28 1.7E-308;
BA_ "SPN" SG_ 2432656775 pSideStandStatus 524098;
BA_ "SigType" SG_ 2432656775 pSideStandStatus 1.7E-308;
BA_ "SPN" SG_ 2365449728 HydBrakePressCircuit1 2580;
BA_ "SigType" SG_ 2365449728 HydBrakePressCircuit1 1.7E-308;
BA_ "SPN" SG_ 2365449728 HydBrakePressCircuit2 2581;
BA_ "SigType" SG_ 2365449728 HydBrakePressCircuit2 1.7E-308;
BA_ "SPN" SG_ 2365449728 HydBrkPressWarnStateCir1 2584;
BA_ "SigType" SG_ 2365449728 HydBrkPressWarnStateCir1 1.7E-308;
BA_ "SPN" SG_ 2365449728 HydBrkPressWarnStateCir2 2585;
BA_ "SigType" SG_ 2365449728 HydBrkPressWarnStateCir2 1.7E-308;
BA_ "SPN" SG_ 2365449728 HydBrkPressSupplyStateCir1 2582;
BA_ "SigType" SG_ 2365449728 HydBrkPressSupplyStateCir1 1.7E-308;
BA_ "SPN" SG_ 2365449728 HydBrkPressSupplyStateCir2 2583;
BA_ "SigType" SG_ 2365449728 HydBrkPressSupplyStateCir2 1.7E-308;
BA_ "SPN" SG_ 2365449728 HydBrakeFluidLevelSwitch 2931;
BA_ "SigType" SG_ 2365449728 HydBrakeFluidLevelSwitch 1.7E-308;
BA_ "SPN" SG_ 2566884352 pCurrentRPMRatedTorque 520245;
BA_ "SigType" SG_ 2566884352 pCurrentRPMRatedTorque 1.7E-308;
BA_ "SPN" SG_ 2566884352 pEstimatedTorque 520246;
BA_ "SigType" SG_ 2566884352 pEstimatedTorque 1.7E-308;
BA_ "SPN" SG_ 2566884352 BrakeSwitch 597;
BA_ "SigType" SG_ 2566884352 BrakeSwitch 1.7E-308;
BA_ "SPN" SG_ 2566884352 MessageCounter_GM 4206;
BA_ "SigType" SG_ 2566884352 MessageCounter_GM 1.7E-308;
BA_ "SPN" SG_ 2566884352 MessageChecksum_GM 4207;
BA_ "SigType" SG_ 2566884352 MessageChecksum_GM 1.7E-308;
BA_ "SPN" SG_ 2566842396 CompassBearing 165;
BA_ "SigType" SG_ 2566842396 CompassBearing 1.7E-308;
BA_ "SPN" SG_ 2566877607 pVolumeUnitsSelected 524267;
BA_ "SPN" SG_ 2566877607 pTimeUnitsSelected 524268;
BA_ "SPN" SG_ 2566877607 pTemperatureUnitsSelected 524266;
BA_ "SPN" SG_ 2566877607 pPressureUnitsSelected 524269;
BA_ "SPN" SG_ 2566877607 pHighResTrip2Distance 524264;
BA_ "SPN" SG_ 2566877607 pDistanceUnitsSelected 524265;
BA_ "SPN" SG_ 2566877607 pTPMSLearningStatus 524104;
BA_ "SigType" SG_ 2566877607 pTPMSLearningStatus 1.7E-308;
BA_ "SPN" SG_ 2566877607 pDisplayStatus 524105;
BA_ "SigType" SG_ 2566877607 pDisplayStatus 1.7E-308;
BA_ "SigType" SG_ 2381320220 NMEA_SID 1.7E-308;
BA_ "SigType" SG_ 2381320220 NMEA_Data 1.7E-308;
BA_ "SigType" SG_ 2381320220 NMEA_Source 1.7E-308;
BA_ "SigType" SG_ 2381320220 NMEA_SystemTime 1.7E-308;
BA_ "SigType" SG_ 2314731804 NMEA_Latitude 1.7E-308;
BA_ "SigType" SG_ 2314731804 NMEA_Longitude 1.7E-308;
BA_ "SigType" SG_ 2583298844 NMEA_SID 1.7E-308;
BA_ "SigType" SG_ 2583298844 NMEA_HDOP 1.7E-308;
BA_ "SigType" SG_ 2583298844 NMEA_OpMode 1.7E-308;
BA_ "SigType" SG_ 2583298844 NMEA_SetMode 1.7E-308;
BA_ "SigType" SG_ 2583298844 NMEA_TDOP 1.7E-308;
BA_ "SigType" SG_ 2583298844 NMEA_VDOP 1.7E-308;
BA_ "SigType" SG_ 2314732060 NMEA_COG_Reference 1.7E-308;
BA_ "SigType" SG_ 2314732060 NMEA_CourseOverGround 1.7E-308;
BA_ "SigType" SG_ 2314732060 NMEA_SID 1.7E-308;
BA_ "SigType" SG_ 2314732060 NMEA_SpeedOverGround 1.7E-308;
VAL_ 2566910976 FI2_ThrttlBdyInitLrnValSave 3 "Not Available" 2 "Error" 1 "True" 0 "False" ;
VAL_ 2566910976 FI2_ThrttlBdyInitLearnSuccess 3 "Not Available" 2 "Error" 1 "True" 0 "False" ;
VAL_ 2566910976 FI2_ThrottleLimpHomeOpCondition 0 "Active" 3 "Not Available" 2 "Error" 1 "Inactive" ;
VAL_ 2566910976 FI2_SystemOnInput 3 "Not Available" 2 "Error" 1 "Input Low" 0 "Input High" ;
VAL_ 2566910976 FI2_SftyFuelCutoffCndn 3 "Not Available" 2 "Error" 1 "Inactive" 0 "Active" ;
VAL_ 2566910976 FI2_RvrsblInjCutoffCndn 3 "Not Available" 2 "Error" 1 "Inactive" 0 "Active" ;
VAL_ 2566910976 FI2_PTOEngagementStatus 3 "Not Available" 2 "Error" 1 "Inactive" 0 "Active" ;
VAL_ 2566910976 FI2_ParkBrakeSwitchIn 3 "Not Available" 2 "Error" 1 "Input Low" 0 "Input High" ;
VAL_ 2566910976 FI2_NeutralSwitchIn 3 "Not Available" 2 "Error" 1 "Input Low" 0 "Input High" ;
VAL_ 2566910976 FI2_IrrvrsblInjCutoffCndn 3 "Not Available" 2 "Error" 1 "Inactive" 0 "Active" ;
VAL_ 2566910976 FI2_ETCFncnMonitor 3 "Not Available" 2 "Error" 1 "Inactive" 0 "Active" ;
VAL_ 2566910976 FI2_ADCOutput 0 "Active" 1 "Inactive" 2 "Error" 3 "Not Available" ;
VAL_ 2566910976 FI2_RearDiffLockOutput 0 "Active" 1 "Inactive" 2 "Error" 3 "Not Available" ;
VAL_ 2566910976 FI2_AWDOutput 0 "Active" 1 "Inactive" 2 "Error" 3 "Not Available" ;
VAL_ 2566910976 FI2_BrakeSwitchInput 0 "Input High" 1 "Input Low" 2 "Error" 3 "Not Available" ;
VAL_ 2566910976 FI2_ADCSwitchInput 0 "Input High" 1 "Input Low" 2 "Error" 3 "Not Available" ;
VAL_ 2566910976 FI2_TurfModeInput 0 "Input High" 1 "Input Low" 2 "Error" 3 "Not Available" ;
VAL_ 2566910976 FI2_AWDSwitchInput 0 "Input High" 1 "Input Low" 2 "Error" 3 "Not Available" ;
VAL_ 2566910976 FI2_ReverseSwitchInput 0 "Input High" 1 "Input Low" 2 "Error" 3 "Not Available" ;
VAL_ 2566910976 FI2_ReverseLimitSwitchInput 0 "Input High" 1 "Input Low" 2 "Error" 3 "Not Available" ;
VAL_ 2566910976 FI2_ForwardLimitSwitchInput 0 "Input High" 1 "Input Low" 2 "Error" 3 "Not Available" ;
VAL_ 2566910976 FI2_EngineDirection 0 "Input High" 1 "Input Low" 2 "Error" 3 "Not Available" ;
VAL_ 2566910976 FI2_RevSpeedLimitOverrideInput 0 "Input High" 1 "Input Low" 2 "Error" 3 "Not Available" ;
VAL_ 2566910976 FI2_ReverseOverspeedSignal 0 "Input High" 1 "Input Low" 2 "Error" 3 "Not Available" ;
VAL_ 2566910976 FI2_RightTurnSignalInput 0 "Input High" 1 "Input Low" 2 "Error" 3 "Not Available" ;
VAL_ 2566910976 FI2_LeftTurnSignalInput 0 "Input High" 1 "Input Low" 2 "Error" 3 "Not Available" ;
VAL_ 2566910976 FI2_KickstandSwitchInput 0 "Input High" 1 "Input Low" 2 "Error" 3 "Not Available" ;
VAL_ 2566910976 FI2_ReflashEnableInputSignal 0 "Input High" 1 "Input Low" 2 "Error" 3 "Not Available" ;
VAL_ 2566910976 FI2_TPSLearnInputSignal 0 "Input High" 1 "Input Low" 2 "Error" 3 "Not Available" ;
VAL_ 2566910976 FI2_LowRangeSwitchInput 0 "Active" 1 "Inactive" 2 "Error" 3 "Not Available" ;
VAL_ 2566910976 FI2_ReverseMotorDriveInput 0 "Input High" 1 "Input Low" 2 "Error" 3 "Not Available" ;
VAL_ 2633984768 pADCModeAvailability 3 "Not Available" 2 "Error" 1 "ADC Mode Available" 0 "ADC Not Available" ;
VAL_ 2633984768 pAWDModeAvailability 3 "Not Available" 2 "Error" 1 "AWD Mode Available" 0 "AWD Not Available" ;
VAL_ 2633984768 pTurfModeAvailability 3 "Not Available" 2 "Error" 1 "Turf Mode Available" 0 "Turf Mode Not Available" ;
VAL_ 2633984768 pFuelLevelDataSource 0 "Analog (Direct to Device)" 1 "CAN" 2 "Error Indicator" 3 "Not Available" ;
VAL_ 2633984768 pVehicleUnitsConfig 0 "US12" 1 "US24" 2 "INT12" 3 "INT24" 4 "UK12" 5 "UK24" 6 "Available for future use" 14 "Error Indicator" 15 "Not Available" ;
VAL_ 2633984768 pFuelEconomyDataSource 0 "ECM to Calculate" 1 "Gauge to Calculate" 2 "Error Indicator" 3 "Description for the value '3'" ;
VAL_ 2633984768 pSeatBeltInputSource 0 "ECM to read switch input" 1 "Gauge to read switch input" 2 "Error" 3 "Not Available" ;
VAL_ 2566910720 FI3_OilPressSwIn 3 "Not Available" 2 "Error" 1 "Input Low" 0 "Input High" ;
VAL_ 2566910720 FI3_BrkSw2In 3 "Not Available" 2 "Error" 1 "Input Low" 0 "Input High" ;
VAL_ 2566910720 FI3_CruiseCtrlResumeOut 3 "Not Available" 2 "Error" 1 "Inactive" 0 "Active" ;
VAL_ 2566910720 FI3_CruiseCtrlResumeIn 3 "Not Available" 2 "Error" 1 "Inactive" 0 "Active" ;
VAL_ 2566910720 FI3_CruiseCtrlCancelIn 3 "Not Available" 2 "Error" 1 "Inactive" 0 "Active" ;
VAL_ 2566910720 FI3_TetherSwStatus 3 "Not Available" 2 "Error" 1 "Inactive" 0 "Active" ;
VAL_ 2566910720 FI3_DriveMode1Input 0 "Active" 1 "Inactive" 2 "Error" 3 "Not Available" ;
VAL_ 2566910720 FI3_DriveMode2Input 0 "Active" 1 "Inactive" 2 "Error" 3 "Not Available" ;
VAL_ 2566910720 FI3_DriveMode3Input 0 "Active" 1 "Inactive" 2 "Error" 3 "Not Available" ;
VAL_ 2566910720 FI3_DriverMode4Input 0 "Active" 1 "Inactive" 2 "Error" 3 "Not Available" ;
VAL_ 2566910720 FI3_DriverMode1Output 0 "Active" 1 "Inactive" 2 "Error" 3 "Not Available" ;
VAL_ 2566910720 FI3_DriverMode2Output 0 "Active" 1 "Inactive" 2 "Error" 3 "Not Available" ;
VAL_ 2566910720 FI3_DriverMode3Output 0 "Active" 1 "Inactive" 2 "Error" 3 "Not Available" ;
VAL_ 2566910720 FI3_DriverMode4Ouput 0 "Active" 1 "Inactive" 2 "Error" 3 "Not Available" ;
VAL_ 2566910720 FI3_PTOModeInput 0 "Active" 1 "Inactive" 2 "Error" 3 "Not Available" ;
VAL_ 2566910720 FI3_PTOModeOutput 0 "Active" 1 "Inactive" 2 "Error" 3 "Not Available" ;
VAL_ 2566910720 FI3_DriversNetEngagement 0 "Engage" 1 "Disengage" 2 "Error" 3 "Unavailable" ;
VAL_ 2566910720 FI3_DriversSeatbeltEngagement 0 "Engage" 1 "Disengage" 2 "Error" 3 "Unavailable" ;
VAL_ 2566910720 FI3_TiltLockInput 0 "Active" 1 "Inactive" 2 "Error" 3 "Not Available" ;
VAL_ 2566910720 FI3_WorkGroupLockInput 0 "Active" 1 "Inactive" 2 "Error" 3 "Not Available" ;
VAL_ 2566910720 FI3_OperatorPresenceInput 0 "Active" 1 "Inactive" 2 "Error" 3 "Not Available" ;
VAL_ 2566910720 FI3_WorkGroupLockOutput 0 "Active" 1 "Inactive" 2 "Error" 3 "Not Available" ;
VAL_ 2566910720 FI3_OperatorPresenceOutput 0 "Active" 1 "Inactive" 2 "Error" 3 "Not Available" ;
VAL_ 2566910720 FI3_FootOnCruiseInput 0 "Active" 1 "Inactive" 2 "Error" 3 "Not Available" ;
VAL_ 2566910720 FI3_CruiseInput 0 "Active" 1 "Inactive" 2 "Error" 3 "Not Available" ;
VAL_ 2566910720 FI3_TredalInput 0 "Active" 1 "Inactive" 2 "Error" 3 "Not Available" ;
VAL_ 2566910720 FI3_CruiseSpeedInput 0 "Active" 1 "Inactive" 2 "Error" 3 "Not Available" ;
VAL_ 2566910720 FI3_FootOnCruiseOutput 0 "Active" 1 "Inactive" 2 "Error" 3 "Not Available" ;
VAL_ 2566910720 FI3_CruiseOutput 0 "Active" 1 "Inactive" 2 "Error" 3 "Not Available" ;
VAL_ 2566910720 FI3_CruiseControltoSetSpeed 0 "Active" 1 "Inactive" 2 "Error" 3 "Not Available" ;
VAL_ 2566910720 FI3_WorkModeInput 0 "Active" 1 "Inactive" 2 "Error" 3 "Not Available" ;
VAL_ 2566910720 FI3_TiltLockOutput 0 "Active" 1 "Inactive" 2 "Error" 3 "Not Available" ;
VAL_ 2566910464 FI4_SeatbeltSw 3 "Not Available" 2 "Error" 1 "True" 0 "False" ;
VAL_ 2566910464 FI4_pSideStandSw 3 "Not Available" 2 "Error" 1 "Inactive" 0 "Active" ;
VAL_ 2566910464 FI4_DrvlnMomentaryRight 3 "Not Available" 2 "Error" 1 "True" 0 "False" ;
VAL_ 2566910464 FI4_DrvlnMomentaryLeft 3 "Not Available" 2 "Error" 1 "True" 0 "False" ;
VAL_ 2566910464 FI4_BrakeLightOutput 0 "Output Active" 1 "Output Inactive" 2 "Error" 3 "Not Available" ;
VAL_ 2566910464 FI4_FogLightInput 0 "Input HIGH" 1 "Input LOW" 2 "Error" 3 "Not Available" ;
VAL_ 2566910464 FI4_HazardLightOutput 0 "Output Active" 1 "Output Inactive" 2 "Error" 3 "Not Available" ;
VAL_ 2566910464 FI4_HazardSWInput 0 "Input HIGH" 1 "Input LOW" 2 "Error" 3 "Not Available" ;
VAL_ 2566910464 FI4_HeatGripDecSW 0 "Active" 1 "Inactive" 2 "Error" 3 "Not Available" ;
VAL_ 2566910464 FI4_HeatGripIncSW 0 "Active" 1 "Inactive" 2 "Error" 3 "Not Available" ;
VAL_ 2566910464 FI4_HighBeamOutput 0 "Output Active" 1 "Output Inactive" 2 "Error" 3 "Not Available" ;
VAL_ 2566910464 FI4_HornInput 0 "Input HIGH" 1 "Input LOW" 2 "Error" 3 "Not Available" ;
VAL_ 2566910464 FI4_HornOutput 0 "Output Active" 1 "Output Inactive" 2 "Error" 3 "Not Available" ;
VAL_ 2566910464 FI4_LeftFogLightOutput 0 "Output Active" 1 "Output Inactive" 2 "Error" 3 "Not Available" ;
VAL_ 2566910464 FI4_LFTurnSignalOutput 0 "Output Active" 1 "Output Inactive" 2 "Error" 3 "Not Available" ;
VAL_ 2566910464 FI4_LockInput 0 "Input HIGH" 1 "Input LOW" 2 "Error" 3 "Not Available" ;
VAL_ 2566910464 FI4_LowBeamOutput 0 "Output Active" 1 "Output Inactive" 2 "Error" 3 "Not Available" ;
VAL_ 2566910464 FI4_LowHighBeamInput 0 "Input HIGH" 1 "Input LOW" 2 "Error" 3 "Not Available" ;
VAL_ 2566910464 FI4_LRTurnSignalOutput 0 "Output Active" 1 "Output Inactive" 2 "Error" 3 "Not Available" ;
VAL_ 2566910464 FI4_pOperatorButton1 0 "Active" 1 "Inactive" 2 "Error" 3 "Not Available" ;
VAL_ 2566910464 FI4_RFTurnSignalOutput 0 "Output Active" 1 "Output Inactive" 2 "Error" 3 "Not Available" ;
VAL_ 2566910464 FI4_RightFogLightOutput 0 "Output Active" 1 "Output Inactive" 2 "Error" 3 "Not Available" ;
VAL_ 2566910464 FI4_RRTurnSignalOutput 0 "Output Active" 1 "Output Inactive" 2 "Error" 3 "Not Available" ;
VAL_ 2566910464 FI4_SecondaryAirValveCmd 0 "Output Active" 1 "Output Inactive" 2 "Error" 3 "Not Available" ;
VAL_ 2566910464 FI4_SecondaryAirValveOut 0 "Output Active" 1 "Output Inactive" 2 "Error" 3 "Not Available" ;
VAL_ 2566910464 FI4_TailLightOutput 0 "Output Active" 1 "Output Inactive" 2 "Error" 3 "Not Available" ;
VAL_ 2566910464 FI4_UnlockInput 0 "Input HIGH" 1 "Input LOW" 2 "Error" 3 "Not Available" ;
VAL_ 2566910464 FI4_WindshieldSWDownInput 0 "Input HIGH" 1 "Input LOW" 2 "Error" 3 "Not Available" ;
VAL_ 2566910464 FI4_WindshieldSWUpInput 0 "Input HIGH" 1 "Input LOW" 2 "Error" 3 "Not Available" ;
VAL_ 2566910464 FI4_pOperatorButton2 0 "Active" 1 "Inactive" 2 "Error" 3 "Not Available" ;
VAL_ 2566878604 pOperationMode 0 "Manned" 3 "Not Available" 2 "Error" 1 "Remote" ;
VAL_ 2566878604 pStartStopCmd 3 "Not Available" 2 "Error" 1 "Button Pressed" 0 "Button Not Pressed" ;
VAL_ 2566878464 pStartStopCmd 3 "Not Available" 2 "Error" 1 "Button Pressed" 0 "Button Not Pressed" ;
VAL_ 2566878464 pOperationMode 0 "Manned" 3 "Not Available" 2 "Error" 1 "Remote" ;
VAL_ 2566876928 pSecondaryAirValveControl 3 "Not Available" 2 "Error" 1 "Valve Request to be Enabled" 0 "Valve Request to be Disabled" ;
VAL_ 2566876416 pFootOnCruiseControlEnabled 3 "Not Available" 2 "Error" 1 "Foot on cruise control enabled" 0 "Foot on cruise control disabled" ;
VAL_ 2297441780 Vertical_Accel_Ext_Merit 3 "Not Available" 2 "error" 1 "Accel degraded" 0 "Accel fully functional" ;
VAL_ 2297441780 Longitudinal_Accel_Ext_Merit 3 "Not Available" 2 "error" 1 "Accel degraded" 0 "Accel fully functional" ;
VAL_ 2297441780 Lateral_Accel_Ext_Merit 3 "Not Available" 2 "error" 1 "Accel degraded" 0 "Accel fully functional" ;
VAL_ 2297441780 Accel_Sensor_Support_Var 3 "Supports 10ms Tx Rate Only" 2 "20ms rate supported" 1 "Reserved for SAE Assignment" 0 "Reserved for SAE Assignment" ;
VAL_ 2297441779 Vertical_Accel_Ext_Merit 3 "Not Available" 2 "error" 1 "Accel degraded" 0 "Accel fully functional" ;
VAL_ 2297441779 Longitudinal_Accel_Ext_Merit 3 "Not Available" 2 "error" 1 "Accel degraded" 0 "Accel fully functional" ;
VAL_ 2297441779 Lateral_Accel_Ext_Merit 3 "Not Available" 2 "error" 1 "Accel degraded" 0 "Accel fully functional" ;
VAL_ 2297441779 Accel_Sensor_Support_Var 3 "Supports 10ms Tx Rate Only" 2 "20ms rate supported" 1 "Reserved for SAE Assignment" 0 "Reserved for SAE Assignment" ;
VAL_ 2298415350 WATT_pSpeed_Lim_Cutback_Status 1 "Active" 0 "Inactive" ;
VAL_ 2298415350 WATT_pMotor_Therm_Cutback 1 "Active" 0 "Inactive" ;
VAL_ 2298415350 WATT_pMotor_Power_Cutback_Status 1 "Active" 0 "Inactive" ;
VAL_ 2298415350 WATT_pI_DC_Cutback_Status 1 "Active" 0 "Inactive" ;
VAL_ 2298415350 WATT_pController_Therm_Cutback 1 "Active" 0 "Inactive" ;
VAL_ 2298415351 WATT_pSpeed_Lim_Cutback_Status 1 "Active" 0 "Inactive" ;
VAL_ 2298415351 WATT_pMotor_Therm_Cutback 1 "Active" 0 "Inactive" ;
VAL_ 2298415351 WATT_pMotor_Power_Cutback_Status 1 "Active" 0 "Inactive" ;
VAL_ 2298415351 WATT_pI_DC_Cutback_Status 1 "Active" 0 "Inactive" ;
VAL_ 2298415351 WATT_pController_Therm_Cutback 1 "Active" 0 "Inactive" ;
VAL_ 2365523456 pModCtlAppliedState 15 "Not Availble" 14 "Error State" 13 "No Change - Checksum Error" 12 "Future Use" 11 "Future Use" 10 "Future Use" 9 "Future Use" 8 "Future Use" 7 "Future Use" 6 "Future Use" 5 "Future Use" 4 "Stay Awake Applied" 3 "Power Down Applied" 2 "Full Wakeup Applied" 1 "Partial Wakeup Applied" 0 "No Change Applied" ;
VAL_ 2365523456 pModCtlCmdState 15 "Not Available" 14 "Error State" 13 "Future Use" 12 "Future Use" 11 "Future Use" 10 "Future Use" 9 "Future Use" 8 "Future Use" 7 "Future Use" 6 "Future Use" 5 "Future Use" 4 "Stay Awak Requested" 3 "Power Down Requested" 2 "Full Wakeup Requested" 1 "Partial Wakeup Requested" 0 "No Change Requested" ;
VAL_ 2298415346 WATT_pSpeed_Lim_Cutback_Status 1 "Active" 0 "Inactive" ;
VAL_ 2298415346 WATT_pMotor_Therm_Cutback 1 "Active" 0 "Inactive" ;
VAL_ 2298415346 WATT_pMotor_Power_Cutback_Status 1 "Active" 0 "Inactive" ;
VAL_ 2298415346 WATT_pI_DC_Cutback_Status 1 "Active" 0 "Inactive" ;
VAL_ 2298415346 WATT_pController_Therm_Cutback 1 "Active" 0 "Inactive" ;
VAL_ 2298415345 WATT_pSpeed_Lim_Cutback_Status 1 "Active" 0 "Inactive" ;
VAL_ 2298415345 WATT_pMotor_Therm_Cutback 1 "Active" 0 "Inactive" ;
VAL_ 2298415345 WATT_pMotor_Power_Cutback_Status 1 "Active" 0 "Inactive" ;
VAL_ 2298415345 WATT_pI_DC_Cutback_Status 1 "Active" 0 "Inactive" ;
VAL_ 2298415345 WATT_pController_Therm_Cutback 1 "Active" 0 "Inactive" ;
VAL_ 2298415344 WATT_pSpeed_Lim_Cutback_Status 1 "Active" 0 "Inactive" ;
VAL_ 2298415344 WATT_pMotor_Therm_Cutback 1 "Active" 0 "Inactive" ;
VAL_ 2298415344 WATT_pMotor_Power_Cutback_Status 1 "Active" 0 "Inactive" ;
VAL_ 2298415344 WATT_pI_DC_Cutback_Status 1 "Active" 0 "Inactive" ;
VAL_ 2298415344 WATT_pController_Therm_Cutback 1 "Active" 0 "Inactive" ;
VAL_ 2298415343 WATT_pController_Therm_Cutback 1 "Active" 0 "Inactive" ;
VAL_ 2298415343 WATT_pSpeed_Lim_Cutback_Status 1 "Active" 0 "Inactive" ;
VAL_ 2298415343 WATT_pMotor_Therm_Cutback 1 "Active" 0 "Inactive" ;
VAL_ 2298415343 WATT_pMotor_Power_Cutback_Status 1 "Active" 0 "Inactive" ;
VAL_ 2298415343 WATT_pI_DC_Cutback_Status 1 "Active" 0 "Inactive" ;
VAL_ 2566844672 TwoSpeedAxleSwitch 0 "LowSpeedRange" 1 "HighSpeedRange" 2 "Error" 3 "NotAvailable" ;
VAL_ 2566844672 ParkingBrakeSwitch 0 "NotSet" 1 "Set" 2 "Error" 3 "NotAvailable" ;
VAL_ 2566844672 CruiseCtrlActive 0 "SwitchedOff" 1 "SwitchedOn" 2 "Error" 3 "NotAvailable" ;
VAL_ 2566844672 CruiseCtrlEnableSwitch 0 "Disabled" 1 "Enabled" 2 "Error" 3 "NotAvailable" ;
VAL_ 2566844672 BrakeSwitch 0 "PedalReleased" 1 "PedalDepressed" 2 "Error" 3 "NotAvailable" ;
VAL_ 2566844672 ClutchSwitch 0 "PedalReleased" 1 "PedalDepressed" 2 "Error" 3 "NotAvailable" ;
VAL_ 2566844672 CruiseCtrlSetSwitch 0 "NotSet" 1 "Set" 2 "Error" 3 "NotAvailable" ;
VAL_ 2566844672 CruiseCtrlCoastSwitch 0 "NotCoast" 1 "Coast" 2 "Error" 3 "NotAvailable" ;
VAL_ 2566844672 CruiseCtrlResumeSwitch 0 "NotResume" 1 "Resume" 2 "Error" 3 "NotAvailable" ;
VAL_ 2566844672 CruiseCtrlAccelerateSwitch 0 "NotAccelerate" 1 "Accelerate" 2 "Error" 3 "NotAvailable" ;
VAL_ 2566844672 pOdometerDriveBit 0 "State A" 1 "State B" 2 "Error" 3 "Not Available/Initialize" ;
VAL_ 2566844672 CruiseCtrlPauseSw 0 "Off" 1 "On" 2 "Error" 3 "Take No Action" ;
VAL_ 2566844672 pCruiseEnableStatus 0 "Not enabled." 1 "Enabled but not activated." 2 "Reserved" 14 "Error Indicator" 15 "Not Available" ;
VAL_ 2364539904 EngineTorqueMode 14 "Other" 15 "Not Available" 0 "NoRequest" 1 "Accelerator Pedal" 2 "Cruise Control" 3 "PTOGovernor" 4 "Road Speed Governor" 5 "ASR Control" 6 "Transmission" 7 "ABS Control" 8 "Torque Limiting" 9 "High Speed Governor" 10 "Braking System" 11 "Remote Accelerator" 12 "Service Procedure" 13 "Not Defined" ;
VAL_ 2364539904 EngineStarterMode 0 "Start not requested" 1 "Starter active, gear not engaged" 2 "Starter active, gear engaged" 3 "Start finished; starter not acti" 4 "Starter inhibited due to engine " 6 "Starter inhibited due to driveli" 7 "Starter inhibited due to active " 8 "Starter inhibited due to starter" 9 "Reserved" 14 "Error" 15 "Not available" ;
VAL_ 2565866752 TransmissionRqstedRange 21024 " R" 20512 " P" 20000 " N" 19488 " L" 18464 " H" ;
VAL_ 2566844806 TwoSpeedAxleSwitch 0 "LowSpeedRange" 1 "HighSpeedRange" 2 "Error" 3 "NotAvailable" ;
VAL_ 2566844806 ParkingBrakeSwitch 0 "NotSet" 1 "Set" 2 "Error" 3 "NotAvailable" ;
VAL_ 2566844806 CruiseCtrlActive 0 "SwitchedOff" 1 "SwitchedOn" 2 "Error" 3 "NotAvailable" ;
VAL_ 2566844806 CruiseCtrlEnableSwitch 0 "Disabled" 1 "Enabled" 2 "Error" 3 "NotAvailable" ;
VAL_ 2566844806 BrakeSwitch 0 "PedalReleased" 1 "PedalDepressed" 2 "Error" 3 "NotAvailable" ;
VAL_ 2566844806 ClutchSwitch 0 "PedalReleased" 1 "PedalDepressed" 2 "Error" 3 "NotAvailable" ;
VAL_ 2566844806 CruiseCtrlSetSwitch 0 "NotSet" 1 "Set" 2 "Error" 3 "NotAvailable" ;
VAL_ 2566844806 CruiseCtrlCoastSwitch 0 "NotCoast" 1 "Coast" 2 "Error" 3 "NotAvailable" ;
VAL_ 2566844806 CruiseCtrlResumeSwitch 0 "NotResume" 1 "Resume" 2 "Error" 3 "NotAvailable" ;
VAL_ 2566844806 CruiseCtrlAccelerateSwitch 0 "NotAccelerate" 1 "Accelerate" 2 "Error" 3 "NotAvailable" ;
VAL_ 2566844806 pOdometerDriveBit 0 "State A" 1 "State B" 2 "Error" 3 "Not Available/Initialize" ;
VAL_ 2566844806 CruiseCtrlPauseSw 0 "Off" 1 "On" 2 "Error" 3 "Take No Action" ;
VAL_ 2566844806 pCruiseEnableStatus 0 "Not enabled." 1 "Enabled but not activated." 2 "Reserved" 14 "Error Indicator" 15 "Not Available" ;
VAL_ 2565537345 RqstedPGN 255 "NotAvailable" ;
VAL_ 2566857216 pRawBrakeStatus 3 "Not Available" 2 "Error" 1 "Brake Pedal Depressed" 0 "Brake Pedal Released" ;
VAL_ 2365530123 pEngCtlMode 8 "Reserved for Future Use" 7 "Reserved for Future Use" 6 "Reserved for Future Use" 5 "Reserved for Future Use" 4 "Engine Torque Limit" 0 "No Control Request" 1 "Engine Speed Request" 2 "Engine Speed Limit" 3 "Engine Torque Request" 15 "Not Available" 14 "Error" 13 "Reserved for Future Use" 12 "Reserved for Future Use" 11 "Reserved for Future Use" 10 "Reserved for Future Use" 9 "Reserved for Future Use" ;
VAL_ 2365530123 pEngCtlReq 15 "Not Available" 14 "Error" 13 "Reserved for Future Use" 12 "Reserved for Future Use" 11 "Remote Accelerator" 10 "Braking System" 9 "High Speed Governor" 8 "Torque Limiting" 7 "ABS Control" 6 "Transmission Control" 5 "ASR Control" 4 "Road Speed Governor" 0 "Low Idle Governor/No Request" 1 "Accel Pedal/Operator Selection" 2 "Cruise Control" 3 "PTO Governor" ;
VAL_ 2566834822 DM_FlashRedStopLamp 3 "Unavailable / Do Not Flash" 2 "Reserved" 1 "Fast Flash (2 Hz, 50% DC)" 0 "Slow Flash (1 Hz, 50% DC)" ;
VAL_ 2566834822 DM_FlashProtectLamp 3 "Unavailable / Do Not Flash" 2 "Reserved" 1 "Fast Flash (2 Hz, 50% DC)" 0 "Slow Flash (1 Hz, 50% DC)" ;
VAL_ 2566834822 DM_FlashMalfuncIndicatorLamp 3 "Unavailable / Do Not Flash" 2 "Reserved" 1 "Fast Flash (2 Hz, 50% DC)" 0 "Slow Flash (1 Hz, 50% DC)" ;
VAL_ 2566834822 DM_FlashAmberWarningLamp 3 "Unavailable / Do Not Flash" 2 "Reserved" 1 "Fast Flash (2 Hz, 50% DC)" 0 "Slow Flash (1 Hz, 50% DC)" ;
VAL_ 2566834822 DM_ProtectLampStatus 0 "Lamp off" 1 "Lamp on" 2 "Reserved" 3 "Not available" ;
VAL_ 2566834822 DM_RedStopLampState 0 "Lamp off" 1 "Lamp on" 2 "Reserved" 3 "Not available" ;
VAL_ 2566834822 DM_AmberWrningLmpStatus 0 "Lamp off" 1 "Lamp on" 2 "Reserved" 3 "Not available" ;
VAL_ 2566834822 DM_MalfuncnIndicatorLampStatus 0 "Lamp off" 1 "Lamp on" 2 "Reserved" 3 "Not available" ;
VAL_ 2564358137 DM15_Seed 65535 "No Further Key required of Tool" 1 "Use Long Seed or Key" 0 "Seed Complete - send key" ;
VAL_ 2564358137 DM15_Error_Ind_EDC_Parameter 16777215 "No Error Indicator Available" 65540 "Transport NOT completed in time" 65539 "Transport NOT initiated in time" 65538 "NO response in the time allowed" 65537 "Too Many Retries" 65536 "Abort from external" 4103 "Security Error - NOT in Park" 4102 "Security Error - Engine running" 4101 "Security Error NOT in Dev mode" 4100 "Security Error NOT in Diag mode" 4099 "Security Error Invalid Key" 4098 "Security Error Invalid User Lvl" 4097 "Security Error Invalid Password" 4096 "Security Error General" 266 "DATA Error NAME unexpected value" 265 "DATA Error invalid value ranges" 264 "Addressing Error invalid bounds" 263 "Addressing Error wrong memory" 262 "Addressing Error requires trans" 261 "Addressing Error requires erase" 260 "Addressing Error requires erase" 259 "Addressing Error exceeded memory" 258 "Addressing Error Length invalid" 257 "Addressing Error bounds invalid" 256 "Addressing or DATA General Error" 36 "Internal failure preventing req" 35 "PROM did not verify on Write" 34 "FLASH did not verify on Write" 33 "RAM did not verify on Write" 32 "EDC parm not correct for data" 31 "Currently processing request" 23 "Currently processing Gen Req" 22 "Currently processing Boot Req" 19 "Currently processing Status Req" 18 "Currently processing Write Req" 17 "Currently processing Read Req" 16 "Currently processing Erase Req" 2 "Currently processing for another" 1 "Error NOT identified" 0 "No Error" ;
VAL_ 2564358137 DM15_EDCP_Extension 255 "No Error/EDC Parameter Available" 7 "Data in Error Indicator" 6 "Data in Error Indicator" 3 "More, Lower order EDC Parameter" 2 "More, Higher order EDC Parameter" 0 "Completed" ;
VAL_ 2564358137 DM15_Status 7 "Reserved" 6 "Reserved" 5 "Operation Failed" 4 "Operation Completed" 3 "Reserved" 2 "Reserved" 1 "Busy" 0 "Proceed" ;
VAL_ 2432656519 pInfotainmentJoystick2 5 "Center" 4 "Right" 3 "Left" 2 "Down" 1 "Up" 0 "Neutral" ;
VAL_ 2432656519 pInfotainmentJoystick1 5 "Center" 4 "Right" 3 "Left" 2 "Down" 1 "Up" 0 "Neutral" ;
VAL_ 2432656519 pInfotainmentRemoteButton01 0 "Not Pressed" 1 "Pressed" 2 "Error" 3 "Not Available" ;
VAL_ 2432656519 pInfotainmentRemoteButton02 0 "Not Pressed" 1 "Pressed" 2 "Error" 3 "Not Available" ;
VAL_ 2432656519 pInfotainmentRemoteButton03 0 "Not Pressed" 1 "Pressed" 2 "Error" 3 "Not Available" ;
VAL_ 2432656519 pInfotainmentRemoteButton04 0 "Not Pressed" 1 "Pressed" 2 "Error" 3 "Not Available" ;
VAL_ 2432656519 pInfotainmentRemoteButton05 0 "Not Pressed" 1 "Pressed" 2 "Error" 3 "Not Available" ;
VAL_ 2432656519 pInfotainmentRemoteButton06 0 "Not Pressed" 1 "Pressed" 2 "Error" 3 "Not Available" ;
VAL_ 2432656519 pInfotainmentRemoteButton07 0 "Not Pressed" 1 "Pressed" 2 "Error" 3 "Not Available" ;
VAL_ 2432656519 pInfotainmentRemoteButton08 0 "Not Pressed" 1 "Pressed" 2 "Error" 3 "Not Available" ;
VAL_ 2432656519 pInfotainmentRemoteButton09 0 "Not Pressed" 1 "Pressed" 2 "Error" 3 "Not Available" ;
VAL_ 2432656519 pInfotainmentRemoteButton10 0 "Not Pressed" 1 "Pressed" 2 "Error" 3 "Not Available" ;
VAL_ 2432656519 pInfotainmentRemoteButton11 0 "Not Pressed" 1 "Pressed" 2 "Error" 3 "Not Available" ;
VAL_ 2432656519 pInfotainmentRemoteButton12 0 "Not Pressed" 1 "Pressed" 2 "Error" 3 "Not Available" ;
VAL_ 2432656775 pOperatorButton29 3 "Not Available" 2 "Error" 1 "Button Pressed" 0 "Button Not Pressed" ;
VAL_ 2432656775 pOperatorButton1 0 "Not Pressed" 1 "Pressed" 2 "Error" 3 "Not Available" ;
VAL_ 2432656775 pOperatorButton2 0 "Active" 1 "Inactive" 2 "Error" 3 "Not Available" ;
VAL_ 2432656775 pOperatorButton3 0 "Not Pressed" 1 "Pressed" 2 "Error" 3 "Not Available" ;
VAL_ 2432656775 pOperatorButton4 0 "Not Pressed" 1 "Pressed" 2 "Error" 3 "Not Available" ;
VAL_ 2432656775 pOperatorButton5 0 "Not Pressed" 1 "Pressed" 2 "Error" 3 "Not Available" ;
VAL_ 2432656775 pOperatorButton6 0 "Not Pressed" 1 "Pressed" 2 "Error" 3 "Not Available" ;
VAL_ 2432656775 pOperatorButton7 0 "Not Pressed" 1 "Pressed" 2 "Error" 3 "Not Available" ;
VAL_ 2432656775 pOperatorButton8 0 "Not Pressed" 1 "Pressed" 2 "Error" 3 "Not Available" ;
VAL_ 2432656775 pOperatorButton9 0 "Not Pressed" 1 "Pressed" 2 "Error" 3 "Not Available" ;
VAL_ 2432656775 pOperatorButton10 0 "Not Pressed" 1 "Pressed" 2 "Error" 3 "Not Available" ;
VAL_ 2432656775 pOperatorButton11 0 "Not Pressed" 1 "Pressed" 2 "Error" 3 "Not Available" ;
VAL_ 2432656775 pOperatorButton12 0 "Not Pressed" 1 "Pressed" 2 "Error" 3 "Not Available" ;
VAL_ 2432656775 pOperatorButton13 0 "Not Pressed" 1 "Pressed" 2 "Error" 3 "Not Available" ;
VAL_ 2432656775 pOperatorButton14 0 "Not Pressed" 1 "Pressed" 2 "Error" 3 "Not Available" ;
VAL_ 2432656775 pOperatorButton15 0 "Not Pressed" 1 "Pressed" 2 "Error" 3 "Not Available" ;
VAL_ 2432656775 pOperatorButton16 0 "Not Pressed" 1 "Pressed" 2 "Error" 3 "Not Available" ;
VAL_ 2432656775 pOperatorButton17 0 "Not Pressed" 1 "Pressed" 2 "Error" 3 "Not Available" ;
VAL_ 2432656775 pOperatorButton18 0 "Not Pressed" 1 "Pressed" 2 "Error" 3 "Not Available" ;
VAL_ 2432656775 pOperatorButton19 0 "Not Pressed" 1 "Pressed" 2 "Error" 3 "Not Available" ;
VAL_ 2432656775 pOperatorButton20 0 "Not Pressed" 1 "Pressed" 2 "Error" 3 "Not Available" ;
VAL_ 2432656775 pOperatorButton21 0 "Not Pressed" 1 "Pressed" 2 "Error" 3 "Not Available" ;
VAL_ 2432656775 pOperatorButton22 0 "Not Pressed" 1 "Pressed" 2 "Error" 3 "Not Available" ;
VAL_ 2432656775 pOperatorButton23 0 "Not Pressed" 1 "Pressed" 2 "Error" 3 "Not Available" ;
VAL_ 2432656775 pOperatorButton24 0 "Not Pressed" 1 "Pressed" 2 "Error" 3 "Not Available" ;
VAL_ 2432656775 pOperatorButton25 0 "Not Pressed" 1 "Pressed" 2 "Error" 3 "Not Available" ;
VAL_ 2432656775 pOperatorButton26 0 "Not Pressed" 1 "Pressed" 2 "Error" 3 "Not Available" ;
VAL_ 2432656775 pOperatorButton27 0 "Not Pressed" 1 "Pressed" 2 "Error" 3 "Not Available" ;
VAL_ 2432656775 pOperatorButton28 0 "Not Pressed" 1 "Pressed" 2 "Error" 3 "Not Available" ;
VAL_ 2432656775 pSideStandStatus 3 "Not Available" 2 "Error Indicator" 1 "Side Stand Up" 0 "Side Stand Down" ;
VAL_ 2365449728 HydBrkPressWarnStateCir1 0 "Pressure level sufficient" 1 "Pressure level below warning lev" 2 "Error" 3 "Not available" ;
VAL_ 2365449728 HydBrkPressWarnStateCir2 0 "Pressure level sufficient" 1 "Pressure level below warning lev" 2 "Error" 3 "Not available" ;
VAL_ 2365449728 HydBrkPressSupplyStateCir1 0 "Supply is not reliable" 1 "Supply is reliable" 2 "Error" 3 "Not available" ;
VAL_ 2365449728 HydBrkPressSupplyStateCir2 0 "Supply is not reliable" 1 "Supply is reliable" 2 "Error" 3 "Not available" ;
VAL_ 2365449728 HydBrakeFluidLevelSwitch 0 "Fluid level is not sufficient" 1 "Fluid level is sufficient" 2 "Error" 3 "Not available" ;
VAL_ 2566884352 BrakeSwitch 0 "PedalReleased" 1 "PedalDepressed" 2 "Error" 3 "NotAvailable" ;
VAL_ 2566877607 pVolumeUnitsSelected 7 "Not Available" 6 "Error" 5 "Reserved" 4 "Reserved" 3 "Reserved" 2 "Imperial Gallons" 1 "Liters" 0 "Gallons" ;
VAL_ 2566877607 pTimeUnitsSelected 3 "Not Available" 2 "Error" 1 "24 Hour" 0 "12 Hour" ;
VAL_ 2566877607 pTemperatureUnitsSelected 3 "Not Avaialable" 2 "Error" 1 "Celsius" 0 "Farenheit" ;
VAL_ 2566877607 pPressureUnitsSelected 3 "Not Available" 2 "Error" 1 "Kilopascal (kPa)" 0 "Pounds Per Square Inch (PSI)" ;
VAL_ 2566877607 pDistanceUnitsSelected 3 "Not Available" 2 "Error" 1 "Kilometers" 0 "Miles" ;
VAL_ 2566877607 pTPMSLearningStatus 0 "Not Started" 1 "Request to start" 2 "Learning Left Front" 3 "Learning Right Front" 4 "Learning Left Rear" 5 "Learning Right Rear" 6 "Learning successfully completed" 13 "Request to end learning" 14 "Error - Failed Learning" 15 "Not Available" ;
VAL_ 2566877607 pDisplayStatus 0 "Info cant overide to full screen" 1 "User requested full screen" 2 "Info can overide to full screen" 14 "Info data is not shown" 15 "Not Available" ;
VAL_ 2381320220 NMEA_Source 0 "GPS" 1 "GLONASS" 2 "WWV" 3 "Local Cesium Clock" 4 "Local Rubidium Clock" 5 "Local Crystal Clock" 6 "Reserved Field" 15 "Null" ;
VAL_ 2583298844 NMEA_OpMode 0 "1D" 1 "2D" 2 "3D" 3 "Auto" 4 "Reserved Field" 6 "Error" 7 "Null" ;
VAL_ 2583298844 NMEA_SetMode 0 "1D" 1 "2D" 2 "3D" 3 "Auto" 4 "Reserved Field" 6 "Error" 7 "Null" ;
VAL_ 2314732060 NMEA_COG_Reference 0 "True" 1 "Magnetic" 2 "Error" 3 "Null" ;
